[part 1 of 11: packages /CANAnalyzer to /CANAnalyzer/CommunicationClusters]
AUTOSAR XML (schema 00051)
standard types defined: uint16, uint8, uint32, uint64
package /CANAnalyzer
  system CANCommunication: category=SYSTEM_DESCRIPTION, system-version=1.0.0
package /CANAnalyzer/CommunicationClusters
  can cluster CAN_FD_IPB_41
    can physical channel Channel
      frame AnalyticsDataFBD_HL: id 0x2AE, frame-length=48, can-addressing-mode=STANDARD, can-frame-rx-behavior=CAN-FD, can-frame-tx-behavior=CAN-FD
        pdu AnalyticsDataFBD_HL: length=48, unused-bit-pattern=0
          signal AnalyticsDataFBD_HL_Ranging_Uptime: start 0, 16 bit, little-endian, data-type-policy=OVERRIDE, base-type=uint16, compu {phys=raw; unit s}, range phys 0..65532
          signal AnalyticsDataFBD_HL_Ranging_Count: start 16, 16 bit, little-endian, data-type-policy=OVERRIDE, base-type=uint16, compu {phys=raw}, range phys 0..65532
          signal AnalyticsDataFBD_HL_RI_Low_New: start 32, 16 bit, little-endian, data-type-policy=OVERRIDE, base-type=uint16, compu {phys=raw}, range phys 0..65532
          signal AnalyticsDataFBD_HL_RI_Low_Cont: start 48, 16 bit, little-endian, data-type-policy=OVERRIDE, base-type=uint16, compu {phys=raw}, range phys 0..65532
          signal AnalyticsDataFBD_HL_RI_Med_New: start 64, 16 bit, little-endian, data-type-policy=OVERRIDE, base-type=uint16, compu {phys=raw}, range phys 0..65532
          signal AnalyticsDataFBD_HL_RI_Med_Cont: start 80, 16 bit, little-endian, data-type-policy=OVERRIDE, base-type=uint16, compu {phys=raw}, range phys 0..65532
          signal AnalyticsDataFBD_HL_RI_High_New: start 96, 16 bit, little-endian, data-type-policy=OVERRIDE, base-type=uint16, compu {phys=raw}, range phys 0..65532
          signal AnalyticsDataFBD_HL_RI_High_Cont: start 112, 16 bit, little-endian, data-type-policy=OVERRIDE, base-type=uint16, compu {phys=raw}, range phys 0..65532
          signal AnalyticsDataFBD_HL_Ranging_Sessions_Invalid: start 128, 16 bit, little-endian, data-type-policy=OVERRIDE, base-type=uint16, compu {phys=raw}, range phys 0..65532
          signal AnalyticsDataFBD_HL_Ranging_Sessions_FBD_Only_WUT: start 144, 16 bit, little-endian, data-type-policy=OVERRIDE, base-type=uint16, compu {phys=raw}, range phys 0..65532
          signal AnalyticsDataFBD_HL_Ranging_Sessions_FBD_Only_WUT_1: start 160, 16 bit, little-endian, data-type-policy=OVERRIDE, base-type=uint16, compu {phys=raw}, range phys 0..65532
          signal AnalyticsDataFBD_HL_Ranging_Sessions_FBD_Only_WUT_2: start 176, 16 bit, little-endian, data-type-policy=OVERRIDE, base-type=uint16, compu {phys=raw}, range phys 0..65532
          signal AnalyticsDataFBD_HL_Ranging_Sessions_FBD_Only_WUT_3: start 192, 16 bit, little-endian, data-type-policy=OVERRIDE, base-type=uint16, compu {phys=raw}, range phys 0..65532
          signal AnalyticsDataFBD_HL_Ranging_Sessions_FBD_Only_WUT_4: start 208, 16 bit, little-endian, data-type-policy=OVERRIDE, base-type=uint16, compu {phys=raw}, range phys 0..65532
          signal AnalyticsDataFBD_HL_Receive_Window_Ranging_CCC: start 224, 16 bit, little-endian, data-type-policy=OVERRIDE, base-type=uint16, compu {phys=raw*0.1; unit s}, range phys 0..6553.2
          signal AnalyticsDataFBD_HL_Receive_Window_Ranging_IDG: start 240, 16 bit, little-endian, data-type-policy=OVERRIDE, base-type=uint16, compu {phys=raw*0.1; unit s}, range phys 0..6553.2
          signal AnalyticsDataFBD_HL_Receive_Window_CPD: start 256, 16 bit, little-endian, data-type-policy=OVERRIDE, base-type=uint16, compu {phys=raw*0.1; unit s}, range phys 0..6553.2
          signal AnalyticsDataFBD_HL_FDD_Success_UWB: start 272, 16 bit, little-endian, data-type-policy=OVERRIDE, base-type=uint16, compu {phys=raw}, range phys 0..65532
          signal AnalyticsDataFBD_HL_FDD_Success_BLE: start 288, 16 bit, little-endian, data-type-policy=OVERRIDE, base-type=uint16, compu {phys=raw}, range phys 0..65532
          signal AnalyticsDataFBD_HL_RSSI_New: start 304, 16 bit, little-endian, data-type-policy=OVERRIDE, base-type=uint16, compu {phys=raw}, range phys 0..65532
          signal AnalyticsDataFBD_HL_RSSI_Cont: start 320, 16 bit, little-endian, data-type-policy=OVERRIDE, base-type=uint16, compu {phys=raw}, range phys 0..65532
          signal AnalyticsDataFBD_HL_BLE_Localization_Uptime: start 336, 16 bit, little-endian, data-type-policy=OVERRIDE, base-type=uint16, compu {phys=raw}, range phys 0..65532
          signal AnalyticsDataFBD_HL_BLE_Localization_Count: start 352, 16 bit, little-endian, data-type-policy=OVERRIDE, base-type=uint16, compu {phys=raw}, range phys 0..65532
          signal AnalyticsDataFBD_HL_Fallback_Mode_Duration: start 368, 16 bit, little-endian, data-type-policy=OVERRIDE, base-type=uint16, compu {phys=raw}, range phys 0..65532
      frame AnalyticsDataFBD_HM: id 0x2A9, frame-length=48, can-addressing-mode=STANDARD, can-frame-rx-behavior=CAN-FD, can-frame-tx-behavior=CAN-FD
        pdu AnalyticsDataFBD_HM: length=48, unused-bit-pattern=0
          signal AnalyticsDataFBD_HM_Ranging_Uptime: start 0, 16 bit, little-endian, data-type-policy=OVERRIDE, base-type=uint16, compu {phys=raw; unit s}, range phys 0..65532
          signal AnalyticsDataFBD_HM_Ranging_Count: start 16, 16 bit, little-endian, data-type-policy=OVERRIDE, base-type=uint16, compu {phys=raw}, range phys 0..65532
          signal AnalyticsDataFBD_HM_RI_Low_New: start 32, 16 bit, little-endian, data-type-policy=OVERRIDE, base-type=uint16, compu {phys=raw}, range phys 0..65532
          signal AnalyticsDataFBD_HM_RI_Low_Cont: start 48, 16 bit, little-endian, data-type-policy=OVERRIDE, base-type=uint16, compu {phys=raw}, range phys 0..65532
          signal AnalyticsDataFBD_HM_RI_Med_New: start 64, 16 bit, little-endian, data-type-policy=OVERRIDE, base-type=uint16, compu {phys=raw}, range phys 0..65532
          signal AnalyticsDataFBD_HM_RI_Med_Cont: start 80, 16 bit, little-endian, data-type-policy=OVERRIDE, base-type=uint16, compu {phys=raw}, range phys 0..65532
          signal AnalyticsDataFBD_HM_RI_High_New: start 96, 16 bit, little-endian, data-type-policy=OVERRIDE, base-type=uint16, compu {phys=raw}, range phys 0..65532
          signal AnalyticsDataFBD_HM_RI_High_Cont: start 112, 16 bit, little-endian, data-type-policy=OVERRIDE, base-type=uint16, compu {phys=raw}, range phys 0..65532
          signal AnalyticsDataFBD_HM_Ranging_Sessions_Invalid: start 128, 16 bit, little-endian, data-type-policy=OVERRIDE, base-type=uint16, compu {phys=raw}, range phys 0..65532
          signal AnalyticsDataFBD_HM_Ranging_Sessions_FBD_Only_WUT: start 144, 16 bit, little-endian, data-type-policy=OVERRIDE, base-type=uint16, compu {phys=raw}, range phys 0..65532
          signal AnalyticsDataFBD_HM_Ranging_Sessions_FBD_Only_WUT_1: start 160, 16 bit, little-endian, data-type-policy=OVERRIDE, base-type=uint16, compu {phys=raw}, range phys 0..65532
          signal AnalyticsDataFBD_HM_Ranging_Sessions_FBD_Only_WUT_2: start 176, 16 bit, little-endian, data-type-policy=OVERRIDE, base-type=uint16, compu {phys=raw}, range phys 0..65532
          signal AnalyticsDataFBD_HM_Ranging_Sessions_FBD_Only_WUT_3: start 192, 16 bit, little-endian, data-type-policy=OVERRIDE, base-type=uint16, compu {phys=raw}, range phys 0..65532
          signal AnalyticsDataFBD_HM_Ranging_Sessions_FBD_Only_WUT_4: start 208, 16 bit, little-endian, data-type-policy=OVERRIDE, base-type=uint16, compu {phys=raw}, range phys 0..65532
          signal AnalyticsDataFBD_HM_Receive_Window_Ranging_CCC: start 224, 16 bit, little-endian, data-type-policy=OVERRIDE, base-type=uint16, compu {phys=raw*0.1; unit s}, range phys 0..6553.2
          signal AnalyticsDataFBD_HM_Receive_Window_Ranging_IDG: start 240, 16 bit, little-endian, data-type-policy=OVERRIDE, base-type=uint16, compu {phys=raw*0.1; unit s}, range phys 0..6553.2
          signal AnalyticsDataFBD_HM_Receive_Window_CPD: start 256, 16 bit, little-endian, data-type-policy=OVERRIDE, base-type=uint16, compu {phys=raw*0.1; unit s}, range phys 0..6553.2
          signal AnalyticsDataFBD_HM_FDD_Success_UWB: start 272, 16 bit, little-endian, data-type-policy=OVERRIDE, base-type=uint16, compu {phys=raw}, range phys 0..65532
          signal AnalyticsDataFBD_HM_FDD_Success_BLE: start 288, 16 bit, little-endian, data-type-policy=OVERRIDE, base-type=uint16, compu {phys=raw}, range phys 0..65532
          signal AnalyticsDataFBD_HM_RSSI_New: start 304, 16 bit, little-endian, data-type-policy=OVERRIDE, base-type=uint16, compu {phys=raw}, range phys 0..65532
          signal AnalyticsDataFBD_HM_RSSI_Cont: start 320, 16 bit, little-endian, data-type-policy=OVERRIDE, base-type=uint16, compu {phys=raw}, range phys 0..65532
          signal AnalyticsDataFBD_HM_BLE_Localization_Uptime: start 336, 16 bit, little-endian, data-type-policy=OVERRIDE, base-type=uint16, compu {phys=raw}, range phys 0..65532
          signal AnalyticsDataFBD_HM_BLE_Localization_Count: start 352, 16 bit, little-endian, data-type-policy=OVERRIDE, base-type=uint16, compu {phys=raw}, range phys 0..65532
          signal AnalyticsDataFBD_HM_Fallback_Mode_Duration: start 368, 16 bit, little-endian, data-type-policy=OVERRIDE, base-type=uint16, compu {phys=raw}, range phys 0..65532
      frame AnalyticsDataFBD_HR: id 0x2AF, frame-length=48, can-addressing-mode=STANDARD, can-frame-rx-behavior=CAN-FD, can-frame-tx-behavior=CAN-FD
        pdu AnalyticsDataFBD_HR: length=48, unused-bit-pattern=0
          signal AnalyticsDataFBD_HR_Ranging_Uptime: start 0, 16 bit, little-endian, data-type-policy=OVERRIDE, base-type=uint16, compu {phys=raw; unit s}, range phys 0..65532
          signal AnalyticsDataFBD_HR_Ranging_Count: start 16, 16 bit, little-endian, data-type-policy=OVERRIDE, base-type=uint16, compu {phys=raw}, range phys 0..65532
          signal AnalyticsDataFBD_HR_RI_Low_New: start 32, 16 bit, little-endian, data-type-policy=OVERRIDE, base-type=uint16, compu {phys=raw}, range phys 0..65532
          signal AnalyticsDataFBD_HR_RI_Low_Cont: start 48, 16 bit, little-endian, data-type-policy=OVERRIDE, base-type=uint16, compu {phys=raw}, range phys 0..65532
          signal AnalyticsDataFBD_HR_RI_Med_New: start 64, 16 bit, little-endian, data-type-policy=OVERRIDE, base-type=uint16, compu {phys=raw}, range phys 0..65532
          signal AnalyticsDataFBD_HR_RI_Med_Cont: start 80, 16 bit, little-endian, data-type-policy=OVERRIDE, base-type=uint16, compu {phys=raw}, range phys 0..65532
          signal AnalyticsDataFBD_HR_RI_High_New: start 96, 16 bit, little-endian, data-type-policy=OVERRIDE, base-type=uint16, compu {phys=raw}, range phys 0..65532
          signal AnalyticsDataFBD_HR_RI_High_Cont: start 112, 16 bit, little-endian, data-type-policy=OVERRIDE, base-type=uint16, compu {phys=raw}, range phys 0..65532
          signal AnalyticsDataFBD_HR_Ranging_Sessions_Invalid: start 128, 16 bit, little-endian, data-type-policy=OVERRIDE, base-type=uint16, compu {phys=raw}, range phys 0..65532
          signal AnalyticsDataFBD_HR_Ranging_Sessions_FBD_Only_WUT: start 144, 16 bit, little-endian, data-type-policy=OVERRIDE, base-type=uint16, compu {phys=raw}, range phys 0..65532
          signal AnalyticsDataFBD_HR_Ranging_Sessions_FBD_Only_WUT_1: start 160, 16 bit, little-endian, data-type-policy=OVERRIDE, base-type=uint16, compu {phys=raw}, range phys 0..65532
          signal AnalyticsDataFBD_HR_Ranging_Sessions_FBD_Only_WUT_2: start 176, 16 bit, little-endian, data-type-policy=OVERRIDE, base-type=uint16, compu {phys=raw}, range phys 0..65532
          signal AnalyticsDataFBD_HR_Ranging_Sessions_FBD_Only_WUT_3: start 192, 16 bit, little-endian, data-type-policy=OVERRIDE, base-type=uint16, compu {phys=raw}, range phys 0..65532
          signal AnalyticsDataFBD_HR_Ranging_Sessions_FBD_Only_WUT_4: start 208, 16 bit, little-endian, data-type-policy=OVERRIDE, base-type=uint16, compu {phys=raw}, range phys 0..65532
          signal AnalyticsDataFBD_HR_Receive_Window_Ranging_CCC: start 224, 16 bit, little-endian, data-type-policy=OVERRIDE, base-type=uint16, compu {phys=raw*0.1; unit s}, range phys 0..6553.2
          signal AnalyticsDataFBD_HR_Receive_Window_Ranging_IDG: start 240, 16 bit, little-endian, data-type-policy=OVERRIDE, base-type=uint16, compu {phys=raw*0.1; unit s}, range phys 0..6553.2
          signal AnalyticsDataFBD_HR_Receive_Window_CPD: start 256, 16 bit, little-endian, data-type-policy=OVERRIDE, base-type=uint16, compu {phys=raw*0.1; unit s}, range phys 0..6553.2
          signal AnalyticsDataFBD_HR_FDD_Success_UWB: start 272, 16 bit, little-endian, data-type-policy=OVERRIDE, base-type=uint16, compu {phys=raw}, range phys 0..65532
          signal AnalyticsDataFBD_HR_FDD_Success_BLE: start 288, 16 bit, little-endian, data-type-policy=OVERRIDE, base-type=uint16, compu {phys=raw}, range phys 0..65532
          signal AnalyticsDataFBD_HR_RSSI_New: start 304, 16 bit, little-endian, data-type-policy=OVERRIDE, base-type=uint16, compu {phys=raw}, range phys 0..65532
          signal AnalyticsDataFBD_HR_RSSI_Cont: start 320, 16 bit, little-endian, data-type-policy=OVERRIDE, base-type=uint16, compu {phys=raw}, range phys 0..65532
          signal AnalyticsDataFBD_HR_BLE_Localization_Uptime: start 336, 16 bit, little-endian, data-type-policy=OVERRIDE, base-type=uint16, compu {phys=raw}, range phys 0..65532
          signal AnalyticsDataFBD_HR_BLE_Localization_Count: start 352, 16 bit, little-endian, data-type-policy=OVERRIDE, base-type=uint16, compu {phys=raw}, range phys 0..65532
          signal AnalyticsDataFBD_HR_Fallback_Mode_Duration: start 368, 16 bit, little-endian, data-type-policy=OVERRIDE, base-type=uint16, compu {phys=raw}, range phys 0..65532
      frame AnalyticsDataFBD_Miko: id 0x2AA, frame-length=48, can-addressing-mode=STANDARD, can-frame-rx-behavior=CAN-FD, can-frame-tx-behavior=CAN-FD
        pdu AnalyticsDataFBD_Miko: length=48, unused-bit-pattern=0
          signal AnalyticsDataFBD_Miko_Ranging_Uptime: start 0, 16 bit, little-endian, data-type-policy=OVERRIDE, base-type=uint16, compu {phys=raw; unit s}, range phys 0..65532
          signal AnalyticsDataFBD_Miko_Ranging_Count: start 16, 16 bit, little-endian, data-type-policy=OVERRIDE, base-type=uint16, compu {phys=raw}, range phys 0..65532
          signal AnalyticsDataFBD_Miko_RI_Low_New: start 32, 16 bit, little-endian, data-type-policy=OVERRIDE, base-type=uint16, compu {phys=raw}, range phys 0..65532
          signal AnalyticsDataFBD_Miko_RI_Low_Cont: start 48, 16 bit, little-endian, data-type-policy=OVERRIDE, base-type=uint16, compu {phys=raw}, range phys 0..65532
          signal AnalyticsDataFBD_Miko_RI_Med_New: start 64, 16 bit, little-endian, data-type-policy=OVERRIDE, base-type=uint16, compu {phys=raw}, range phys 0..65532
          signal AnalyticsDataFBD_Miko_RI_Med_Cont: start 80, 16 bit, little-endian, data-type-policy=OVERRIDE, base-type=uint16, compu {phys=raw}, range phys 0..65532
          signal AnalyticsDataFBD_Miko_RI_High_New: start 96, 16 bit, little-endian, data-type-policy=OVERRIDE, base-type=uint16, compu {phys=raw}, range phys 0..65532
          signal AnalyticsDataFBD_Miko_RI_High_Cont: start 112, 16 bit, little-endian, data-type-policy=OVERRIDE, base-type=uint16, compu {phys=raw}, range phys 0..65532
          signal AnalyticsDataFBD_Miko_Ranging_Sessions_Invalid: start 128, 16 bit, little-endian, data-type-policy=OVERRIDE, base-type=uint16, compu {phys=raw}, range phys 0..65532
          signal AnalyticsDataFBD_Miko_Ranging_Sessions_FBD_Only_WUT: start 144, 16 bit, little-endian, data-type-policy=OVERRIDE, base-type=uint16, compu {phys=raw}, range phys 0..65532
          signal AnalyticsDataFBD_Miko_Ranging_Sessions_FBD_Only_WUT_1: start 160, 16 bit, little-endian, data-type-policy=OVERRIDE, base-type=uint16, compu {phys=raw}, range phys 0..65532
          signal AnalyticsDataFBD_Miko_Ranging_Sessions_FBD_Only_WUT_2: start 176, 16 bit, little-endian, data-type-policy=OVERRIDE, base-type=uint16, compu {phys=raw}, range phys 0..65532
          signal AnalyticsDataFBD_Miko_Ranging_Sessions_FBD_Only_WUT_3: start 192, 16 bit, little-endian, data-type-policy=OVERRIDE, base-type=uint16, compu {phys=raw}, range phys 0..65532
          signal AnalyticsDataFBD_Miko_Ranging_Sessions_FBD_Only_WUT_4: start 208, 16 bit, little-endian, data-type-policy=OVERRIDE, base-type=uint16, compu {phys=raw}, range phys 0..65532
          signal AnalyticsDataFBD_Miko_Receive_Window_Ranging_CCC: start 224, 16 bit, little-endian, data-type-policy=OVERRIDE, base-type=uint16, compu {phys=raw*0.1; unit s}, range phys 0..6553.2
          signal AnalyticsDataFBD_Miko_Receive_Window_Ranging_IDG: start 240, 16 bit, little-endian, data-type-policy=OVERRIDE, base-type=uint16, compu {phys=raw*0.1; unit s}, range phys 0..6553.2
          signal AnalyticsDataFBD_Miko_Receive_Window_CPD: start 256, 16 bit, little-endian, data-type-policy=OVERRIDE, base-type=uint16, compu {phys=raw*0.1; unit s}, range phys 0..6553.2
          signal AnalyticsDataFBD_Miko_FDD_Success_UWB: start 272, 16 bit, little-endian, data-type-policy=OVERRIDE, base-type=uint16, compu {phys=raw}, range phys 0..65532
          signal AnalyticsDataFBD_Miko_FDD_Success_BLE: start 288, 16 bit, little-endian, data-type-policy=OVERRIDE, base-type=uint16, compu {phys=raw}, range phys 0..65532
          signal AnalyticsDataFBD_Miko_RSSI_New: start 304, 16 bit, little-endian, data-type-policy=OVERRIDE, base-type=uint16, compu {phys=raw}, range phys 0..65532
          signal AnalyticsDataFBD_Miko_RSSI_Cont: start 320, 16 bit, little-endian, data-type-policy=OVERRIDE, base-type=uint16, compu {phys=raw}, range phys 0..65532
          signal AnalyticsDataFBD_Miko_BLE_Localization_Uptime: start 336, 16 bit, little-endian, data-type-policy=OVERRIDE, base-type=uint16, compu {phys=raw}, range phys 0..65532
          signal AnalyticsDataFBD_Miko_BLE_Localization_Count: start 352, 16 bit, little-endian, data-type-policy=OVERRIDE, base-type=uint16, compu {phys=raw}, range phys 0..65532
          signal AnalyticsDataFBD_Miko_Fallback_Mode_Duration: start 368, 16 bit, little-endian, data-type-policy=OVERRIDE, base-type=uint16, compu {phys=raw}, range phys 0..65532
      frame AnalyticsDataFBD_MM: id 0x2B2, frame-length=48, can-addressing-mode=STANDARD, can-frame-rx-behavior=CAN-FD, can-frame-tx-behavior=CAN-FD
        pdu AnalyticsDataFBD_MM: length=48, unused-bit-pattern=0
          signal AnalyticsDataFBD_MM_Ranging_Uptime: start 0, 16 bit, little-endian, data-type-policy=OVERRIDE, base-type=uint16, compu {phys=raw; unit s}, range phys 0..65532
          signal AnalyticsDataFBD_MM_Ranging_Count: start 16, 16 bit, little-endian, data-type-policy=OVERRIDE, base-type=uint16, compu {phys=raw}, range phys 0..65532
          signal AnalyticsDataFBD_MM_RI_Low_New: start 32, 16 bit, little-endian, data-type-policy=OVERRIDE, base-type=uint16, compu {phys=raw}, range phys 0..65532
          signal AnalyticsDataFBD_MM_RI_Low_Cont: start 48, 16 bit, little-endian, data-type-policy=OVERRIDE, base-type=uint16, compu {phys=raw}, range phys 0..65532
          signal AnalyticsDataFBD_MM_RI_Med_New: start 64, 16 bit, little-endian, data-type-policy=OVERRIDE, base-type=uint16, compu {phys=raw}, range phys 0..65532
          signal AnalyticsDataFBD_MM_RI_Med_Cont: start 80, 16 bit, little-endian, data-type-policy=OVERRIDE, base-type=uint16, compu {phys=raw}, range phys 0..65532
          signal AnalyticsDataFBD_MM_RI_High_New: start 96, 16 bit, little-endian, data-type-policy=OVERRIDE, base-type=uint16, compu {phys=raw}, range phys 0..65532
          signal AnalyticsDataFBD_MM_RI_High_Cont: start 112, 16 bit, little-endian, data-type-policy=OVERRIDE, base-type=uint16, compu {phys=raw}, range phys 0..65532
          signal AnalyticsDataFBD_MM_Ranging_Sessions_Invalid: start 128, 16 bit, little-endian, data-type-policy=OVERRIDE, base-type=uint16, compu {phys=raw}, range phys 0..65532
          signal AnalyticsDataFBD_MM_Ranging_Sessions_FBD_Only_WUT: start 144, 16 bit, little-endian, data-type-policy=OVERRIDE, base-type=uint16, compu {phys=raw}, range phys 0..65532
          signal AnalyticsDataFBD_MM_Ranging_Sessions_FBD_Only_WUT_1: start 160, 16 bit, little-endian, data-type-policy=OVERRIDE, base-type=uint16, compu {phys=raw}, range phys 0..65532
          signal AnalyticsDataFBD_MM_Ranging_Sessions_FBD_Only_WUT_2: start 176, 16 bit, little-endian, data-type-policy=OVERRIDE, base-type=uint16, compu {phys=raw}, range phys 0..65532
          signal AnalyticsDataFBD_MM_Ranging_Sessions_FBD_Only_WUT_3: start 192, 16 bit, little-endian, data-type-policy=OVERRIDE, base-type=uint16, compu {phys=raw}, range phys 0..65532
          signal AnalyticsDataFBD_MM_Ranging_Sessions_FBD_Only_WUT_4: start 208, 16 bit, little-endian, data-type-policy=OVERRIDE, base-type=uint16, compu {phys=raw}, range phys 0..65532
          signal AnalyticsDataFBD_MM_Receive_Window_Ranging_CCC: start 224, 16 bit, little-endian, data-type-policy=OVERRIDE, base-type=uint16, compu {phys=raw*0.1; unit s}, range phys 0..6553.2
          signal AnalyticsDataFBD_MM_Receive_Window_Ranging_IDG: start 240, 16 bit, little-endian, data-type-policy=OVERRIDE, base-type=uint16, compu {phys=raw*0.1; unit s}, range phys 0..6553.2
          signal AnalyticsDataFBD_MM_Receive_Window_CPD: start 256, 16 bit, little-endian, data-type-policy=OVERRIDE, base-type=uint16, compu {phys=raw*0.1; unit s}, range phys 0..6553.2
          signal AnalyticsDataFBD_MM_FDD_Success_UWB: start 272, 16 bit, little-endian, data-type-policy=OVERRIDE, base-type=uint16, compu {phys=raw}, range phys 0..65532
          signal AnalyticsDataFBD_MM_FDD_Success_BLE: start 288, 16 bit, little-endian, data-type-policy=OVERRIDE, base-type=uint16, compu {phys=raw}, range phys 0..65532
          signal AnalyticsDataFBD_MM_RSSI_New: start 304, 16 bit, little-endian, data-type-policy=OVERRIDE, base-type=uint16, compu {phys=raw}, range phys 0..65532
          signal AnalyticsDataFBD_MM_RSSI_Cont: start 320, 16 bit, little-endian, data-type-policy=OVERRIDE, base-type=uint16, compu {phys=raw}, range phys 0..65532
          signal AnalyticsDataFBD_MM_BLE_Localization_Uptime: start 336, 16 bit, little-endian, data-type-policy=OVERRIDE, base-type=uint16, compu {phys=raw}, range phys 0..65532
          signal AnalyticsDataFBD_MM_BLE_Localization_Count: start 352, 16 bit, little-endian, data-type-policy=OVERRIDE, base-type=uint16, compu {phys=raw}, range phys 0..65532
          signal AnalyticsDataFBD_MM_Fallback_Mode_Duration: start 368, 16 bit, little-endian, data-type-policy=OVERRIDE, base-type=uint16, compu {phys=raw}, range phys 0..65532
      frame AnalyticsDataFBD_Trunk: id 0x2AB, frame-length=48, can-addressing-mode=STANDARD, can-frame-rx-behavior=CAN-FD, can-frame-tx-behavior=CAN-FD
        pdu AnalyticsDataFBD_Trunk: length=48, unused-bit-pattern=0
          signal AnalyticsDataFBD_Trunk_Ranging_Uptime: start 0, 16 bit, little-endian, data-type-policy=OVERRIDE, base-type=uint16, compu {phys=raw; unit s}, range phys 0..65532
          signal AnalyticsDataFBD_Trunk_Ranging_Count: start 16, 16 bit, little-endian, data-type-policy=OVERRIDE, base-type=uint16, compu {phys=raw}, range phys 0..65532
          signal AnalyticsDataFBD_Trunk_RI_Low_New: start 32, 16 bit, little-endian, data-type-policy=OVERRIDE, base-type=uint16, compu {phys=raw}, range phys 0..65532
          signal AnalyticsDataFBD_Trunk_RI_Low_Cont: start 48, 16 bit, little-endian, data-type-policy=OVERRIDE, base-type=uint16, compu {phys=raw}, range phys 0..65532
          signal AnalyticsDataFBD_Trunk_RI_Med_New: start 64, 16 bit, little-endian, data-type-policy=OVERRIDE, base-type=uint16, compu {phys=raw}, range phys 0..65532
          signal AnalyticsDataFBD_Trunk_RI_Med_Cont: start 80, 16 bit, little-endian, data-type-policy=OVERRIDE, base-type=uint16, compu {phys=raw}, range phys 0..65532
          signal AnalyticsDataFBD_Trunk_RI_High_New: start 96, 16 bit, little-endian, data-type-policy=OVERRIDE, base-type=uint16, compu {phys=raw}, range phys 0..65532
          signal AnalyticsDataFBD_Trunk_RI_High_Cont: start 112, 16 bit, little-endian, data-type-policy=OVERRIDE, base-type=uint16, compu {phys=raw}, range phys 0..65532
          signal AnalyticsDataFBD_Trunk_Ranging_Sessions_Invalid: start 128, 16 bit, little-endian, data-type-policy=OVERRIDE, base-type=uint16, compu {phys=raw}, range phys 0..65532
          signal AnalyticsDataFBD_Trunk_Ranging_Sessions_FBD_Only_WUT: start 144, 16 bit, little-endian, data-type-policy=OVERRIDE, base-type=uint16, compu {phys=raw}, range phys 0..65532
          signal AnalyticsDataFBD_Trunk_Ranging_Sessions_FBD_Only_WUT_1: start 160, 16 bit, little-endian, data-type-policy=OVERRIDE, base-type=uint16, compu {phys=raw}, range phys 0..65532
          signal AnalyticsDataFBD_Trunk_Ranging_Sessions_FBD_Only_WUT_2: start 176, 16 bit, little-endian, data-type-policy=OVERRIDE, base-type=uint16, compu {phys=raw}, range phys 0..65532
          signal AnalyticsDataFBD_Trunk_Ranging_Sessions_FBD_Only_WUT_3: start 192, 16 bit, little-endian, data-type-policy=OVERRIDE, base-type=uint16, compu {phys=raw}, range phys 0..65532
          signal AnalyticsDataFBD_Trunk_Ranging_Sessions_FBD_Only_WUT_4: start 208, 16 bit, little-endian, data-type-policy=OVERRIDE, base-type=uint16, compu {phys=raw}, range phys 0..65532
          signal AnalyticsDataFBD_Trunk_Receive_Window_Ranging_CCC: start 224, 16 bit, little-endian, data-type-policy=OVERRIDE, base-type=uint16, compu {phys=raw*0.1; unit s}, range phys 0..6553.2
          signal AnalyticsDataFBD_Trunk_Receive_Window_Ranging_IDG: start 240, 16 bit, little-endian, data-type-policy=OVERRIDE, base-type=uint16, compu {phys=raw*0.1; unit s}, range phys 0..6553.2
          signal AnalyticsDataFBD_Trunk_Receive_Window_CPD: start 256, 16 bit, little-endian, data-type-policy=OVERRIDE, base-type=uint16, compu {phys=raw*0.1; unit s}, range phys 0..6553.2
          signal AnalyticsDataFBD_Trunk_FDD_Success_UWB: start 272, 16 bit, little-endian, data-type-policy=OVERRIDE, base-type=uint16, compu {phys=raw}, range phys 0..65532
          signal AnalyticsDataFBD_Trunk_FDD_Success_BLE: start 288, 16 bit, little-endian, data-type-policy=OVERRIDE, base-type=uint16, compu {phys=raw}, range phys 0..65532
          signal AnalyticsDataFBD_Trunk_RSSI_New: start 304, 16 bit, little-endian, data-type-policy=OVERRIDE, base-type=uint16, compu {phys=raw}, range phys 0..65532
          signal AnalyticsDataFBD_Trunk_RSSI_Cont: start 320, 16 bit, little-endian, data-type-policy=OVERRIDE, base-type=uint16, compu {phys=raw}, range phys 0..65532
          signal AnalyticsDataFBD_Trunk_BLE_Localization_Uptime: start 336, 16 bit, little-endian, data-type-policy=OVERRIDE, base-type=uint16, compu {phys=raw}, range phys 0..65532
          signal AnalyticsDataFBD_Trunk_BLE_Localization_Count: start 352, 16 bit, little-endian, data-type-policy=OVERRIDE, base-type=uint16, compu {phys=raw}, range phys 0..65532
          signal AnalyticsDataFBD_Trunk_Fallback_Mode_Duration: start 368, 16 bit, little-endian, data-type-policy=OVERRIDE, base-type=uint16, compu {phys=raw}, range phys 0..65532
      frame AnalyticsDataFBD_VL: id 0x2AC, frame-length=48, can-addressing-mode=STANDARD, can-frame-rx-behavior=CAN-FD, can-frame-tx-behavior=CAN-FD
        pdu AnalyticsDataFBD_VL: length=48, unused-bit-pattern=0
          signal AnalyticsDataFBD_VL_Ranging_Uptime: start 0, 16 bit, little-endian, data-type-policy=OVERRIDE, base-type=uint16, compu {phys=raw; unit s}, range phys 0..65532
          signal AnalyticsDataFBD_VL_Ranging_Count: start 16, 16 bit, little-endian, data-type-policy=OVERRIDE, base-type=uint16, compu {phys=raw}, range phys 0..65532
          signal AnalyticsDataFBD_VL_RI_Low_New: start 32, 16 bit, little-endian, data-type-policy=OVERRIDE, base-type=uint16, compu {phys=raw}, range phys 0..65532
          signal AnalyticsDataFBD_VL_RI_Low_Cont: start 48, 16 bit, little-endian, data-type-policy=OVERRIDE, base-type=uint16, compu {phys=raw}, range phys 0..65532
          signal AnalyticsDataFBD_VL_RI_Med_New: start 64, 16 bit, little-endian, data-type-policy=OVERRIDE, base-type=uint16, compu {phys=raw}, range phys 0..65532
          signal AnalyticsDataFBD_VL_RI_Med_Cont: start 80, 16 bit, little-endian, data-type-policy=OVERRIDE, base-type=uint16, compu {phys=raw}, range phys 0..65532
          signal AnalyticsDataFBD_VL_RI_High_New: start 96, 16 bit, little-endian, data-type-policy=OVERRIDE, base-type=uint16, compu {phys=raw}, range phys 0..65532
          signal AnalyticsDataFBD_VL_RI_High_Cont: start 112, 16 bit, little-endian, data-type-policy=OVERRIDE, base-type=uint16, compu {phys=raw}, range phys 0..65532
          signal AnalyticsDataFBD_VL_Ranging_Sessions_Invalid: start 128, 16 bit, little-endian, data-type-policy=OVERRIDE, base-type=uint16, compu {phys=raw}, range phys 0..65532
          signal AnalyticsDataFBD_VL_Ranging_Sessions_FBD_Only_WUT: start 144, 16 bit, little-endian, data-type-policy=OVERRIDE, base-type=uint16, compu {phys=raw}, range phys 0..65532
          signal AnalyticsDataFBD_VL_Ranging_Sessions_FBD_Only_WUT_1: start 160, 16 bit, little-endian, data-type-policy=OVERRIDE, base-type=uint16, compu {phys=raw}, range phys 0..65532
          signal AnalyticsDataFBD_VL_Ranging_Sessions_FBD_Only_WUT_2: start 176, 16 bit, little-endian, data-type-policy=OVERRIDE, base-type=uint16, compu {phys=raw}, range phys 0..65532
          signal AnalyticsDataFBD_VL_Ranging_Sessions_FBD_Only_WUT_3: start 192, 16 bit, little-endian, data-type-policy=OVERRIDE, base-type=uint16, compu {phys=raw}, range phys 0..65532
          signal AnalyticsDataFBD_VL_Ranging_Sessions_FBD_Only_WUT_4: start 208, 16 bit, little-endian, data-type-policy=OVERRIDE, base-type=uint16, compu {phys=raw}, range phys 0..65532
          signal AnalyticsDataFBD_VL_Receive_Window_Ranging_CCC: start 224, 16 bit, little-endian, data-type-policy=OVERRIDE, base-type=uint16, compu {phys=raw*0.1; unit s}, range phys 0..6553.2
          signal AnalyticsDataFBD_VL_Receive_Window_Ranging_IDG: start 240, 16 bit, little-endian, data-type-policy=OVERRIDE, base-type=uint16, compu {phys=raw*0.1; unit s}, range phys 0..6553.2
          signal AnalyticsDataFBD_VL_Receive_Window_CPD: start 256, 16 bit, little-endian, data-type-policy=OVERRIDE, base-type=uint16, compu {phys=raw*0.1; unit s}, range phys 0..6553.2
          signal AnalyticsDataFBD_VL_FDD_Success_UWB: start 272, 16 bit, little-endian, data-type-policy=OVERRIDE, base-type=uint16, compu {phys=raw}, range phys 0..65532
          signal AnalyticsDataFBD_VL_FDD_Success_BLE: start 288, 16 bit, little-endian, data-type-policy=OVERRIDE, base-type=uint16, compu {phys=raw}, range phys 0..65532
          signal AnalyticsDataFBD_VL_RSSI_New: start 304, 16 bit, little-endian, data-type-policy=OVERRIDE, base-type=uint16, compu {phys=raw}, range phys 0..65532
          signal AnalyticsDataFBD_VL_RSSI_Cont: start 320, 16 bit, little-endian, data-type-policy=OVERRIDE, base-type=uint16, compu {phys=raw}, range phys 0..65532
          signal AnalyticsDataFBD_VL_BLE_Localization_Uptime: start 336, 16 bit, little-endian, data-type-policy=OVERRIDE, base-type=uint16, compu {phys=raw}, range phys 0..65532
          signal AnalyticsDataFBD_VL_BLE_Localization_Count: start 352, 16 bit, little-endian, data-type-policy=OVERRIDE, base-type=uint16, compu {phys=raw}, range phys 0..65532
          signal AnalyticsDataFBD_VL_Fallback_Mode_Duration: start 368, 16 bit, little-endian, data-type-policy=OVERRIDE, base-type=uint16, compu {phys=raw}, range phys 0..65532
      frame AnalyticsDataFBD_VM: id 0x2A8, frame-length=48, can-addressing-mode=STANDARD, can-frame-rx-behavior=CAN-FD, can-frame-tx-behavior=CAN-FD
        pdu AnalyticsDataFBD_VM: length=48, unused-bit-pattern=0
          signal AnalyticsDataFBD_VM_Ranging_Uptime: start 0, 16 bit, little-endian, data-type-policy=OVERRIDE, base-type=uint16, compu {phys=raw; unit s}, range phys 0..65532
          signal AnalyticsDataFBD_VM_Ranging_Count: start 16, 16 bit, little-endian, data-type-policy=OVERRIDE, base-type=uint16, compu {phys=raw}, range phys 0..65532
          signal AnalyticsDataFBD_VM_RI_Low_New: start 32, 16 bit, little-endian, data-type-policy=OVERRIDE, base-type=uint16, compu {phys=raw}, range phys 0..65532
          signal AnalyticsDataFBD_VM_RI_Low_Cont: start 48, 16 bit, little-endian, data-type-policy=OVERRIDE, base-type=uint16, compu {phys=raw}, range phys 0..65532
          signal AnalyticsDataFBD_VM_RI_Med_New: start 64, 16 bit, little-endian, data-type-policy=OVERRIDE, base-type=uint16, compu {phys=raw}, range phys 0..65532
          signal AnalyticsDataFBD_VM_RI_Med_Cont: start 80, 16 bit, little-endian, data-type-policy=OVERRIDE, base-type=uint16, compu {phys=raw}, range phys 0..65532
          signal AnalyticsDataFBD_VM_RI_High_New: start 96, 16 bit, little-endian, data-type-policy=OVERRIDE, base-type=uint16, compu {phys=raw}, range phys 0..65532
          signal AnalyticsDataFBD_VM_RI_High_Cont: start 112, 16 bit, little-endian, data-type-policy=OVERRIDE, base-type=uint16, compu {phys=raw}, range phys 0..65532
          signal AnalyticsDataFBD_VM_Ranging_Sessions_Invalid: start 128, 16 bit, little-endian, data-type-policy=OVERRIDE, base-type=uint16, compu {phys=raw}, range phys 0..65532
          signal AnalyticsDataFBD_VM_Ranging_Sessions_FBD_Only_WUT: start 144, 16 bit, little-endian, data-type-policy=OVERRIDE, base-type=uint16, compu {phys=raw}, range phys 0..65532
          signal AnalyticsDataFBD_VM_Ranging_Sessions_FBD_Only_WUT_1: start 160, 16 bit, little-endian, data-type-policy=OVERRIDE, base-type=uint16, compu {phys=raw}, range phys 0..65532
          signal AnalyticsDataFBD_VM_Ranging_Sessions_FBD_Only_WUT_2: start 176, 16 bit, little-endian, data-type-policy=OVERRIDE, base-type=uint16, compu {phys=raw}, range phys 0..65532
          signal AnalyticsDataFBD_VM_Ranging_Sessions_FBD_Only_WUT_3: start 192, 16 bit, little-endian, data-type-policy=OVERRIDE, base-type=uint16, compu {phys=raw}, range phys 0..65532
          signal AnalyticsDataFBD_VM_Ranging_Sessions_FBD_Only_WUT_4: start 208, 16 bit, little-endian, data-type-policy=OVERRIDE, base-type=uint16, compu {phys=raw}, range phys 0..65532
          signal AnalyticsDataFBD_VM_Receive_Window_Ranging_CCC: start 224, 16 bit, little-endian, data-type-policy=OVERRIDE, base-type=uint16, compu {phys=raw*0.1; unit s}, range phys 0..6553.2
          signal AnalyticsDataFBD_VM_Receive_Window_Ranging_IDG: start 240, 16 bit, little-endian, data-type-policy=OVERRIDE, base-type=uint16, compu {phys=raw*0.1; unit s}, range phys 0..6553.2
          signal AnalyticsDataFBD_VM_Receive_Window_CPD: start 256, 16 bit, little-endian, data-type-policy=OVERRIDE, base-type=uint16, compu {phys=raw*0.1; unit s}, range phys 0..6553.2
          signal AnalyticsDataFBD_VM_FDD_Success_UWB: start 272, 16 bit, little-endian, data-type-policy=OVERRIDE, base-type=uint16, compu {phys=raw}, range phys 0..65532
          signal AnalyticsDataFBD_VM_FDD_Success_BLE: start 288, 16 bit, little-endian, data-type-policy=OVERRIDE, base-type=uint16, compu {phys=raw}, range phys 0..65532
          signal AnalyticsDataFBD_VM_RSSI_New: start 304, 16 bit, little-endian, data-type-policy=OVERRIDE, base-type=uint16, compu {phys=raw}, range phys 0..65532
          signal AnalyticsDataFBD_VM_RSSI_Cont: start 320, 16 bit, little-endian, data-type-policy=OVERRIDE, base-type=uint16, compu {phys=raw}, range phys 0..65532
          signal AnalyticsDataFBD_VM_BLE_Localization_Uptime: start 336, 16 bit, little-endian, data-type-policy=OVERRIDE, base-type=uint16, compu {phys=raw}, range phys 0..65532
          signal AnalyticsDataFBD_VM_BLE_Localization_Count: start 352, 16 bit, little-endian, data-type-policy=OVERRIDE, base-type=uint16, compu {phys=raw}, range phys 0..65532
          signal AnalyticsDataFBD_VM_Fallback_Mode_Duration: start 368, 16 bit, little-endian, data-type-policy=OVERRIDE, base-type=uint16, compu {phys=raw}, range phys 0..65532
      frame AnalyticsDataFBD_VR: id 0x2AD, frame-length=48, can-addressing-mode=STANDARD, can-frame-rx-behavior=CAN-FD, can-frame-tx-behavior=CAN-FD
        pdu AnalyticsDataFBD_VR: length=48, unused-bit-pattern=0
          signal AnalyticsDataFBD_VR_Ranging_Uptime: start 0, 16 bit, little-endian, data-type-policy=OVERRIDE, base-type=uint16, compu {phys=raw; unit s}, range phys 0..65532
          signal AnalyticsDataFBD_VR_Ranging_Count: start 16, 16 bit, little-endian, data-type-policy=OVERRIDE, base-type=uint16, compu {phys=raw}, range phys 0..65532
          signal AnalyticsDataFBD_VR_RI_Low_New: start 32, 16 bit, little-endian, data-type-policy=OVERRIDE, base-type=uint16, compu {phys=raw}, range phys 0..65532
          signal AnalyticsDataFBD_VR_RI_Low_Cont: start 48, 16 bit, little-endian, data-type-policy=OVERRIDE, base-type=uint16, compu {phys=raw}, range phys 0..65532
          signal AnalyticsDataFBD_VR_RI_Med_New: start 64, 16 bit, little-endian, data-type-policy=OVERRIDE, base-type=uint16, compu {phys=raw}, range phys 0..65532
          signal AnalyticsDataFBD_VR_RI_Med_Cont: start 80, 16 bit, little-endian, data-type-policy=OVERRIDE, base-type=uint16, compu {phys=raw}, range phys 0..65532
          signal AnalyticsDataFBD_VR_RI_High_New: start 96, 16 bit, little-endian, data-type-policy=OVERRIDE, base-type=uint16, compu {phys=raw}, range phys 0..65532
          signal AnalyticsDataFBD_VR_RI_High_Cont: start 112, 16 bit, little-endian, data-type-policy=OVERRIDE, base-type=uint16, compu {phys=raw}, range phys 0..65532
          signal AnalyticsDataFBD_VR_Ranging_Sessions_Invalid: start 128, 16 bit, little-endian, data-type-policy=OVERRIDE, base-type=uint16, compu {phys=raw}, range phys 0..65532
          signal AnalyticsDataFBD_VR_Ranging_Sessions_FBD_Only_WUT: start 144, 16 bit, little-endian, data-type-policy=OVERRIDE, base-type=uint16, compu {phys=raw}, range phys 0..65532
          signal AnalyticsDataFBD_VR_Ranging_Sessions_FBD_Only_WUT_1: start 160, 16 bit, little-endian, data-type-policy=OVERRIDE, base-type=uint16, compu {phys=raw}, range phys 0..65532
          signal AnalyticsDataFBD_VR_Ranging_Sessions_FBD_Only_WUT_2: start 176, 16 bit, little-endian, data-type-policy=OVERRIDE, base-type=uint16, compu {phys=raw}, range phys 0..65532
          signal AnalyticsDataFBD_VR_Ranging_Sessions_FBD_Only_WUT_3: start 192, 16 bit, little-endian, data-type-policy=OVERRIDE, base-type=uint16, compu {phys=raw}, range phys 0..65532
          signal AnalyticsDataFBD_VR_Ranging_Sessions_FBD_Only_WUT_4: start 208, 16 bit, little-endian, data-type-policy=OVERRIDE, base-type=uint16, compu {phys=raw}, range phys 0..65532
          signal AnalyticsDataFBD_VR_Receive_Window_Ranging_CCC: start 224, 16 bit, little-endian, data-type-policy=OVERRIDE, base-type=uint16, compu {phys=raw*0.1; unit s}, range phys 0..6553.2
          signal AnalyticsDataFBD_VR_Receive_Window_Ranging_IDG: start 240, 16 bit, little-endian, data-type-policy=OVERRIDE, base-type=uint16, compu {phys=raw*0.1; unit s}, range phys 0..6553.2
          signal AnalyticsDataFBD_VR_Receive_Window_CPD: start 256, 16 bit, little-endian, data-type-policy=OVERRIDE, base-type=uint16, compu {phys=raw*0.1; unit s}, range phys 0..6553.2
          signal AnalyticsDataFBD_VR_FDD_Success_UWB: start 272, 16 bit, little-endian, data-type-policy=OVERRIDE, base-type=uint16, compu {phys=raw}, range phys 0..65532
          signal AnalyticsDataFBD_VR_FDD_Success_BLE: start 288, 16 bit, little-endian, data-type-policy=OVERRIDE, base-type=uint16, compu {phys=raw}, range phys 0..65532
          signal AnalyticsDataFBD_VR_RSSI_New: start 304, 16 bit, little-endian, data-type-policy=OVERRIDE, base-type=uint16, compu {phys=raw}, range phys 0..65532
          signal AnalyticsDataFBD_VR_RSSI_Cont: start 320, 16 bit, little-endian, data-type-policy=OVERRIDE, base-type=uint16, compu {phys=raw}, range phys 0..65532
          signal AnalyticsDataFBD_VR_BLE_Localization_Uptime: start 336, 16 bit, little-endian, data-type-policy=OVERRIDE, base-type=uint16, compu {phys=raw}, range phys 0..65532
          signal AnalyticsDataFBD_VR_BLE_Localization_Count: start 352, 16 bit, little-endian, data-type-policy=OVERRIDE, base-type=uint16, compu {phys=raw}, range phys 0..65532
          signal AnalyticsDataFBD_VR_Fallback_Mode_Duration: start 368, 16 bit, little-endian, data-type-policy=OVERRIDE, base-type=uint16, compu {phys=raw}, range phys 0..65532
      frame AnalyticsDataRequest: id 0x25F, frame-length=8, can-addressing-mode=STANDARD, can-frame-rx-behavior=CAN-20, can-frame-tx-behavior=CAN-20
        pdu AnalyticsDataRequest: length=8, unused-bit-pattern=0
          signal AnalyticsDataRequest_Address: start 0, 16 bit, little-endian, data-type-policy=OVERRIDE, compu {phys=raw}
          signal AnalyticsDataRequest_RequestData: start 16, 8 bit, little-endian, data-type-policy=OVERRIDE, base-type=uint8, compu {phys=raw}, range phys 0..252
      frame ControlBindingFBD: id 0x25D, frame-length=64, can-addressing-mode=STANDARD, can-frame-rx-behavior=CAN-FD, can-frame-tx-behavior=CAN-FD
        pdu ControlBindingFBD: length=64, unused-bit-pattern=0
          signal ControlBindingFBD_Address: start 0, 16 bit, little-endian, data-type-policy=OVERRIDE, compu {phys=raw}
          signal ControlBindingFBD_BindingSequence: start 16, 8 bit, little-endian, data-type-policy=OVERRIDE, base-type=uint8, compu {phys=raw}, range phys 0..252
          signal ControlBindingFBD_Data00: start 24, 8 bit, little-endian, data-type-policy=OVERRIDE, base-type=uint8, compu {phys=raw}, range phys 0..255
          signal ControlBindingFBD_Data01: start 32, 8 bit, little-endian, data-type-policy=OVERRIDE, base-type=uint8, compu {phys=raw}, range phys 0..255
          signal ControlBindingFBD_Data02: start 40, 8 bit, little-endian, data-type-policy=OVERRIDE, base-type=uint8, compu {phys=raw}, range phys 0..255
          signal ControlBindingFBD_Data03: start 48, 8 bit, little-endian, data-type-policy=OVERRIDE, base-type=uint8, compu {phys=raw}, range phys 0..255
          signal ControlBindingFBD_Data04: start 56, 8 bit, little-endian, data-type-policy=OVERRIDE, base-type=uint8, compu {phys=raw}, range phys 0..255
          signal ControlBindingFBD_Data05: start 64, 8 bit, little-endian, data-type-policy=OVERRIDE, base-type=uint8, compu {phys=raw}, range phys 0..255
          signal ControlBindingFBD_Data06: start 72, 8 bit, little-endian, data-type-policy=OVERRIDE, base-type=uint8, compu {phys=raw}, range phys 0..255
          signal ControlBindingFBD_Data07: start 80, 8 bit, little-endian, data-type-policy=OVERRIDE, base-type=uint8, compu {phys=raw}, range phys 0..255
          signal ControlBindingFBD_Data08: start 88, 8 bit, little-endian, data-type-policy=OVERRIDE, base-type=uint8, compu {phys=raw}, range phys 0..255
          signal ControlBindingFBD_Data09: start 96, 8 bit, little-endian, data-type-policy=OVERRIDE, base-type=uint8, compu {phys=raw}, range phys 0..255
          signal ControlBindingFBD_Data10: start 104, 8 bit, little-endian, data-type-policy=OVERRIDE, base-type=uint8, compu {phys=raw}, range phys 0..255
          signal ControlBindingFBD_Data11: start 112, 8 bit, little-endian, data-type-policy=OVERRIDE, base-type=uint8, compu {phys=raw}, range phys 0..255
          signal ControlBindingFBD_Data12: start 120, 8 bit, little-endian, data-type-policy=OVERRIDE, base-type=uint8, compu {phys=raw}, range phys 0..255
          signal ControlBindingFBD_Data13: start 128, 8 bit, little-endian, data-type-policy=OVERRIDE, base-type=uint8, compu {phys=raw}, range phys 0..255
          signal ControlBindingFBD_Data14: start 136, 8 bit, little-endian, data-type-policy=OVERRIDE, base-type=uint8, compu {phys=raw}, range phys 0..255
          signal ControlBindingFBD_Data15: start 144, 8 bit, little-endian, data-type-policy=OVERRIDE, base-type=uint8, compu {phys=raw}, range phys 0..255
          signal ControlBindingFBD_Data16: start 152, 8 bit, little-endian, data-type-policy=OVERRIDE, base-type=uint8, compu {phys=raw}, range phys 0..255
          signal ControlBindingFBD_Data17: start 160, 8 bit, little-endian, data-type-policy=OVERRIDE, base-type=uint8, compu {phys=raw}, range phys 0..255
          signal ControlBindingFBD_Data18: start 168, 8 bit, little-endian, data-type-policy=OVERRIDE, base-type=uint8, compu {phys=raw}, range phys 0..255
          signal ControlBindingFBD_Data19: start 176, 8 bit, little-endian, data-type-policy=OVERRIDE, base-type=uint8, compu {phys=raw}, range phys 0..255
          signal ControlBindingFBD_Data20: start 184, 8 bit, little-endian, data-type-policy=OVERRIDE, base-type=uint8, compu {phys=raw}, range phys 0..255
          signal ControlBindingFBD_Data21: start 192, 8 bit, little-endian, data-type-policy=OVERRIDE, base-type=uint8, compu {phys=raw}, range phys 0..255
          signal ControlBindingFBD_Data22: start 200, 8 bit, little-endian, data-type-policy=OVERRIDE, base-type=uint8, compu {phys=raw}, range phys 0..255
          signal ControlBindingFBD_Data23: start 208, 8 bit, little-endian, data-type-policy=OVERRIDE, base-type=uint8, compu {phys=raw}, range phys 0..255
          signal ControlBindingFBD_Data24: start 216, 8 bit, little-endian, data-type-policy=OVERRIDE, base-type=uint8, compu {phys=raw}, range phys 0..255
          signal ControlBindingFBD_Data25: start 224, 8 bit, little-endian, data-type-policy=OVERRIDE, base-type=uint8, compu {phys=raw}, range phys 0..255
          signal ControlBindingFBD_Data26: start 232, 8 bit, little-endian, data-type-policy=OVERRIDE, base-type=uint8, compu {phys=raw}, range phys 0..255
          signal ControlBindingFBD_Data27: start 240, 8 bit, little-endian, data-type-policy=OVERRIDE, base-type=uint8, compu {phys=raw}, range phys 0..255
          signal ControlBindingFBD_Data28: start 248, 8 bit, little-endian, data-type-policy=OVERRIDE, base-type=uint8, compu {phys=raw}, range phys 0..255
          signal ControlBindingFBD_Data29: start 256, 8 bit, little-endian, data-type-policy=OVERRIDE, base-type=uint8, compu {phys=raw}, range phys 0..255
          signal ControlBindingFBD_Data30: start 264, 8 bit, little-endian, data-type-policy=OVERRIDE, base-type=uint8, compu {phys=raw}, range phys 0..255
          signal ControlBindingFBD_Data31: start 272, 8 bit, little-endian, data-type-policy=OVERRIDE, base-type=uint8, compu {phys=raw}, range phys 0..255
          signal ControlBindingFBD_Data32: start 280, 8 bit, little-endian, data-type-policy=OVERRIDE, base-type=uint8, compu {phys=raw}, range phys 0..255
          signal ControlBindingFBD_Data33: start 288, 8 bit, little-endian, data-type-policy=OVERRIDE, base-type=uint8, compu {phys=raw}, range phys 0..255
          signal ControlBindingFBD_Data34: start 296, 8 bit, little-endian, data-type-policy=OVERRIDE, base-type=uint8, compu {phys=raw}, range phys 0..255
          signal ControlBindingFBD_Data35: start 304, 8 bit, little-endian, data-type-policy=OVERRIDE, base-type=uint8, compu {phys=raw}, range phys 0..255
          signal ControlBindingFBD_Data36: start 312, 8 bit, little-endian, data-type-policy=OVERRIDE, base-type=uint8, compu {phys=raw}, range phys 0..255
          signal ControlBindingFBD_Data37: start 320, 8 bit, little-endian, data-type-policy=OVERRIDE, base-type=uint8, compu {phys=raw}, range phys 0..255
          signal ControlBindingFBD_Data38: start 328, 8 bit, little-endian, data-type-policy=OVERRIDE, base-type=uint8, compu {phys=raw}, range phys 0..255
          signal ControlBindingFBD_Data39: start 336, 8 bit, little-endian, data-type-policy=OVERRIDE, base-type=uint8, compu {phys=raw}, range phys 0..255
          signal ControlBindingFBD_Data40: start 344, 8 bit, little-endian, data-type-policy=OVERRIDE, base-type=uint8, compu {phys=raw}, range phys 0..255
          signal ControlBindingFBD_Data41: start 352, 8 bit, little-endian, data-type-policy=OVERRIDE, base-type=uint8, compu {phys=raw}, range phys 0..255
          signal ControlBindingFBD_Data42: start 360, 8 bit, little-endian, data-type-policy=OVERRIDE, base-type=uint8, compu {phys=raw}, range phys 0..255
          signal ControlBindingFBD_Data43: start 368, 8 bit, little-endian, data-type-policy=OVERRIDE, base-type=uint8, compu {phys=raw}, range phys 0..255
          signal ControlBindingFBD_Data44: start 376, 8 bit, little-endian, data-type-policy=OVERRIDE, base-type=uint8, compu {phys=raw}, range phys 0..255
          signal ControlBindingFBD_Data45: start 384, 8 bit, little-endian, data-type-policy=OVERRIDE, base-type=uint8, compu {phys=raw}, range phys 0..255
          signal ControlBindingFBD_Data46: start 392, 8 bit, little-endian, data-type-policy=OVERRIDE, base-type=uint8, compu {phys=raw}, range phys 0..255
          signal ControlBindingFBD_Data47: start 400, 8 bit, little-endian, data-type-policy=OVERRIDE, base-type=uint8, compu {phys=raw}, range phys 0..255
          signal ControlBindingFBD_Data48: start 408, 8 bit, little-endian, data-type-policy=OVERRIDE, base-type=uint8, compu {phys=raw}, range phys 0..255
          signal ControlBindingFBD_Data49: start 416, 8 bit, little-endian, data-type-policy=OVERRIDE, base-type=uint8, compu {phys=raw}, range phys 0..255
          signal ControlBindingFBD_Data50: start 424, 8 bit, little-endian, data-type-policy=OVERRIDE, base-type=uint8, compu {phys=raw}, range phys 0..255
          signal ControlBindingFBD_Data51: start 432, 8 bit, little-endian, data-type-policy=OVERRIDE, base-type=uint8, compu {phys=raw}, range phys 0..255
          signal ControlBindingFBD_Data52: start 440, 8 bit, little-endian, data-type-policy=OVERRIDE, base-type=uint8, compu {phys=raw}, range phys 0..255
          signal ControlBindingFBD_Data53: start 448, 8 bit, little-endian, data-type-policy=OVERRIDE, base-type=uint8, compu {phys=raw}, range phys 0..255
          signal ControlBindingFBD_Data54: start 456, 8 bit, little-endian, data-type-policy=OVERRIDE, base-type=uint8, compu {phys=raw}, range phys 0..255
          signal ControlBindingFBD_Data55: start 464, 8 bit, little-endian, data-type-policy=OVERRIDE, base-type=uint8, compu {phys=raw}, range phys 0..255
          signal ControlBindingFBD_Data56: start 472, 8 bit, little-endian, data-type-policy=OVERRIDE, base-type=uint8, compu {phys=raw}, range phys 0..255
          signal ControlBindingFBD_Data57: start 480, 8 bit, little-endian, data-type-policy=OVERRIDE, base-type=uint8, compu {phys=raw}, range phys 0..255
          signal ControlBindingFBD_Data58: start 488, 8 bit, little-endian, data-type-policy=OVERRIDE, base-type=uint8, compu {phys=raw}, range phys 0..255
          signal ControlBindingFBD_Data59: start 496, 8 bit, little-endian, data-type-policy=OVERRIDE, base-type=uint8, compu {phys=raw}, range phys 0..255
          signal ControlBindingFBD_Data60: start 504, 8 bit, little-endian, data-type-policy=OVERRIDE, base-type=uint8, compu {phys=raw}, range phys 0..255
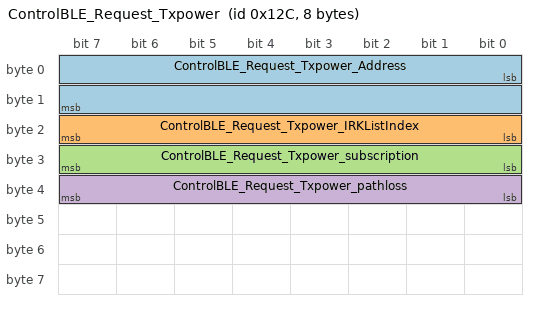
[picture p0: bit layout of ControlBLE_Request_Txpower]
      frame ControlBLE_Request_Txpower: id 0x12C, frame-length=8, can-addressing-mode=STANDARD, can-frame-rx-behavior=CAN-20, can-frame-tx-behavior=CAN-20
        pdu ControlBLE_Request_Txpower: length=8, unused-bit-pattern=0
          signal ControlBLE_Request_Txpower_Address: start 0, 16 bit, little-endian, data-type-policy=OVERRIDE, compu {phys=raw}
          signal ControlBLE_Request_Txpower_IRKListIndex: start 16, 8 bit, little-endian, data-type-policy=OVERRIDE, base-type=uint8, compu {phys=raw}, range phys 0..252
          signal ControlBLE_Request_Txpower_subscription: start 24, 8 bit, little-endian, data-type-policy=OVERRIDE, compu {phys=raw}
          signal ControlBLE_Request_Txpower_pathloss: start 32, 8 bit, little-endian, data-type-policy=OVERRIDE, compu {phys=raw}
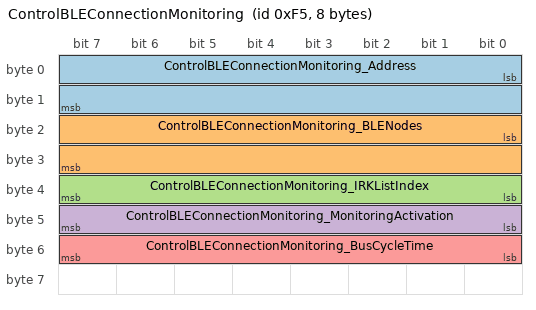
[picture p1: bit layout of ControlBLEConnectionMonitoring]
      frame ControlBLEConnectionMonitoring: id 0xF5, frame-length=8, can-addressing-mode=STANDARD, can-frame-rx-behavior=CAN-20, can-frame-tx-behavior=CAN-20
        pdu ControlBLEConnectionMonitoring: length=8, unused-bit-pattern=0
          signal ControlBLEConnectionMonitoring_Address: start 0, 16 bit, little-endian, data-type-policy=OVERRIDE, compu {phys=raw}
          signal ControlBLEConnectionMonitoring_BLENodes: start 16, 16 bit, little-endian, data-type-policy=OVERRIDE, compu {phys=raw}
          signal ControlBLEConnectionMonitoring_IRKListIndex: start 32, 8 bit, little-endian, data-type-policy=OVERRIDE, base-type=uint8, compu {phys=raw}, range phys 0..252
          signal ControlBLEConnectionMonitoring_MonitoringActivation: start 40, 8 bit, little-endian, data-type-policy=OVERRIDE, compu {phys=raw}
          signal ControlBLEConnectionMonitoring_BusCycleTime: start 48, 8 bit, little-endian, data-type-policy=OVERRIDE, base-type=uint8, compu {phys=raw*10; unit ms}, range phys 0..252
      frame ControlBLECS: id 0x17F, frame-length=16, can-addressing-mode=STANDARD, can-frame-rx-behavior=CAN-FD, can-frame-tx-behavior=CAN-FD
        pdu ControlBLECS: length=16, unused-bit-pattern=0
          signal ControlBLECS_Address: start 0, 16 bit, little-endian, data-type-policy=OVERRIDE, compu {phys=raw}
          signal ControlBLECS_SessionID: start 16, 8 bit, little-endian, data-type-policy=OVERRIDE, base-type=uint8, compu {phys=raw}, range phys 0..252
          signal ControlBLECS_IRKListID: start 24, 8 bit, little-endian, data-type-policy=OVERRIDE, base-type=uint8, compu {phys=raw}, range phys 0..252
          signal ControlBLECS_DeviceGroup: start 32, 8 bit, little-endian, data-type-policy=OVERRIDE, base-type=uint8, compu {phys=raw}, range phys 0..252
          signal ControlBLECS_Algorithm: start 40, 8 bit, little-endian, data-type-policy=OVERRIDE, compu {phys=raw}
          signal ControlBLECS_DistanceOffset: start 48, 16 bit, little-endian, data-type-policy=OVERRIDE, base-type=uint16, compu {phys=raw}, range phys 0..65532
          signal ControlBLECS_AntennaConfig: start 64, 8 bit, little-endian, data-type-policy=OVERRIDE, compu {phys=raw}
          signal ControlBLECS_TxPower: start 72, 8 bit, little-endian, data-type-policy=OVERRIDE, base-type=uint8, compu {phys=raw}, range phys 0..252
          signal ControlBLECS_Role: start 80, 8 bit, little-endian, data-type-policy=OVERRIDE, compu {phys=raw}
          signal ControlBLECS_ProcedureResultsTransfer: start 88, 8 bit, little-endian, data-type-policy=OVERRIDE, compu {phys=raw}
          signal ControlBLECS_AntennaPathProcedureResults: start 96, 8 bit, little-endian, data-type-policy=OVERRIDE, compu {phys=raw}
          signal ControlBLECS_FBDonlyThreshold: start 104, 8 bit, little-endian, data-type-policy=OVERRIDE, base-type=uint8, compu {phys=raw}, range phys 0..252
          signal ControlBLECS_InlinePCT: start 112, 8 bit, little-endian, data-type-policy=OVERRIDE, compu {phys=raw}
      frame ControlBLEDeviceName: id 0x260, frame-length=32, can-addressing-mode=STANDARD, can-frame-rx-behavior=CAN-FD, can-frame-tx-behavior=CAN-FD
        pdu ControlBLEDeviceName: length=32, unused-bit-pattern=0
          signal ControlBLEDeviceName_Address: start 0, 16 bit, little-endian, data-type-policy=OVERRIDE, compu {phys=raw}
          signal ControlBLEDeviceName_Character00: start 16, 8 bit, little-endian, data-type-policy=OVERRIDE, base-type=uint8, compu {phys=raw}, range phys 0..252
          signal ControlBLEDeviceName_Character01: start 24, 8 bit, little-endian, data-type-policy=OVERRIDE, base-type=uint8, compu {phys=raw}, range phys 0..252
          signal ControlBLEDeviceName_Character02: start 32, 8 bit, little-endian, data-type-policy=OVERRIDE, base-type=uint8, compu {phys=raw}, range phys 0..252
          signal ControlBLEDeviceName_Character03: start 40, 8 bit, little-endian, data-type-policy=OVERRIDE, base-type=uint8, compu {phys=raw}, range phys 0..252
          signal ControlBLEDeviceName_Character04: start 48, 8 bit, little-endian, data-type-policy=OVERRIDE, base-type=uint8, compu {phys=raw}, range phys 0..252
          signal ControlBLEDeviceName_Character05: start 56, 8 bit, little-endian, data-type-policy=OVERRIDE, base-type=uint8, compu {phys=raw}, range phys 0..252
          signal ControlBLEDeviceName_Character06: start 64, 8 bit, little-endian, data-type-policy=OVERRIDE, base-type=uint8, compu {phys=raw}, range phys 0..252
          signal ControlBLEDeviceName_Character07: start 72, 8 bit, little-endian, data-type-policy=OVERRIDE, base-type=uint8, compu {phys=raw}, range phys 0..252
          signal ControlBLEDeviceName_Character08: start 80, 8 bit, little-endian, data-type-policy=OVERRIDE, base-type=uint8, compu {phys=raw}, range phys 0..252
          signal ControlBLEDeviceName_Character09: start 88, 8 bit, little-endian, data-type-policy=OVERRIDE, base-type=uint8, compu {phys=raw}, range phys 0..252
          signal ControlBLEDeviceName_Character10: start 96, 8 bit, little-endian, data-type-policy=OVERRIDE, base-type=uint8, compu {phys=raw}, range phys 0..252
          signal ControlBLEDeviceName_Character11: start 104, 8 bit, little-endian, data-type-policy=OVERRIDE, base-type=uint8, compu {phys=raw}, range phys 0..252
          signal ControlBLEDeviceName_Character12: start 112, 8 bit, little-endian, data-type-policy=OVERRIDE, base-type=uint8, compu {phys=raw}, range phys 0..252
          signal ControlBLEDeviceName_Character13: start 120, 8 bit, little-endian, data-type-policy=OVERRIDE, base-type=uint8, compu {phys=raw}, range phys 0..252
          signal ControlBLEDeviceName_Character14: start 128, 8 bit, little-endian, data-type-policy=OVERRIDE, base-type=uint8, compu {phys=raw}, range phys 0..252
          signal ControlBLEDeviceName_Character15: start 136, 8 bit, little-endian, data-type-policy=OVERRIDE, base-type=uint8, compu {phys=raw}, range phys 0..252
          signal ControlBLEDeviceName_Character16: start 144, 8 bit, little-endian, data-type-policy=OVERRIDE, base-type=uint8, compu {phys=raw}, range phys 0..252
          signal ControlBLEDeviceName_Character17: start 152, 8 bit, little-endian, data-type-policy=OVERRIDE, base-type=uint8, compu {phys=raw}, range phys 0..252
          signal ControlBLEDeviceName_Character18: start 160, 8 bit, little-endian, data-type-policy=OVERRIDE, base-type=uint8, compu {phys=raw}, range phys 0..252
          signal ControlBLEDeviceName_Character19: start 168, 8 bit, little-endian, data-type-policy=OVERRIDE, base-type=uint8, compu {phys=raw}, range phys 0..252
          signal ControlBLEDeviceName_Character20: start 176, 8 bit, little-endian, data-type-policy=OVERRIDE, base-type=uint8, compu {phys=raw}, range phys 0..252
          signal ControlBLEDeviceName_Character21: start 184, 8 bit, little-endian, data-type-policy=OVERRIDE, base-type=uint8, compu {phys=raw}, range phys 0..252
          signal ControlBLEDeviceName_Character22: start 192, 8 bit, little-endian, data-type-policy=OVERRIDE, base-type=uint8, compu {phys=raw}, range phys 0..252
          signal ControlBLEDeviceName_Character23: start 200, 8 bit, little-endian, data-type-policy=OVERRIDE, base-type=uint8, compu {phys=raw}, range phys 0..252
          signal ControlBLEDeviceName_Character24: start 208, 8 bit, little-endian, data-type-policy=OVERRIDE, base-type=uint8, compu {phys=raw}, range phys 0..252
          signal ControlBLEDeviceName_Character25: start 216, 8 bit, little-endian, data-type-policy=OVERRIDE, base-type=uint8, compu {phys=raw}, range phys 0..252
          signal ControlBLEDeviceName_Character26: start 224, 8 bit, little-endian, data-type-policy=OVERRIDE, base-type=uint8, compu {phys=raw}, range phys 0..252
          signal ControlBLEDeviceName_Character27: start 232, 8 bit, little-endian, data-type-policy=OVERRIDE, base-type=uint8, compu {phys=raw}, range phys 0..252
          signal ControlBLEDeviceName_Character28: start 240, 8 bit, little-endian, data-type-policy=OVERRIDE, base-type=uint8, compu {phys=raw}, range phys 0..252
          signal ControlBLEDeviceName_Character29: start 248, 8 bit, little-endian, data-type-policy=OVERRIDE, base-type=uint8, compu {phys=raw}, range phys 0..252
      frame ControlBLEInitialSettings: id 0xC8, frame-length=20, can-addressing-mode=STANDARD, can-frame-rx-behavior=CAN-FD, can-frame-tx-behavior=CAN-FD
        pdu ControlBLEInitialSettings: length=20, unused-bit-pattern=0
          signal ControlBLEInitialSettings_Address: start 0, 16 bit, little-endian, data-type-policy=OVERRIDE, compu {phys=raw}
          signal ControlBLEInitialSettings_BLEOperationMode: start 16, 8 bit, little-endian, data-type-policy=OVERRIDE, compu {phys=raw}
          signal ControlBLEInitialSettings_AdvertisingInterval: start 24, 16 bit, little-endian, data-type-policy=OVERRIDE, base-type=uint16, compu {phys=raw*0.625; unit ms}, range phys 0..40957
          signal ControlBLEInitialSettings_ScanWindowScanInterval: start 40, 16 bit, little-endian, data-type-policy=OVERRIDE, base-type=uint16, compu {phys=raw*0.625; unit ms}, range phys 0..40957
          signal ControlBLEInitialSettings_enableBLELELRMode: start 56, 8 bit, little-endian, data-type-policy=OVERRIDE, compu {phys=raw}
          signal ControlBLEInitialSettings_SetBLELELRMode: start 64, 8 bit, little-endian, data-type-policy=OVERRIDE, compu {phys=raw}
          signal ControlBLEInitialSettings_LR500_AdvertisingInterval: start 72, 16 bit, little-endian, data-type-policy=OVERRIDE, base-type=uint16, compu {phys=raw*0.625; unit ms}, range phys 0..40957
          signal ControlBLEInitialSettings_LR125_AdvertisingInterval: start 88, 16 bit, little-endian, data-type-policy=OVERRIDE, base-type=uint16, compu {phys=raw*0.625; unit ms}, range phys 0..40957
          signal ControlBLEInitialSettings_EnableExtendedAdvertising: start 104, 8 bit, little-endian, data-type-policy=OVERRIDE, compu {phys=raw}
          signal ControlBLEInitialSettings_SetTxPower: start 112, 8 bit, little-endian, data-type-policy=OVERRIDE, base-type=uint8, compu {phys=raw}, range phys 0..252
          signal ControlBLEInitialSettings_SetPSM: start 120, 8 bit, little-endian, data-type-policy=OVERRIDE, base-type=uint8, compu {phys=raw}, range phys 0..252
          signal ControlBLEInitialSettings_SetRPAFrequency: start 128, 8 bit, little-endian, data-type-policy=OVERRIDE, base-type=uint8, compu {phys=raw}, range phys 0..252
          signal ControlBLEInitialSettings_SetDCKVersion: start 136, 8 bit, little-endian, data-type-policy=OVERRIDE, base-type=uint8, compu {phys=raw}, range phys 0..252
          signal ControlBLEInitialSettings_SetScanRequest: start 144, 8 bit, little-endian, data-type-policy=OVERRIDE, compu {phys=raw}
      frame ControlBLERSSIRangingIntent: id 0xD1, frame-length=16, can-addressing-mode=STANDARD, can-frame-rx-behavior=CAN-FD, can-frame-tx-behavior=CAN-FD
        pdu ControlBLERSSIRangingIntent: length=16, unused-bit-pattern=0
          signal ControlBLERSSIRangingIntent_Address: start 0, 16 bit, little-endian, data-type-policy=OVERRIDE, compu {phys=raw}
          signal ControlBLERSSIRangingIntent_Activate: start 16, 8 bit, little-endian, data-type-policy=OVERRIDE, base-type=uint8, compu {phys=raw}, range phys 0..252
          signal ControlBLERSSIRangingIntent_MovingWindowDuration: start 24, 16 bit, little-endian, data-type-policy=OVERRIDE, base-type=uint16, compu {phys=raw; unit ms}, range phys 0..65532
          signal ControlBLERSSIRangingIntent_FBD_Only_BLI: start 40, 8 bit, little-endian, data-type-policy=OVERRIDE, base-type=uint8, compu {phys=raw}, range phys 0..252
          signal ControlBLERSSIRangingIntent_MultiRSSIIntent: start 48, 8 bit, little-endian, data-type-policy=OVERRIDE, base-type=uint8, compu {phys=raw}, range phys 0..252
          signal ControlBLERSSIRangingIntent_IRKListID: start 56, 8 bit, little-endian, data-type-policy=OVERRIDE, base-type=uint8, compu {phys=raw}, range phys 0..252
          signal ControlBLERSSIRangingIntent_BLENodes: start 64, 16 bit, little-endian, data-type-policy=OVERRIDE, compu {phys=raw}
          signal ControlBLERSSIRangingIntent_MinNumberOfAnchors: start 80, 8 bit, little-endian, data-type-policy=OVERRIDE, base-type=uint8, compu {phys=raw}, range phys 0..252
          signal ControlBLERSSIRangingIntent_DeviceGroup: start 88, 8 bit, little-endian, data-type-policy=OVERRIDE, base-type=uint8, compu {phys=raw}, range phys 0..252
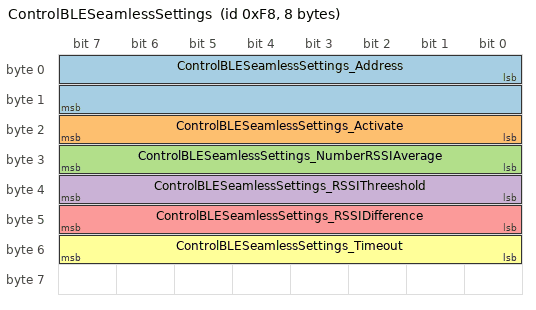
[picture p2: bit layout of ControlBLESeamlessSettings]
      frame ControlBLESeamlessSettings: id 0xF8, frame-length=8, can-addressing-mode=STANDARD, can-frame-rx-behavior=CAN-20, can-frame-tx-behavior=CAN-20
        pdu ControlBLESeamlessSettings: length=8, unused-bit-pattern=0
          signal ControlBLESeamlessSettings_Address: start 0, 16 bit, little-endian, data-type-policy=OVERRIDE, compu {phys=raw}
          signal ControlBLESeamlessSettings_Activate: start 16, 8 bit, little-endian, data-type-policy=OVERRIDE, base-type=uint8, compu {phys=raw}, range phys 0..252
          signal ControlBLESeamlessSettings_NumberRSSIAverage: start 24, 8 bit, little-endian, data-type-policy=OVERRIDE, base-type=uint8, compu {phys=raw}, range phys 0..252
          signal ControlBLESeamlessSettings_RSSIThreeshold: start 32, 8 bit, little-endian, data-type-policy=OVERRIDE, base-type=uint8, compu {phys=raw*0.5-127; unit dB}, range phys -127..-1
          signal ControlBLESeamlessSettings_RSSIDifference: start 40, 8 bit, little-endian, data-type-policy=OVERRIDE, base-type=uint8, compu {phys=raw*0.5; unit dB}, range phys 0..126
          signal ControlBLESeamlessSettings_Timeout: start 48, 8 bit, little-endian, data-type-policy=OVERRIDE, base-type=uint8, compu {phys=raw; unit ms}, range phys 0..252
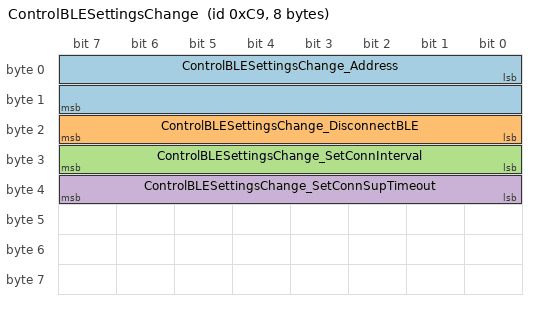
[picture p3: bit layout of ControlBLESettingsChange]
      frame ControlBLESettingsChange: id 0xC9, frame-length=8, can-addressing-mode=STANDARD, can-frame-rx-behavior=CAN-20, can-frame-tx-behavior=CAN-20
        pdu ControlBLESettingsChange: length=8, unused-bit-pattern=0
          signal ControlBLESettingsChange_Address: start 0, 16 bit, little-endian, data-type-policy=OVERRIDE, compu {phys=raw}
          signal ControlBLESettingsChange_DisconnectBLE: start 16, 8 bit, little-endian, data-type-policy=OVERRIDE, base-type=uint8, compu {phys=raw}, range phys 0..252
          signal ControlBLESettingsChange_SetConnInterval: start 24, 8 bit, little-endian, data-type-policy=OVERRIDE, base-type=uint8, compu {phys=raw}, range phys 0..252
          signal ControlBLESettingsChange_SetConnSupTimeout: start 32, 8 bit, little-endian, data-type-policy=OVERRIDE, base-type=uint8, compu {phys=raw}, range phys 0..252
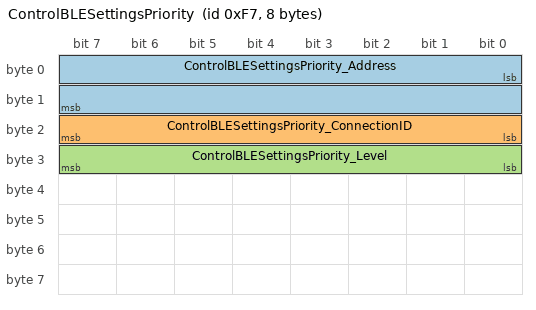
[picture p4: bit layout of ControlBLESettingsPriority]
      frame ControlBLESettingsPriority: id 0xF7, frame-length=8, can-addressing-mode=STANDARD, can-frame-rx-behavior=CAN-20, can-frame-tx-behavior=CAN-20
        pdu ControlBLESettingsPriority: length=8, unused-bit-pattern=0
          signal ControlBLESettingsPriority_Address: start 0, 16 bit, little-endian, data-type-policy=OVERRIDE, compu {phys=raw}
          signal ControlBLESettingsPriority_ConnectionID: start 16, 8 bit, little-endian, data-type-policy=OVERRIDE, base-type=uint8, compu {phys=raw}, range phys 0..252
          signal ControlBLESettingsPriority_Level: start 24, 8 bit, little-endian, data-type-policy=OVERRIDE, compu {phys=raw}
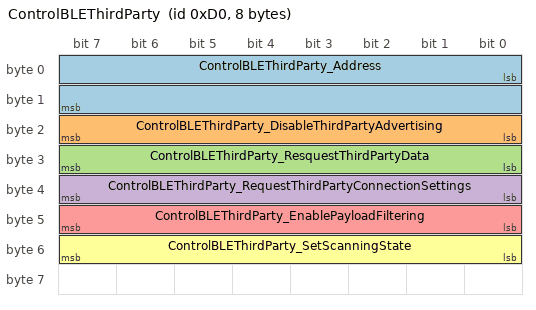
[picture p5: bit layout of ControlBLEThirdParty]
      frame ControlBLEThirdParty: id 0xD0, frame-length=8, can-addressing-mode=STANDARD, can-frame-rx-behavior=CAN-20, can-frame-tx-behavior=CAN-20
        pdu ControlBLEThirdParty: length=8, unused-bit-pattern=0
          signal ControlBLEThirdParty_Address: start 0, 16 bit, little-endian, data-type-policy=OVERRIDE, compu {phys=raw}
          signal ControlBLEThirdParty_DisableThirdPartyAdvertising: start 16, 8 bit, little-endian, data-type-policy=OVERRIDE, compu {phys=raw}
          signal ControlBLEThirdParty_ResquestThirdPartyData: start 24, 8 bit, little-endian, data-type-policy=OVERRIDE, compu {phys=raw}
          signal ControlBLEThirdParty_RequestThirdPartyConnectionSettings: start 32, 8 bit, little-endian, data-type-policy=OVERRIDE, base-type=uint8, compu {phys=raw}, range phys 0..252
          signal ControlBLEThirdParty_EnablePayloadFiltering: start 40, 8 bit, little-endian, data-type-policy=OVERRIDE, compu {phys=raw}
          signal ControlBLEThirdParty_SetScanningState: start 48, 8 bit, little-endian, data-type-policy=OVERRIDE, compu {phys=raw}
      frame ControlConfigurationFBD: id 0x258, frame-length=20, can-addressing-mode=STANDARD, can-frame-rx-behavior=CAN-FD, can-frame-tx-behavior=CAN-FD
        pdu ControlConfigurationFBD: length=20, unused-bit-pattern=0
          signal ControlConfigurationFBD_Address: start 0, 16 bit, little-endian, data-type-policy=OVERRIDE, compu {phys=raw}
          signal ControlConfigurationFBD_DeviceGroup: start 16, 8 bit, little-endian, data-type-policy=OVERRIDE, base-type=uint8, compu {phys=raw}, range phys 0..252
          signal ControlConfigurationFBD_IRKListID: start 24, 8 bit, little-endian, data-type-policy=OVERRIDE, base-type=uint8, compu {phys=raw}, range phys 0..252
          signal ControlConfigurationFBD_RSSIRangingIntent_FBD_Only_RIP: start 32, 8 bit, little-endian, data-type-policy=OVERRIDE, base-type=uint8, compu {phys=raw}, range phys 0..252
          signal ControlConfigurationFBD_RSSIRangingIntent_FBD_Only_RIM: start 40, 8 bit, little-endian, data-type-policy=OVERRIDE, base-type=uint8, compu {phys=raw}, range phys 0..252
          signal ControlConfigurationFBD_FBD_Only_BLU: start 48, 8 bit, little-endian, data-type-policy=OVERRIDE, base-type=uint8, compu {phys=raw}, range phys 0..252
          signal ControlConfigurationFBD_UWBDutyCycleLimitSec: start 56, 8 bit, little-endian, data-type-policy=OVERRIDE, base-type=uint8, compu {phys=raw*0.5; unit ms}, range phys 0..126
          signal ControlConfigurationFBD_UWBDutyCycleLimitHour: start 64, 8 bit, little-endian, data-type-policy=OVERRIDE, base-type=uint8, compu {phys=raw*0.1; unit s}, range phys 0..25.2
          signal ControlConfigurationFBD_UWBDutyCycleLimitOffMeanSec: start 72, 8 bit, little-endian, data-type-policy=OVERRIDE, base-type=uint8, compu {phys=raw*0.5; unit ms}, range phys 0..126
          signal ControlConfigurationFBD_FBDonlyWUT: start 80, 8 bit, little-endian, data-type-policy=OVERRIDE, base-type=uint8, compu {phys=raw*0.1; unit m}, range phys 0..25.2
          signal ControlConfigurationFBD_FBDonlyRIT: start 88, 8 bit, little-endian, data-type-policy=OVERRIDE, compu {phys=raw}
          signal ControlConfigurationFBD_FBDonlyRSU: start 96, 8 bit, little-endian, data-type-policy=OVERRIDE, base-type=uint8, compu {phys=raw; unit s}, range phys 0..252
          signal ControlConfigurationFBD_FBDonlyRSE: start 104, 8 bit, little-endian, data-type-policy=OVERRIDE, base-type=uint8, compu {phys=raw}, range phys 0..252
          signal ControlConfigurationFBD_FBDonlyRSI: start 112, 8 bit, little-endian, data-type-policy=OVERRIDE, base-type=uint8, compu {phys=raw; unit s}, range phys 0..252
          signal ControlConfigurationFBD_FBDonlyRSM: start 120, 8 bit, little-endian, data-type-policy=OVERRIDE, base-type=uint8, compu {phys=raw; unit s}, range phys 0..252
          signal ControlConfigurationFBD_FBDonlyRTM: start 128, 8 bit, little-endian, data-type-policy=OVERRIDE, base-type=uint8, compu {phys=raw; unit min}, range phys 0..252
          signal ControlConfigurationFBD_FBDonlyRAN: start 136, 8 bit, little-endian, data-type-policy=OVERRIDE, base-type=uint8, compu {phys=raw}, range phys 0..252
          signal ControlConfigurationFBD_FBDonlyDataCollectionState: start 144, 8 bit, little-endian, data-type-policy=OVERRIDE, compu {phys=raw}
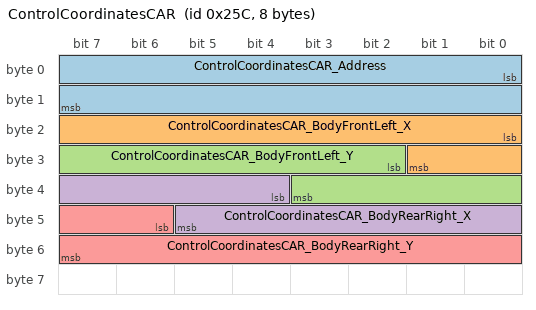
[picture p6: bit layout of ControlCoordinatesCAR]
      frame ControlCoordinatesCAR: id 0x25C, frame-length=8, can-addressing-mode=STANDARD, can-frame-rx-behavior=CAN-20, can-frame-tx-behavior=CAN-20
        pdu ControlCoordinatesCAR: length=8, unused-bit-pattern=0
          signal ControlCoordinatesCAR_Address: start 0, 16 bit, little-endian, data-type-policy=OVERRIDE, compu {phys=raw}
          signal ControlCoordinatesCAR_BodyFrontLeft_X: start 16, 10 bit, little-endian, data-type-policy=OVERRIDE, base-type=uint16, compu {phys=raw-250; unit cm}, range phys -250..770
          signal ControlCoordinatesCAR_BodyFrontLeft_Y: start 26, 10 bit, little-endian, data-type-policy=OVERRIDE, base-type=uint16, compu {phys=raw-250; unit cm}, range phys -250..770
          signal ControlCoordinatesCAR_BodyRearRight_X: start 36, 10 bit, little-endian, data-type-policy=OVERRIDE, base-type=uint16, compu {phys=raw-250; unit cm}, range phys -250..770
          signal ControlCoordinatesCAR_BodyRearRight_Y: start 46, 10 bit, little-endian, data-type-policy=OVERRIDE, base-type=uint16, compu {phys=raw-250; unit cm}, range phys -250..770
      frame ControlCoordinatesFBD: id 0x25B, frame-length=64, can-addressing-mode=STANDARD, can-frame-rx-behavior=CAN-FD, can-frame-tx-behavior=CAN-FD
        pdu ControlCoordinatesFBD: length=64, unused-bit-pattern=0
          signal ControlCoordinatesFBD_Address: start 0, 16 bit, little-endian, data-type-policy=OVERRIDE, compu {phys=raw}
          signal ControlCoordinatesFBD_VM_X: start 16, 10 bit, little-endian, data-type-policy=OVERRIDE, base-type=uint16, compu {phys=raw-250; unit cm}, range phys -250..770
          signal ControlCoordinatesFBD_VM_Y: start 26, 10 bit, little-endian, data-type-policy=OVERRIDE, base-type=uint16, compu {phys=raw-250; unit cm}, range phys -250..770
          signal ControlCoordinatesFBD_VM_Z: start 36, 10 bit, little-endian, data-type-policy=OVERRIDE, base-type=uint16, compu {phys=raw-250; unit cm}, range phys -250..770
          signal ControlCoordinatesFBD_VM_azimuth: start 46, 9 bit, little-endian, data-type-policy=OVERRIDE, base-type=uint16, compu {phys=raw-180; unit °}, range phys -180..180
          signal ControlCoordinatesFBD_VM_elevation: start 55, 8 bit, little-endian, data-type-policy=OVERRIDE, base-type=uint8, compu {phys=raw-100; unit °}, range phys -100..100
          signal ControlCoordinatesFBD_HM_X: start 63, 10 bit, little-endian, data-type-policy=OVERRIDE, base-type=uint16, compu {phys=raw-250; unit cm}, range phys -250..770
          signal ControlCoordinatesFBD_HM_Y: start 73, 10 bit, little-endian, data-type-policy=OVERRIDE, base-type=uint16, compu {phys=raw-250; unit cm}, range phys -250..770
          signal ControlCoordinatesFBD_HM_Z: start 83, 10 bit, little-endian, data-type-policy=OVERRIDE, base-type=uint16, compu {phys=raw-250; unit cm}, range phys -250..770
          signal ControlCoordinatesFBD_HM_azimuth: start 93, 9 bit, little-endian, data-type-policy=OVERRIDE, base-type=uint16, compu {phys=raw-180; unit °}, range phys -180..180
          signal ControlCoordinatesFBD_HM_elevation: start 102, 8 bit, little-endian, data-type-policy=OVERRIDE, base-type=uint8, compu {phys=raw-100; unit °}, range phys -100..100
          signal ControlCoordinatesFBD_Miko_X: start 110, 10 bit, little-endian, data-type-policy=OVERRIDE, base-type=uint16, compu {phys=raw-250; unit cm}, range phys -250..770
          signal ControlCoordinatesFBD_Miko_Y: start 120, 10 bit, little-endian, data-type-policy=OVERRIDE, base-type=uint16, compu {phys=raw-250; unit cm}, range phys -250..770
          signal ControlCoordinatesFBD_Miko_Z: start 130, 10 bit, little-endian, data-type-policy=OVERRIDE, base-type=uint16, compu {phys=raw-250; unit cm}, range phys -250..770
          signal ControlCoordinatesFBD_Miko_azimuth: start 140, 9 bit, little-endian, data-type-policy=OVERRIDE, base-type=uint16, compu {phys=raw-180; unit °}, range phys -180..180
          signal ControlCoordinatesFBD_Miko_elevation: start 149, 8 bit, little-endian, data-type-policy=OVERRIDE, base-type=uint8, compu {phys=raw-100; unit °}, range phys -100..100
          signal ControlCoordinatesFBD_Trunk_X: start 157, 10 bit, little-endian, data-type-policy=OVERRIDE, base-type=uint16, compu {phys=raw-250; unit cm}, range phys -250..770
          signal ControlCoordinatesFBD_Trunk_Y: start 167, 10 bit, little-endian, data-type-policy=OVERRIDE, base-type=uint16, compu {phys=raw-250; unit cm}, range phys -250..770
          signal ControlCoordinatesFBD_Trunk_Z: start 177, 10 bit, little-endian, data-type-policy=OVERRIDE, base-type=uint16, compu {phys=raw-250; unit cm}, range phys -250..770
          signal ControlCoordinatesFBD_Trunk_azimuth: start 187, 9 bit, little-endian, data-type-policy=OVERRIDE, base-type=uint16, compu {phys=raw-180; unit °}, range phys -180..180
          signal ControlCoordinatesFBD_Trunk_elevation: start 196, 8 bit, little-endian, data-type-policy=OVERRIDE, base-type=uint8, compu {phys=raw-100; unit °}, range phys -100..100
          signal ControlCoordinatesFBD_VL_X: start 204, 10 bit, little-endian, data-type-policy=OVERRIDE, base-type=uint16, compu {phys=raw-250; unit cm}, range phys -250..770
          signal ControlCoordinatesFBD_VL_Y: start 214, 10 bit, little-endian, data-type-policy=OVERRIDE, base-type=uint16, compu {phys=raw-250; unit cm}, range phys -250..770
          signal ControlCoordinatesFBD_VL_Z: start 224, 10 bit, little-endian, data-type-policy=OVERRIDE, base-type=uint16, compu {phys=raw-250; unit cm}, range phys -250..770
          signal ControlCoordinatesFBD_VL_azimuth: start 234, 9 bit, little-endian, data-type-policy=OVERRIDE, base-type=uint16, compu {phys=raw-180; unit °}, range phys -180..180
          signal ControlCoordinatesFBD_VL_elevation: start 243, 8 bit, little-endian, data-type-policy=OVERRIDE, base-type=uint8, compu {phys=raw-100; unit °}, range phys -100..100
          signal ControlCoordinatesFBD_VR_X: start 251, 10 bit, little-endian, data-type-policy=OVERRIDE, base-type=uint16, compu {phys=raw-250; unit cm}, range phys -250..770
          signal ControlCoordinatesFBD_VR_Y: start 261, 10 bit, little-endian, data-type-policy=OVERRIDE, base-type=uint16, compu {phys=raw-250; unit cm}, range phys -250..770
          signal ControlCoordinatesFBD_VR_Z: start 271, 10 bit, little-endian, data-type-policy=OVERRIDE, base-type=uint16, compu {phys=raw-250; unit cm}, range phys -250..770
          signal ControlCoordinatesFBD_VR_azimuth: start 281, 9 bit, little-endian, data-type-policy=OVERRIDE, base-type=uint16, compu {phys=raw-180; unit °}, range phys -180..180
          signal ControlCoordinatesFBD_VR_elevation: start 290, 8 bit, little-endian, data-type-policy=OVERRIDE, base-type=uint8, compu {phys=raw-100; unit °}, range phys -100..100
          signal ControlCoordinatesFBD_HL_X: start 298, 10 bit, little-endian, data-type-policy=OVERRIDE, base-type=uint16, compu {phys=raw-250; unit cm}, range phys -250..770
          signal ControlCoordinatesFBD_HL_Y: start 308, 10 bit, little-endian, data-type-policy=OVERRIDE, base-type=uint16, compu {phys=raw-250; unit cm}, range phys -250..770
          signal ControlCoordinatesFBD_HL_Z: start 318, 10 bit, little-endian, data-type-policy=OVERRIDE, base-type=uint16, compu {phys=raw-250; unit cm}, range phys -250..770
          signal ControlCoordinatesFBD_HL_azimuth: start 328, 9 bit, little-endian, data-type-policy=OVERRIDE, base-type=uint16, compu {phys=raw-180; unit °}, range phys -180..180
          signal ControlCoordinatesFBD_HL_elevation: start 337, 8 bit, little-endian, data-type-policy=OVERRIDE, base-type=uint8, compu {phys=raw-100; unit °}, range phys -100..100
          signal ControlCoordinatesFBD_HR_X: start 345, 10 bit, little-endian, data-type-policy=OVERRIDE, base-type=uint16, compu {phys=raw-250; unit cm}, range phys -250..770
          signal ControlCoordinatesFBD_HR_Y: start 355, 10 bit, little-endian, data-type-policy=OVERRIDE, base-type=uint16, compu {phys=raw-250; unit cm}, range phys -250..770
          signal ControlCoordinatesFBD_HR_Z: start 365, 10 bit, little-endian, data-type-policy=OVERRIDE, base-type=uint16, compu {phys=raw-250; unit cm}, range phys -250..770
          signal ControlCoordinatesFBD_HR_azimuth: start 375, 9 bit, little-endian, data-type-policy=OVERRIDE, base-type=uint16, compu {phys=raw-180; unit °}, range phys -180..180
          signal ControlCoordinatesFBD_HR_elevation: start 384, 8 bit, little-endian, data-type-policy=OVERRIDE, base-type=uint8, compu {phys=raw-100; unit °}, range phys -100..100
          signal ControlCoordinatesFBD_SML_X: start 392, 10 bit, little-endian, data-type-policy=OVERRIDE, base-type=uint16, compu {phys=raw-250; unit cm}, range phys -250..770
          signal ControlCoordinatesFBD_SML_Y: start 402, 10 bit, little-endian, data-type-policy=OVERRIDE, base-type=uint16, compu {phys=raw-250; unit cm}, range phys -250..770
          signal ControlCoordinatesFBD_SML_Z: start 412, 10 bit, little-endian, data-type-policy=OVERRIDE, base-type=uint16, compu {phys=raw-250; unit cm}, range phys -250..770
          signal ControlCoordinatesFBD_SML_azimuth: start 422, 9 bit, little-endian, data-type-policy=OVERRIDE, base-type=uint16, compu {phys=raw-180; unit °}, range phys -180..180
          signal ControlCoordinatesFBD_SML_elevation: start 431, 8 bit, little-endian, data-type-policy=OVERRIDE, base-type=uint8, compu {phys=raw-100; unit °}, range phys -100..100
          signal ControlCoordinatesFBD_SMR_X: start 439, 10 bit, little-endian, data-type-policy=OVERRIDE, base-type=uint16, compu {phys=raw-250; unit cm}, range phys -250..770
          signal ControlCoordinatesFBD_SMR_Y: start 449, 10 bit, little-endian, data-type-policy=OVERRIDE, base-type=uint16, compu {phys=raw-250; unit cm}, range phys -250..770
          signal ControlCoordinatesFBD_SMR_Z: start 459, 10 bit, little-endian, data-type-policy=OVERRIDE, base-type=uint16, compu {phys=raw-250; unit cm}, range phys -250..770
          signal ControlCoordinatesFBD_SMR_azimuth: start 469, 9 bit, little-endian, data-type-policy=OVERRIDE, base-type=uint16, compu {phys=raw-180; unit °}, range phys -180..180
          signal ControlCoordinatesFBD_SMR_elevation: start 478, 8 bit, little-endian, data-type-policy=OVERRIDE, base-type=uint8, compu {phys=raw-100; unit °}, range phys -100..100
      frame ControlCPDSession: id 0x12E, frame-length=20, can-addressing-mode=STANDARD, can-frame-rx-behavior=CAN-FD, can-frame-tx-behavior=CAN-FD
        pdu ControlCPDSession: length=20, unused-bit-pattern=0
          signal ControlCPDSession_Address: start 0, 16 bit, little-endian, data-type-policy=OVERRIDE, compu {phys=raw}
          signal ControlCPDSession_Command: start 16, 8 bit, little-endian, data-type-policy=OVERRIDE, compu {phys=raw}
          signal ControlCPDSession_SensitivityBoost: start 24, 8 bit, little-endian, data-type-policy=OVERRIDE, compu {phys=raw}
          signal ControlCPDSession_CycleTime: start 32, 8 bit, little-endian, data-type-policy=OVERRIDE, compu {phys=raw}
          signal ControlCPDSession_Channel: start 40, 8 bit, little-endian, data-type-policy=OVERRIDE, compu {phys=raw}
          signal ControlCPDSession_NoiseSuppression: start 48, 8 bit, little-endian, data-type-policy=OVERRIDE, compu {phys=raw}
          signal ControlCPDSession_SessionPriority: start 56, 8 bit, little-endian, data-type-policy=OVERRIDE, base-type=uint8, compu {phys=raw}, range phys 0..252
          signal ControlCPDSession_Sign: start 64, 32 bit, little-endian, data-type-policy=OVERRIDE, base-type=uint32, compu {phys=raw}, range phys 0..4294967294
          signal ControlCPDSession_Data00: start 96, 8 bit, little-endian, data-type-policy=OVERRIDE, base-type=uint8, compu {phys=raw}, range phys 0..255
          signal ControlCPDSession_Data01: start 104, 8 bit, little-endian, data-type-policy=OVERRIDE, base-type=uint8, compu {phys=raw}, range phys 0..255
          signal ControlCPDSession_Data02: start 112, 8 bit, little-endian, data-type-policy=OVERRIDE, base-type=uint8, compu {phys=raw}, range phys 0..255
          signal ControlCPDSession_Data03: start 120, 8 bit, little-endian, data-type-policy=OVERRIDE, base-type=uint8, compu {phys=raw}, range phys 0..255
          signal ControlCPDSession_Data04: start 128, 8 bit, little-endian, data-type-policy=OVERRIDE, base-type=uint8, compu {phys=raw}, range phys 0..255
          signal ControlCPDSession_Data05: start 136, 8 bit, little-endian, data-type-policy=OVERRIDE, base-type=uint8, compu {phys=raw}, range phys 0..255
          signal ControlCPDSession_Data06: start 144, 8 bit, little-endian, data-type-policy=OVERRIDE, base-type=uint8, compu {phys=raw}, range phys 0..255
          signal ControlCPDSession_Data07: start 152, 8 bit, little-endian, data-type-policy=OVERRIDE, base-type=uint8, compu {phys=raw}, range phys 0..255
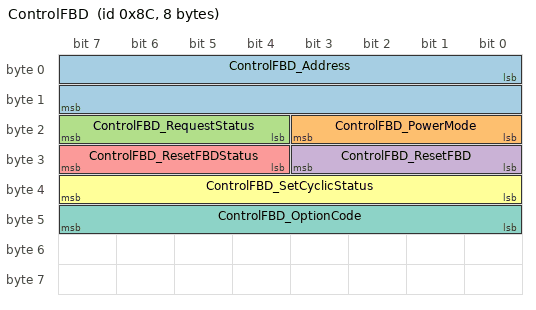
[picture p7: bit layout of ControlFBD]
      frame ControlFBD: id 0x8C, frame-length=8, can-addressing-mode=STANDARD, can-frame-rx-behavior=CAN-20, can-frame-tx-behavior=CAN-20
        pdu ControlFBD: length=8, unused-bit-pattern=0
          signal ControlFBD_Address: start 0, 16 bit, little-endian, data-type-policy=OVERRIDE, compu {phys=raw}
          signal ControlFBD_PowerMode: start 16, 4 bit, little-endian, data-type-policy=OVERRIDE, compu {phys=raw}
          signal ControlFBD_RequestStatus: start 20, 4 bit, little-endian, data-type-policy=OVERRIDE, base-type=uint8, compu {phys=raw}, range phys 0..12
          signal ControlFBD_ResetFBD: start 24, 4 bit, little-endian, data-type-policy=OVERRIDE, base-type=uint8, compu {phys=raw}, range phys 0..12
          signal ControlFBD_ResetFBDStatus: start 28, 4 bit, little-endian, data-type-policy=OVERRIDE, base-type=uint8, compu {phys=raw}, range phys 0..12
          signal ControlFBD_SetCyclicStatus: start 32, 8 bit, little-endian, data-type-policy=OVERRIDE, base-type=uint8, compu {phys=raw}, range phys 0..252
          signal ControlFBD_OptionCode: start 40, 8 bit, little-endian, data-type-policy=OVERRIDE, compu {phys=raw}
      frame ControlRangingSession: id 0x192, frame-length=20, can-addressing-mode=STANDARD, can-frame-rx-behavior=CAN-FD, can-frame-tx-behavior=CAN-FD
        pdu ControlRangingSession: length=20, unused-bit-pattern=0
          signal ControlRangingSession_Address: start 0, 16 bit, little-endian, data-type-policy=OVERRIDE, compu {phys=raw}
          signal ControlRangingSession_Function: start 16, 8 bit, little-endian, data-type-policy=OVERRIDE, compu {phys=raw}
          signal ControlRangingSession_SessionIDShort: start 24, 8 bit, little-endian, data-type-policy=OVERRIDE, base-type=uint8, compu {phys=raw}, range phys 0..252
          signal ControlRangingSession_STSIndex: start 32, 32 bit, little-endian, data-type-policy=OVERRIDE, base-type=uint32, compu {phys=raw}, range phys 0..4294967292
          signal ControlRangingSession_RANmultiplier: start 64, 8 bit, little-endian, data-type-policy=OVERRIDE, base-type=uint8, compu {phys=raw}, range phys 0..252
          signal ControlRangingSession_UWBTime0: start 72, 64 bit, little-endian, data-type-policy=OVERRIDE, base-type=uint64, compu {phys=raw}, range phys 0..18446744073709551612
      frame ControlRangingSessionSetup1: id 0x190, frame-length=64, can-addressing-mode=STANDARD, can-frame-rx-behavior=CAN-FD, can-frame-tx-behavior=CAN-FD
        pdu ControlRangingSessionSetup1: length=64, unused-bit-pattern=0
          signal ControlRangingSessionSetup1_Address: start 0, 16 bit, little-endian, data-type-policy=OVERRIDE, compu {phys=raw}
          signal ControlRangingSessionSetup1_SessionIDShort: start 16, 8 bit, little-endian, data-type-policy=OVERRIDE, base-type=uint8, compu {phys=raw}, range phys 0..252
          signal ControlRangingSessionSetup1_ConfigLength: start 24, 16 bit, little-endian, data-type-policy=OVERRIDE, base-type=uint16, compu {phys=raw}, range phys 0..65532
          signal ControlRangingSessionSetup1_Configuration: start 40, 8 bit, little-endian, data-type-policy=OVERRIDE, compu {phys=raw}
          signal ControlRangingSessionSetup1_AutoStart: start 48, 8 bit, little-endian, data-type-policy=OVERRIDE, compu {phys=raw}
          signal ControlRangingSessionSetup1_BitmaskUWBAnchor: start 56, 16 bit, little-endian, data-type-policy=OVERRIDE, compu {phys=raw}
          signal ControlRangingSessionSetup1_ProtocolVersion: start 72, 16 bit, little-endian, data-type-policy=OVERRIDE, base-type=uint16, compu {phys=raw}, range phys 0..65532
          signal ControlRangingSessionSetup1_Data00: start 88, 8 bit, little-endian, data-type-policy=OVERRIDE, base-type=uint8, compu {phys=raw}, range phys 0..255
          signal ControlRangingSessionSetup1_Data01: start 96, 8 bit, little-endian, data-type-policy=OVERRIDE, base-type=uint8, compu {phys=raw}, range phys 0..255
          signal ControlRangingSessionSetup1_Data02: start 104, 8 bit, little-endian, data-type-policy=OVERRIDE, base-type=uint8, compu {phys=raw}, range phys 0..255
          signal ControlRangingSessionSetup1_Data03: start 112, 8 bit, little-endian, data-type-policy=OVERRIDE, base-type=uint8, compu {phys=raw}, range phys 0..255
          signal ControlRangingSessionSetup1_Data04: start 120, 8 bit, little-endian, data-type-policy=OVERRIDE, base-type=uint8, compu {phys=raw}, range phys 0..255
          signal ControlRangingSessionSetup1_Data05: start 128, 8 bit, little-endian, data-type-policy=OVERRIDE, base-type=uint8, compu {phys=raw}, range phys 0..255
          signal ControlRangingSessionSetup1_Data06: start 136, 8 bit, little-endian, data-type-policy=OVERRIDE, base-type=uint8, compu {phys=raw}, range phys 0..255
          signal ControlRangingSessionSetup1_Data07: start 144, 8 bit, little-endian, data-type-policy=OVERRIDE, base-type=uint8, compu {phys=raw}, range phys 0..255
          signal ControlRangingSessionSetup1_Data08: start 152, 8 bit, little-endian, data-type-policy=OVERRIDE, base-type=uint8, compu {phys=raw}, range phys 0..255
          signal ControlRangingSessionSetup1_Data09: start 160, 8 bit, little-endian, data-type-policy=OVERRIDE, base-type=uint8, compu {phys=raw}, range phys 0..255
          signal ControlRangingSessionSetup1_Data10: start 168, 8 bit, little-endian, data-type-policy=OVERRIDE, base-type=uint8, compu {phys=raw}, range phys 0..255
          signal ControlRangingSessionSetup1_Data11: start 176, 8 bit, little-endian, data-type-policy=OVERRIDE, base-type=uint8, compu {phys=raw}, range phys 0..255
          signal ControlRangingSessionSetup1_Data12: start 184, 8 bit, little-endian, data-type-policy=OVERRIDE, base-type=uint8, compu {phys=raw}, range phys 0..255
          signal ControlRangingSessionSetup1_Data13: start 192, 8 bit, little-endian, data-type-policy=OVERRIDE, base-type=uint8, compu {phys=raw}, range phys 0..255
          signal ControlRangingSessionSetup1_Data14: start 200, 8 bit, little-endian, data-type-policy=OVERRIDE, base-type=uint8, compu {phys=raw}, range phys 0..255
          signal ControlRangingSessionSetup1_Data15: start 208, 8 bit, little-endian, data-type-policy=OVERRIDE, base-type=uint8, compu {phys=raw}, range phys 0..255
          signal ControlRangingSessionSetup1_Data16: start 216, 8 bit, little-endian, data-type-policy=OVERRIDE, base-type=uint8, compu {phys=raw}, range phys 0..255
          signal ControlRangingSessionSetup1_Data17: start 224, 8 bit, little-endian, data-type-policy=OVERRIDE, base-type=uint8, compu {phys=raw}, range phys 0..255
          signal ControlRangingSessionSetup1_Data18: start 232, 8 bit, little-endian, data-type-policy=OVERRIDE, base-type=uint8, compu {phys=raw}, range phys 0..255
          signal ControlRangingSessionSetup1_Data19: start 240, 8 bit, little-endian, data-type-policy=OVERRIDE, base-type=uint8, compu {phys=raw}, range phys 0..255
          signal ControlRangingSessionSetup1_Data20: start 248, 8 bit, little-endian, data-type-policy=OVERRIDE, base-type=uint8, compu {phys=raw}, range phys 0..255
          signal ControlRangingSessionSetup1_Data21: start 256, 8 bit, little-endian, data-type-policy=OVERRIDE, base-type=uint8, compu {phys=raw}, range phys 0..255
          signal ControlRangingSessionSetup1_Data22: start 264, 8 bit, little-endian, data-type-policy=OVERRIDE, base-type=uint8, compu {phys=raw}, range phys 0..255
          signal ControlRangingSessionSetup1_Data23: start 272, 8 bit, little-endian, data-type-policy=OVERRIDE, base-type=uint8, compu {phys=raw}, range phys 0..255
          signal ControlRangingSessionSetup1_Data24: start 280, 8 bit, little-endian, data-type-policy=OVERRIDE, base-type=uint8, compu {phys=raw}, range phys 0..255
          signal ControlRangingSessionSetup1_Data25: start 288, 8 bit, little-endian, data-type-policy=OVERRIDE, base-type=uint8, compu {phys=raw}, range phys 0..255
          signal ControlRangingSessionSetup1_Data26: start 296, 8 bit, little-endian, data-type-policy=OVERRIDE, base-type=uint8, compu {phys=raw}, range phys 0..255
          signal ControlRangingSessionSetup1_Data27: start 304, 8 bit, little-endian, data-type-policy=OVERRIDE, base-type=uint8, compu {phys=raw}, range phys 0..255
          signal ControlRangingSessionSetup1_Data28: start 312, 8 bit, little-endian, data-type-policy=OVERRIDE, base-type=uint8, compu {phys=raw}, range phys 0..255
          signal ControlRangingSessionSetup1_Data29: start 320, 8 bit, little-endian, data-type-policy=OVERRIDE, base-type=uint8, compu {phys=raw}, range phys 0..255
          signal ControlRangingSessionSetup1_Data30: start 328, 8 bit, little-endian, data-type-policy=OVERRIDE, base-type=uint8, compu {phys=raw}, range phys 0..255
          signal ControlRangingSessionSetup1_Data31: start 336, 8 bit, little-endian, data-type-policy=OVERRIDE, base-type=uint8, compu {phys=raw}, range phys 0..255
          signal ControlRangingSessionSetup1_Data32: start 344, 8 bit, little-endian, data-type-policy=OVERRIDE, base-type=uint8, compu {phys=raw}, range phys 0..255
          signal ControlRangingSessionSetup1_Data33: start 352, 8 bit, little-endian, data-type-policy=OVERRIDE, base-type=uint8, compu {phys=raw}, range phys 0..255
          signal ControlRangingSessionSetup1_Data34: start 360, 8 bit, little-endian, data-type-policy=OVERRIDE, base-type=uint8, compu {phys=raw}, range phys 0..255
          signal ControlRangingSessionSetup1_Data35: start 368, 8 bit, little-endian, data-type-policy=OVERRIDE, base-type=uint8, compu {phys=raw}, range phys 0..255
          signal ControlRangingSessionSetup1_Data36: start 376, 8 bit, little-endian, data-type-policy=OVERRIDE, base-type=uint8, compu {phys=raw}, range phys 0..255
          signal ControlRangingSessionSetup1_Data37: start 384, 8 bit, little-endian, data-type-policy=OVERRIDE, base-type=uint8, compu {phys=raw}, range phys 0..255
          signal ControlRangingSessionSetup1_Data38: start 392, 8 bit, little-endian, data-type-policy=OVERRIDE, base-type=uint8, compu {phys=raw}, range phys 0..255
          signal ControlRangingSessionSetup1_Data39: start 400, 8 bit, little-endian, data-type-policy=OVERRIDE, base-type=uint8, compu {phys=raw}, range phys 0..255
          signal ControlRangingSessionSetup1_Data40: start 408, 8 bit, little-endian, data-type-policy=OVERRIDE, base-type=uint8, compu {phys=raw}, range phys 0..255
          signal ControlRangingSessionSetup1_Data41: start 416, 8 bit, little-endian, data-type-policy=OVERRIDE, base-type=uint8, compu {phys=raw}, range phys 0..255
          signal ControlRangingSessionSetup1_Data42: start 424, 8 bit, little-endian, data-type-policy=OVERRIDE, base-type=uint8, compu {phys=raw}, range phys 0..255
          signal ControlRangingSessionSetup1_Data43: start 432, 8 bit, little-endian, data-type-policy=OVERRIDE, base-type=uint8, compu {phys=raw}, range phys 0..255
          signal ControlRangingSessionSetup1_Data44: start 440, 8 bit, little-endian, data-type-policy=OVERRIDE, base-type=uint8, compu {phys=raw}, range phys 0..255
          signal ControlRangingSessionSetup1_Data45: start 448, 8 bit, little-endian, data-type-policy=OVERRIDE, base-type=uint8, compu {phys=raw}, range phys 0..255
          signal ControlRangingSessionSetup1_Data46: start 456, 8 bit, little-endian, data-type-policy=OVERRIDE, base-type=uint8, compu {phys=raw}, range phys 0..255
          signal ControlRangingSessionSetup1_Data47: start 464, 8 bit, little-endian, data-type-policy=OVERRIDE, base-type=uint8, compu {phys=raw}, range phys 0..255
          signal ControlRangingSessionSetup1_Data48: start 472, 8 bit, little-endian, data-type-policy=OVERRIDE, base-type=uint8, compu {phys=raw}, range phys 0..255
          signal ControlRangingSessionSetup1_Data49: start 480, 8 bit, little-endian, data-type-policy=OVERRIDE, base-type=uint8, compu {phys=raw}, range phys 0..255
          signal ControlRangingSessionSetup1_Data50: start 488, 8 bit, little-endian, data-type-policy=OVERRIDE, base-type=uint8, compu {phys=raw}, range phys 0..255
          signal ControlRangingSessionSetup1_Data51: start 496, 8 bit, little-endian, data-type-policy=OVERRIDE, base-type=uint8, compu {phys=raw}, range phys 0..255
          signal ControlRangingSessionSetup1_Data52: start 504, 8 bit, little-endian, data-type-policy=OVERRIDE, base-type=uint8, compu {phys=raw}, range phys 0..255
      frame ControlRangingSessionSetup2: id 0x191, frame-length=64, can-addressing-mode=STANDARD, can-frame-rx-behavior=CAN-FD, can-frame-tx-behavior=CAN-FD
        pdu ControlRangingSessionSetup2: length=64, unused-bit-pattern=0
          signal ControlRangingSessionSetup2_Address: start 0, 16 bit, little-endian, data-type-policy=OVERRIDE, compu {phys=raw}
          signal ControlRangingSessionSetup2_SessionIDShort: start 16, 8 bit, little-endian, data-type-policy=OVERRIDE, base-type=uint8, compu {phys=raw}, range phys 0..252
          signal ControlRangingSessionSetup2_Data53: start 24, 8 bit, little-endian, data-type-policy=OVERRIDE, base-type=uint8, compu {phys=raw}, range phys 0..255
          signal ControlRangingSessionSetup2_Data54: start 32, 8 bit, little-endian, data-type-policy=OVERRIDE, base-type=uint8, compu {phys=raw}, range phys 0..255
          signal ControlRangingSessionSetup2_Data55: start 40, 8 bit, little-endian, data-type-policy=OVERRIDE, base-type=uint8, compu {phys=raw}, range phys 0..255
          signal ControlRangingSessionSetup2_Data56: start 48, 8 bit, little-endian, data-type-policy=OVERRIDE, base-type=uint8, compu {phys=raw}, range phys 0..255
          signal ControlRangingSessionSetup2_Data57: start 56, 8 bit, little-endian, data-type-policy=OVERRIDE, base-type=uint8, compu {phys=raw}, range phys 0..255
          signal ControlRangingSessionSetup2_Data58: start 64, 8 bit, little-endian, data-type-policy=OVERRIDE, base-type=uint8, compu {phys=raw}, range phys 0..255
          signal ControlRangingSessionSetup2_Data59: start 72, 8 bit, little-endian, data-type-policy=OVERRIDE, base-type=uint8, compu {phys=raw}, range phys 0..255
          signal ControlRangingSessionSetup2_Data60: start 80, 8 bit, little-endian, data-type-policy=OVERRIDE, base-type=uint8, compu {phys=raw}, range phys 0..255
          signal ControlRangingSessionSetup2_Data61: start 88, 8 bit, little-endian, data-type-policy=OVERRIDE, base-type=uint8, compu {phys=raw}, range phys 0..255
          signal ControlRangingSessionSetup2_Data62: start 96, 8 bit, little-endian, data-type-policy=OVERRIDE, base-type=uint8, compu {phys=raw}, range phys 0..255
          signal ControlRangingSessionSetup2_Data63: start 104, 8 bit, little-endian, data-type-policy=OVERRIDE, base-type=uint8, compu {phys=raw}, range phys 0..255
          signal ControlRangingSessionSetup2_Data64: start 112, 8 bit, little-endian, data-type-policy=OVERRIDE, base-type=uint8, compu {phys=raw}, range phys 0..255
          signal ControlRangingSessionSetup2_Data65: start 120, 8 bit, little-endian, data-type-policy=OVERRIDE, base-type=uint8, compu {phys=raw}, range phys 0..255
          signal ControlRangingSessionSetup2_Data66: start 128, 8 bit, little-endian, data-type-policy=OVERRIDE, base-type=uint8, compu {phys=raw}, range phys 0..255
          signal ControlRangingSessionSetup2_Data67: start 136, 8 bit, little-endian, data-type-policy=OVERRIDE, base-type=uint8, compu {phys=raw}, range phys 0..255
          signal ControlRangingSessionSetup2_Data68: start 144, 8 bit, little-endian, data-type-policy=OVERRIDE, base-type=uint8, compu {phys=raw}, range phys 0..255
          signal ControlRangingSessionSetup2_Data69: start 152, 8 bit, little-endian, data-type-policy=OVERRIDE, base-type=uint8, compu {phys=raw}, range phys 0..255
          signal ControlRangingSessionSetup2_Data70: start 160, 8 bit, little-endian, data-type-policy=OVERRIDE, base-type=uint8, compu {phys=raw}, range phys 0..255
          signal ControlRangingSessionSetup2_Data71: start 168, 8 bit, little-endian, data-type-policy=OVERRIDE, base-type=uint8, compu {phys=raw}, range phys 0..255
          signal ControlRangingSessionSetup2_Data72: start 176, 8 bit, little-endian, data-type-policy=OVERRIDE, base-type=uint8, compu {phys=raw}, range phys 0..255
          signal ControlRangingSessionSetup2_Data73: start 184, 8 bit, little-endian, data-type-policy=OVERRIDE, base-type=uint8, compu {phys=raw}, range phys 0..255
          signal ControlRangingSessionSetup2_Data74: start 192, 8 bit, little-endian, data-type-policy=OVERRIDE, base-type=uint8, compu {phys=raw}, range phys 0..255
          signal ControlRangingSessionSetup2_Data75: start 200, 8 bit, little-endian, data-type-policy=OVERRIDE, base-type=uint8, compu {phys=raw}, range phys 0..255
          signal ControlRangingSessionSetup2_Data76: start 208, 8 bit, little-endian, data-type-policy=OVERRIDE, base-type=uint8, compu {phys=raw}, range phys 0..255
          signal ControlRangingSessionSetup2_Data77: start 216, 8 bit, little-endian, data-type-policy=OVERRIDE, base-type=uint8, compu {phys=raw}, range phys 0..255
          signal ControlRangingSessionSetup2_Data78: start 224, 8 bit, little-endian, data-type-policy=OVERRIDE, base-type=uint8, compu {phys=raw}, range phys 0..255
          signal ControlRangingSessionSetup2_Data79: start 232, 8 bit, little-endian, data-type-policy=OVERRIDE, base-type=uint8, compu {phys=raw}, range phys 0..255
          signal ControlRangingSessionSetup2_Data80: start 240, 8 bit, little-endian, data-type-policy=OVERRIDE, base-type=uint8, compu {phys=raw}, range phys 0..255
          signal ControlRangingSessionSetup2_Data81: start 248, 8 bit, little-endian, data-type-policy=OVERRIDE, base-type=uint8, compu {phys=raw}, range phys 0..255
          signal ControlRangingSessionSetup2_Data82: start 256, 8 bit, little-endian, data-type-policy=OVERRIDE, base-type=uint8, compu {phys=raw}, range phys 0..255
          signal ControlRangingSessionSetup2_Data83: start 264, 8 bit, little-endian, data-type-policy=OVERRIDE, base-type=uint8, compu {phys=raw}, range phys 0..255
          signal ControlRangingSessionSetup2_Data84: start 272, 8 bit, little-endian, data-type-policy=OVERRIDE, base-type=uint8, compu {phys=raw}, range phys 0..255
          signal ControlRangingSessionSetup2_Data85: start 280, 8 bit, little-endian, data-type-policy=OVERRIDE, base-type=uint8, compu {phys=raw}, range phys 0..255
          signal ControlRangingSessionSetup2_Data86: start 288, 8 bit, little-endian, data-type-policy=OVERRIDE, base-type=uint8, compu {phys=raw}, range phys 0..255
          signal ControlRangingSessionSetup2_Data87: start 296, 8 bit, little-endian, data-type-policy=OVERRIDE, base-type=uint8, compu {phys=raw}, range phys 0..255
          signal ControlRangingSessionSetup2_Data88: start 304, 8 bit, little-endian, data-type-policy=OVERRIDE, base-type=uint8, compu {phys=raw}, range phys 0..255
          signal ControlRangingSessionSetup2_Data89: start 312, 8 bit, little-endian, data-type-policy=OVERRIDE, base-type=uint8, compu {phys=raw}, range phys 0..255
          signal ControlRangingSessionSetup2_Data90: start 320, 8 bit, little-endian, data-type-policy=OVERRIDE, base-type=uint8, compu {phys=raw}, range phys 0..255
          signal ControlRangingSessionSetup2_Data91: start 328, 8 bit, little-endian, data-type-policy=OVERRIDE, base-type=uint8, compu {phys=raw}, range phys 0..255
          signal ControlRangingSessionSetup2_Data92: start 336, 8 bit, little-endian, data-type-policy=OVERRIDE, base-type=uint8, compu {phys=raw}, range phys 0..255
          signal ControlRangingSessionSetup2_Data93: start 344, 8 bit, little-endian, data-type-policy=OVERRIDE, base-type=uint8, compu {phys=raw}, range phys 0..255
          signal ControlRangingSessionSetup2_Data94: start 352, 8 bit, little-endian, data-type-policy=OVERRIDE, base-type=uint8, compu {phys=raw}, range phys 0..255
          signal ControlRangingSessionSetup2_Data95: start 360, 8 bit, little-endian, data-type-policy=OVERRIDE, base-type=uint8, compu {phys=raw}, range phys 0..255
          signal ControlRangingSessionSetup2_Data96: start 368, 8 bit, little-endian, data-type-policy=OVERRIDE, base-type=uint8, compu {phys=raw}, range phys 0..255
          signal ControlRangingSessionSetup2_Data97: start 376, 8 bit, little-endian, data-type-policy=OVERRIDE, base-type=uint8, compu {phys=raw}, range phys 0..255
          signal ControlRangingSessionSetup2_Data98: start 384, 8 bit, little-endian, data-type-policy=OVERRIDE, base-type=uint8, compu {phys=raw}, range phys 0..255
          signal ControlRangingSessionSetup2_Data99: start 392, 8 bit, little-endian, data-type-policy=OVERRIDE, base-type=uint8, compu {phys=raw}, range phys 0..255
          signal ControlRangingSessionSetup2_Data100: start 400, 8 bit, little-endian, data-type-policy=OVERRIDE, base-type=uint8, compu {phys=raw}, range phys 0..255
          signal ControlRangingSessionSetup2_Data101: start 408, 8 bit, little-endian, data-type-policy=OVERRIDE, base-type=uint8, compu {phys=raw}, range phys 0..255
          signal ControlRangingSessionSetup2_Data102: start 416, 8 bit, little-endian, data-type-policy=OVERRIDE, base-type=uint8, compu {phys=raw}, range phys 0..255
          signal ControlRangingSessionSetup2_Data103: start 424, 8 bit, little-endian, data-type-policy=OVERRIDE, base-type=uint8, compu {phys=raw}, range phys 0..255
          signal ControlRangingSessionSetup2_Data104: start 432, 8 bit, little-endian, data-type-policy=OVERRIDE, base-type=uint8, compu {phys=raw}, range phys 0..255
          signal ControlRangingSessionSetup2_Data105: start 440, 8 bit, little-endian, data-type-policy=OVERRIDE, base-type=uint8, compu {phys=raw}, range phys 0..255
          signal ControlRangingSessionSetup2_Data106: start 448, 8 bit, little-endian, data-type-policy=OVERRIDE, base-type=uint8, compu {phys=raw}, range phys 0..255
          signal ControlRangingSessionSetup2_Data107: start 456, 8 bit, little-endian, data-type-policy=OVERRIDE, base-type=uint8, compu {phys=raw}, range phys 0..255
          signal ControlRangingSessionSetup2_Data108: start 464, 8 bit, little-endian, data-type-policy=OVERRIDE, base-type=uint8, compu {phys=raw}, range phys 0..255
          signal ControlRangingSessionSetup2_Data109: start 472, 8 bit, little-endian, data-type-policy=OVERRIDE, base-type=uint8, compu {phys=raw}, range phys 0..255
          signal ControlRangingSessionSetup2_Data110: start 480, 8 bit, little-endian, data-type-policy=OVERRIDE, base-type=uint8, compu {phys=raw}, range phys 0..255
          signal ControlRangingSessionSetup2_Data111: start 488, 8 bit, little-endian, data-type-policy=OVERRIDE, base-type=uint8, compu {phys=raw}, range phys 0..255
          signal ControlRangingSessionSetup2_Data112: start 496, 8 bit, little-endian, data-type-policy=OVERRIDE, base-type=uint8, compu {phys=raw}, range phys 0..255
          signal ControlRangingSessionSetup2_Data113: start 504, 8 bit, little-endian, data-type-policy=OVERRIDE, base-type=uint8, compu {phys=raw}, range phys 0..255
      frame ControlRangingSessionSetup3: id 0x194, frame-length=64, can-addressing-mode=STANDARD, can-frame-rx-behavior=CAN-FD, can-frame-tx-behavior=CAN-FD
        pdu ControlRangingSessionSetup3: length=64, unused-bit-pattern=0
          signal ControlRangingSessionSetup3_Address: start 0, 16 bit, little-endian, data-type-policy=OVERRIDE, compu {phys=raw}
          signal ControlRangingSessionSetup3_SessionIDShort: start 16, 8 bit, little-endian, data-type-policy=OVERRIDE, base-type=uint8, compu {phys=raw}, range phys 0..252
          signal ControlRangingSessionSetup3_Data114: start 24, 8 bit, little-endian, data-type-policy=OVERRIDE, base-type=uint8, compu {phys=raw}, range phys 0..255
          signal ControlRangingSessionSetup3_Data115: start 32, 8 bit, little-endian, data-type-policy=OVERRIDE, base-type=uint8, compu {phys=raw}, range phys 0..255
          signal ControlRangingSessionSetup3_Data116: start 40, 8 bit, little-endian, data-type-policy=OVERRIDE, base-type=uint8, compu {phys=raw}, range phys 0..255
          signal ControlRangingSessionSetup3_Data117: start 48, 8 bit, little-endian, data-type-policy=OVERRIDE, base-type=uint8, compu {phys=raw}, range phys 0..255
          signal ControlRangingSessionSetup3_Data118: start 56, 8 bit, little-endian, data-type-policy=OVERRIDE, base-type=uint8, compu {phys=raw}, range phys 0..255
          signal ControlRangingSessionSetup3_Data119: start 64, 8 bit, little-endian, data-type-policy=OVERRIDE, base-type=uint8, compu {phys=raw}, range phys 0..255
          signal ControlRangingSessionSetup3_Data120: start 72, 8 bit, little-endian, data-type-policy=OVERRIDE, base-type=uint8, compu {phys=raw}, range phys 0..255
          signal ControlRangingSessionSetup3_Data121: start 80, 8 bit, little-endian, data-type-policy=OVERRIDE, base-type=uint8, compu {phys=raw}, range phys 0..255
          signal ControlRangingSessionSetup3_Data122: start 88, 8 bit, little-endian, data-type-policy=OVERRIDE, base-type=uint8, compu {phys=raw}, range phys 0..255
          signal ControlRangingSessionSetup3_Data123: start 96, 8 bit, little-endian, data-type-policy=OVERRIDE, base-type=uint8, compu {phys=raw}, range phys 0..255
          signal ControlRangingSessionSetup3_Data124: start 104, 8 bit, little-endian, data-type-policy=OVERRIDE, base-type=uint8, compu {phys=raw}, range phys 0..255
          signal ControlRangingSessionSetup3_Data125: start 112, 8 bit, little-endian, data-type-policy=OVERRIDE, base-type=uint8, compu {phys=raw}, range phys 0..255
          signal ControlRangingSessionSetup3_Data126: start 120, 8 bit, little-endian, data-type-policy=OVERRIDE, base-type=uint8, compu {phys=raw}, range phys 0..255
          signal ControlRangingSessionSetup3_Data127: start 128, 8 bit, little-endian, data-type-policy=OVERRIDE, base-type=uint8, compu {phys=raw}, range phys 0..255
          signal ControlRangingSessionSetup3_Data128: start 136, 8 bit, little-endian, data-type-policy=OVERRIDE, base-type=uint8, compu {phys=raw}, range phys 0..255
          signal ControlRangingSessionSetup3_Data129: start 144, 8 bit, little-endian, data-type-policy=OVERRIDE, base-type=uint8, compu {phys=raw}, range phys 0..255
          signal ControlRangingSessionSetup3_Data130: start 152, 8 bit, little-endian, data-type-policy=OVERRIDE, base-type=uint8, compu {phys=raw}, range phys 0..255
          signal ControlRangingSessionSetup3_Data131: start 160, 8 bit, little-endian, data-type-policy=OVERRIDE, base-type=uint8, compu {phys=raw}, range phys 0..255
          signal ControlRangingSessionSetup3_Data132: start 168, 8 bit, little-endian, data-type-policy=OVERRIDE, base-type=uint8, compu {phys=raw}, range phys 0..255
          signal ControlRangingSessionSetup3_Data133: start 176, 8 bit, little-endian, data-type-policy=OVERRIDE, base-type=uint8, compu {phys=raw}, range phys 0..255
          signal ControlRangingSessionSetup3_Data134: start 184, 8 bit, little-endian, data-type-policy=OVERRIDE, base-type=uint8, compu {phys=raw}, range phys 0..255
          signal ControlRangingSessionSetup3_Data135: start 192, 8 bit, little-endian, data-type-policy=OVERRIDE, base-type=uint8, compu {phys=raw}, range phys 0..255
          signal ControlRangingSessionSetup3_Data136: start 200, 8 bit, little-endian, data-type-policy=OVERRIDE, base-type=uint8, compu {phys=raw}, range phys 0..255
          signal ControlRangingSessionSetup3_Data137: start 208, 8 bit, little-endian, data-type-policy=OVERRIDE, base-type=uint8, compu {phys=raw}, range phys 0..255
          signal ControlRangingSessionSetup3_Data138: start 216, 8 bit, little-endian, data-type-policy=OVERRIDE, base-type=uint8, compu {phys=raw}, range phys 0..255
          signal ControlRangingSessionSetup3_Data139: start 224, 8 bit, little-endian, data-type-policy=OVERRIDE, base-type=uint8, compu {phys=raw}, range phys 0..255
          signal ControlRangingSessionSetup3_Data140: start 232, 8 bit, little-endian, data-type-policy=OVERRIDE, base-type=uint8, compu {phys=raw}, range phys 0..255
          signal ControlRangingSessionSetup3_Data141: start 240, 8 bit, little-endian, data-type-policy=OVERRIDE, base-type=uint8, compu {phys=raw}, range phys 0..255
          signal ControlRangingSessionSetup3_Data142: start 248, 8 bit, little-endian, data-type-policy=OVERRIDE, base-type=uint8, compu {phys=raw}, range phys 0..255
          signal ControlRangingSessionSetup3_Data143: start 256, 8 bit, little-endian, data-type-policy=OVERRIDE, base-type=uint8, compu {phys=raw}, range phys 0..255
          signal ControlRangingSessionSetup3_Data144: start 264, 8 bit, little-endian, data-type-policy=OVERRIDE, base-type=uint8, compu {phys=raw}, range phys 0..255
          signal ControlRangingSessionSetup3_Data145: start 272, 8 bit, little-endian, data-type-policy=OVERRIDE, base-type=uint8, compu {phys=raw}, range phys 0..255
          signal ControlRangingSessionSetup3_Data146: start 280, 8 bit, little-endian, data-type-policy=OVERRIDE, base-type=uint8, compu {phys=raw}, range phys 0..255
          signal ControlRangingSessionSetup3_Data147: start 288, 8 bit, little-endian, data-type-policy=OVERRIDE, base-type=uint8, compu {phys=raw}, range phys 0..255
          signal ControlRangingSessionSetup3_Data148: start 296, 8 bit, little-endian, data-type-policy=OVERRIDE, base-type=uint8, compu {phys=raw}, range phys 0..255
          signal ControlRangingSessionSetup3_Data149: start 304, 8 bit, little-endian, data-type-policy=OVERRIDE, base-type=uint8, compu {phys=raw}, range phys 0..255
          signal ControlRangingSessionSetup3_Data150: start 312, 8 bit, little-endian, data-type-policy=OVERRIDE, base-type=uint8, compu {phys=raw}, range phys 0..255
          signal ControlRangingSessionSetup3_Data151: start 320, 8 bit, little-endian, data-type-policy=OVERRIDE, base-type=uint8, compu {phys=raw}, range phys 0..255
          signal ControlRangingSessionSetup3_Data152: start 328, 8 bit, little-endian, data-type-policy=OVERRIDE, base-type=uint8, compu {phys=raw}, range phys 0..255
          signal ControlRangingSessionSetup3_Data153: start 336, 8 bit, little-endian, data-type-policy=OVERRIDE, base-type=uint8, compu {phys=raw}, range phys 0..255
          signal ControlRangingSessionSetup3_Data154: start 344, 8 bit, little-endian, data-type-policy=OVERRIDE, base-type=uint8, compu {phys=raw}, range phys 0..255
          signal ControlRangingSessionSetup3_Data155: start 352, 8 bit, little-endian, data-type-policy=OVERRIDE, base-type=uint8, compu {phys=raw}, range phys 0..255
          signal ControlRangingSessionSetup3_Data156: start 360, 8 bit, little-endian, data-type-policy=OVERRIDE, base-type=uint8, compu {phys=raw}, range phys 0..255
          signal ControlRangingSessionSetup3_Data157: start 368, 8 bit, little-endian, data-type-policy=OVERRIDE, base-type=uint8, compu {phys=raw}, range phys 0..255
          signal ControlRangingSessionSetup3_Data158: start 376, 8 bit, little-endian, data-type-policy=OVERRIDE, base-type=uint8, compu {phys=raw}, range phys 0..255
          signal ControlRangingSessionSetup3_Data159: start 384, 8 bit, little-endian, data-type-policy=OVERRIDE, base-type=uint8, compu {phys=raw}, range phys 0..255
          signal ControlRangingSessionSetup3_Data160: start 392, 8 bit, little-endian, data-type-policy=OVERRIDE, base-type=uint8, compu {phys=raw}, range phys 0..255
          signal ControlRangingSessionSetup3_Data161: start 400, 8 bit, little-endian, data-type-policy=OVERRIDE, base-type=uint8, compu {phys=raw}, range phys 0..255
          signal ControlRangingSessionSetup3_Data162: start 408, 8 bit, little-endian, data-type-policy=OVERRIDE, base-type=uint8, compu {phys=raw}, range phys 0..255
          signal ControlRangingSessionSetup3_Data163: start 416, 8 bit, little-endian, data-type-policy=OVERRIDE, base-type=uint8, compu {phys=raw}, range phys 0..255
          signal ControlRangingSessionSetup3_Data164: start 424, 8 bit, little-endian, data-type-policy=OVERRIDE, base-type=uint8, compu {phys=raw}, range phys 0..255
          signal ControlRangingSessionSetup3_Data165: start 432, 8 bit, little-endian, data-type-policy=OVERRIDE, base-type=uint8, compu {phys=raw}, range phys 0..255
          signal ControlRangingSessionSetup3_Data166: start 440, 8 bit, little-endian, data-type-policy=OVERRIDE, base-type=uint8, compu {phys=raw}, range phys 0..255
          signal ControlRangingSessionSetup3_Data167: start 448, 8 bit, little-endian, data-type-policy=OVERRIDE, base-type=uint8, compu {phys=raw}, range phys 0..255
          signal ControlRangingSessionSetup3_Data168: start 456, 8 bit, little-endian, data-type-policy=OVERRIDE, base-type=uint8, compu {phys=raw}, range phys 0..255
          signal ControlRangingSessionSetup3_Data169: start 464, 8 bit, little-endian, data-type-policy=OVERRIDE, base-type=uint8, compu {phys=raw}, range phys 0..255
          signal ControlRangingSessionSetup3_Data170: start 472, 8 bit, little-endian, data-type-policy=OVERRIDE, base-type=uint8, compu {phys=raw}, range phys 0..255
          signal ControlRangingSessionSetup3_Data171: start 480, 8 bit, little-endian, data-type-policy=OVERRIDE, base-type=uint8, compu {phys=raw}, range phys 0..255
          signal ControlRangingSessionSetup3_Data172: start 488, 8 bit, little-endian, data-type-policy=OVERRIDE, base-type=uint8, compu {phys=raw}, range phys 0..255
          signal ControlRangingSessionSetup3_Data173: start 496, 8 bit, little-endian, data-type-policy=OVERRIDE, base-type=uint8, compu {phys=raw}, range phys 0..255
          signal ControlRangingSessionSetup3_Data174: start 504, 8 bit, little-endian, data-type-policy=OVERRIDE, base-type=uint8, compu {phys=raw}, range phys 0..255
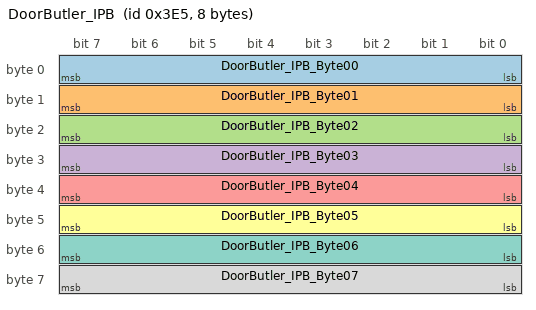
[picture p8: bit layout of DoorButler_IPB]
      frame DoorButler_IPB: id 0x3E5, frame-length=8, can-addressing-mode=STANDARD, can-frame-rx-behavior=CAN-20, can-frame-tx-behavior=CAN-20
        pdu DoorButler_IPB: length=8, unused-bit-pattern=0
          signal DoorButler_IPB_Byte00: start 0, 8 bit, little-endian, data-type-policy=OVERRIDE, base-type=uint8, compu {phys=raw}, range phys 0..252
          signal DoorButler_IPB_Byte01: start 8, 8 bit, little-endian, data-type-policy=OVERRIDE, base-type=uint8, compu {phys=raw}, range phys 0..252
          signal DoorButler_IPB_Byte02: start 16, 8 bit, little-endian, data-type-policy=OVERRIDE, base-type=uint8, compu {phys=raw}, range phys 0..252
          signal DoorButler_IPB_Byte03: start 24, 8 bit, little-endian, data-type-policy=OVERRIDE, base-type=uint8, compu {phys=raw}, range phys 0..252
          signal DoorButler_IPB_Byte04: start 32, 8 bit, little-endian, data-type-policy=OVERRIDE, base-type=uint8, compu {phys=raw}, range phys 0..252
          signal DoorButler_IPB_Byte05: start 40, 8 bit, little-endian, data-type-policy=OVERRIDE, base-type=uint8, compu {phys=raw}, range phys 0..252
          signal DoorButler_IPB_Byte06: start 48, 8 bit, little-endian, data-type-policy=OVERRIDE, base-type=uint8, compu {phys=raw}, range phys 0..252
          signal DoorButler_IPB_Byte07: start 56, 8 bit, little-endian, data-type-policy=OVERRIDE, base-type=uint8, compu {phys=raw}, range phys 0..252
      frame EndOfLineControlFBD: id 0x44C, frame-length=64, can-addressing-mode=STANDARD, can-frame-rx-behavior=CAN-FD, can-frame-tx-behavior=CAN-FD
        pdu EndOfLineControlFBD: length=64, unused-bit-pattern=0
          signal EndOfLineControlFBD_Byte00: start 0, 8 bit, little-endian, data-type-policy=OVERRIDE, base-type=uint8, compu {phys=raw}, range phys 0..252
          signal EndOfLineControlFBD_Byte01: start 8, 8 bit, little-endian, data-type-policy=OVERRIDE, base-type=uint8, compu {phys=raw}, range phys 0..252
          signal EndOfLineControlFBD_Byte02: start 16, 8 bit, little-endian, data-type-policy=OVERRIDE, base-type=uint8, compu {phys=raw}, range phys 0..252
          signal EndOfLineControlFBD_Byte03: start 24, 8 bit, little-endian, data-type-policy=OVERRIDE, base-type=uint8, compu {phys=raw}, range phys 0..252
          signal EndOfLineControlFBD_Byte04: start 32, 8 bit, little-endian, data-type-policy=OVERRIDE, base-type=uint8, compu {phys=raw}, range phys 0..252
          signal EndOfLineControlFBD_Byte05: start 40, 8 bit, little-endian, data-type-policy=OVERRIDE, base-type=uint8, compu {phys=raw}, range phys 0..252
          signal EndOfLineControlFBD_Byte06: start 48, 8 bit, little-endian, data-type-policy=OVERRIDE, base-type=uint8, compu {phys=raw}, range phys 0..252
          signal EndOfLineControlFBD_Byte07: start 56, 8 bit, little-endian, data-type-policy=OVERRIDE, base-type=uint8, compu {phys=raw}, range phys 0..252
          signal EndOfLineControlFBD_Byte08: start 64, 8 bit, little-endian, data-type-policy=OVERRIDE, base-type=uint8, compu {phys=raw}, range phys 0..252
          signal EndOfLineControlFBD_Byte09: start 72, 8 bit, little-endian, data-type-policy=OVERRIDE, base-type=uint8, compu {phys=raw}, range phys 0..252
          signal EndOfLineControlFBD_Byte10: start 80, 8 bit, little-endian, data-type-policy=OVERRIDE, base-type=uint8, compu {phys=raw}, range phys 0..252
          signal EndOfLineControlFBD_Byte11: start 88, 8 bit, little-endian, data-type-policy=OVERRIDE, base-type=uint8, compu {phys=raw}, range phys 0..252
          signal EndOfLineControlFBD_Byte12: start 96, 8 bit, little-endian, data-type-policy=OVERRIDE, base-type=uint8, compu {phys=raw}, range phys 0..252
          signal EndOfLineControlFBD_Byte13: start 104, 8 bit, little-endian, data-type-policy=OVERRIDE, base-type=uint8, compu {phys=raw}, range phys 0..252
          signal EndOfLineControlFBD_Byte14: start 112, 8 bit, little-endian, data-type-policy=OVERRIDE, base-type=uint8, compu {phys=raw}, range phys 0..252
          signal EndOfLineControlFBD_Byte15: start 120, 8 bit, little-endian, data-type-policy=OVERRIDE, base-type=uint8, compu {phys=raw}, range phys 0..252
          signal EndOfLineControlFBD_Byte16: start 128, 8 bit, little-endian, data-type-policy=OVERRIDE, base-type=uint8, compu {phys=raw}, range phys 0..252
          signal EndOfLineControlFBD_Byte17: start 136, 8 bit, little-endian, data-type-policy=OVERRIDE, base-type=uint8, compu {phys=raw}, range phys 0..252
          signal EndOfLineControlFBD_Byte18: start 144, 8 bit, little-endian, data-type-policy=OVERRIDE, base-type=uint8, compu {phys=raw}, range phys 0..252
          signal EndOfLineControlFBD_Byte19: start 152, 8 bit, little-endian, data-type-policy=OVERRIDE, base-type=uint8, compu {phys=raw}, range phys 0..252
          signal EndOfLineControlFBD_Byte20: start 160, 8 bit, little-endian, data-type-policy=OVERRIDE, base-type=uint8, compu {phys=raw}, range phys 0..252
          signal EndOfLineControlFBD_Byte21: start 168, 8 bit, little-endian, data-type-policy=OVERRIDE, base-type=uint8, compu {phys=raw}, range phys 0..252
          signal EndOfLineControlFBD_Byte22: start 176, 8 bit, little-endian, data-type-policy=OVERRIDE, base-type=uint8, compu {phys=raw}, range phys 0..252
          signal EndOfLineControlFBD_Byte23: start 184, 8 bit, little-endian, data-type-policy=OVERRIDE, base-type=uint8, compu {phys=raw}, range phys 0..252
          signal EndOfLineControlFBD_Byte24: start 192, 8 bit, little-endian, data-type-policy=OVERRIDE, base-type=uint8, compu {phys=raw}, range phys 0..252
          signal EndOfLineControlFBD_Byte25: start 200, 8 bit, little-endian, data-type-policy=OVERRIDE, base-type=uint8, compu {phys=raw}, range phys 0..252
          signal EndOfLineControlFBD_Byte26: start 208, 8 bit, little-endian, data-type-policy=OVERRIDE, base-type=uint8, compu {phys=raw}, range phys 0..252
          signal EndOfLineControlFBD_Byte27: start 216, 8 bit, little-endian, data-type-policy=OVERRIDE, base-type=uint8, compu {phys=raw}, range phys 0..252
          signal EndOfLineControlFBD_Byte28: start 224, 8 bit, little-endian, data-type-policy=OVERRIDE, base-type=uint8, compu {phys=raw}, range phys 0..252
          signal EndOfLineControlFBD_Byte29: start 232, 8 bit, little-endian, data-type-policy=OVERRIDE, base-type=uint8, compu {phys=raw}, range phys 0..252
          signal EndOfLineControlFBD_Byte30: start 240, 8 bit, little-endian, data-type-policy=OVERRIDE, base-type=uint8, compu {phys=raw}, range phys 0..252
          signal EndOfLineControlFBD_Byte31: start 248, 8 bit, little-endian, data-type-policy=OVERRIDE, base-type=uint8, compu {phys=raw}, range phys 0..252
          signal EndOfLineControlFBD_Byte32: start 256, 8 bit, little-endian, data-type-policy=OVERRIDE, base-type=uint8, compu {phys=raw}, range phys 0..252
          signal EndOfLineControlFBD_Byte33: start 264, 8 bit, little-endian, data-type-policy=OVERRIDE, base-type=uint8, compu {phys=raw}, range phys 0..252
          signal EndOfLineControlFBD_Byte34: start 272, 8 bit, little-endian, data-type-policy=OVERRIDE, base-type=uint8, compu {phys=raw}, range phys 0..252
          signal EndOfLineControlFBD_Byte35: start 280, 8 bit, little-endian, data-type-policy=OVERRIDE, base-type=uint8, compu {phys=raw}, range phys 0..252
          signal EndOfLineControlFBD_Byte36: start 288, 8 bit, little-endian, data-type-policy=OVERRIDE, base-type=uint8, compu {phys=raw}, range phys 0..252
          signal EndOfLineControlFBD_Byte37: start 296, 8 bit, little-endian, data-type-policy=OVERRIDE, base-type=uint8, compu {phys=raw}, range phys 0..252
          signal EndOfLineControlFBD_Byte38: start 304, 8 bit, little-endian, data-type-policy=OVERRIDE, base-type=uint8, compu {phys=raw}, range phys 0..252
          signal EndOfLineControlFBD_Byte39: start 312, 8 bit, little-endian, data-type-policy=OVERRIDE, base-type=uint8, compu {phys=raw}, range phys 0..252
          signal EndOfLineControlFBD_Byte40: start 320, 8 bit, little-endian, data-type-policy=OVERRIDE, base-type=uint8, compu {phys=raw}, range phys 0..252
          signal EndOfLineControlFBD_Byte41: start 328, 8 bit, little-endian, data-type-policy=OVERRIDE, base-type=uint8, compu {phys=raw}, range phys 0..252
          signal EndOfLineControlFBD_Byte42: start 336, 8 bit, little-endian, data-type-policy=OVERRIDE, base-type=uint8, compu {phys=raw}, range phys 0..252
          signal EndOfLineControlFBD_Byte43: start 344, 8 bit, little-endian, data-type-policy=OVERRIDE, base-type=uint8, compu {phys=raw}, range phys 0..252
          signal EndOfLineControlFBD_Byte44: start 352, 8 bit, little-endian, data-type-policy=OVERRIDE, base-type=uint8, compu {phys=raw}, range phys 0..252
          signal EndOfLineControlFBD_Byte45: start 360, 8 bit, little-endian, data-type-policy=OVERRIDE, base-type=uint8, compu {phys=raw}, range phys 0..252
          signal EndOfLineControlFBD_Byte46: start 368, 8 bit, little-endian, data-type-policy=OVERRIDE, base-type=uint8, compu {phys=raw}, range phys 0..252
          signal EndOfLineControlFBD_Byte47: start 376, 8 bit, little-endian, data-type-policy=OVERRIDE, base-type=uint8, compu {phys=raw}, range phys 0..252
          signal EndOfLineControlFBD_Byte48: start 384, 8 bit, little-endian, data-type-policy=OVERRIDE, base-type=uint8, compu {phys=raw}, range phys 0..252
          signal EndOfLineControlFBD_Byte49: start 392, 8 bit, little-endian, data-type-policy=OVERRIDE, base-type=uint8, compu {phys=raw}, range phys 0..252
          signal EndOfLineControlFBD_Byte50: start 400, 8 bit, little-endian, data-type-policy=OVERRIDE, base-type=uint8, compu {phys=raw}, range phys 0..252
          signal EndOfLineControlFBD_Byte51: start 408, 8 bit, little-endian, data-type-policy=OVERRIDE, base-type=uint8, compu {phys=raw}, range phys 0..252
          signal EndOfLineControlFBD_Byte52: start 416, 8 bit, little-endian, data-type-policy=OVERRIDE, base-type=uint8, compu {phys=raw}, range phys 0..252
          signal EndOfLineControlFBD_Byte53: start 424, 8 bit, little-endian, data-type-policy=OVERRIDE, base-type=uint8, compu {phys=raw}, range phys 0..252
          signal EndOfLineControlFBD_Byte54: start 432, 8 bit, little-endian, data-type-policy=OVERRIDE, base-type=uint8, compu {phys=raw}, range phys 0..252
          signal EndOfLineControlFBD_Byte55: start 440, 8 bit, little-endian, data-type-policy=OVERRIDE, base-type=uint8, compu {phys=raw}, range phys 0..252
          signal EndOfLineControlFBD_Byte56: start 448, 8 bit, little-endian, data-type-policy=OVERRIDE, base-type=uint8, compu {phys=raw}, range phys 0..252
          signal EndOfLineControlFBD_Byte57: start 456, 8 bit, little-endian, data-type-policy=OVERRIDE, base-type=uint8, compu {phys=raw}, range phys 0..252
          signal EndOfLineControlFBD_Byte58: start 464, 8 bit, little-endian, data-type-policy=OVERRIDE, base-type=uint8, compu {phys=raw}, range phys 0..252
          signal EndOfLineControlFBD_Byte59: start 472, 8 bit, little-endian, data-type-policy=OVERRIDE, base-type=uint8, compu {phys=raw}, range phys 0..252
          signal EndOfLineControlFBD_Byte60: start 480, 8 bit, little-endian, data-type-policy=OVERRIDE, base-type=uint8, compu {phys=raw}, range phys 0..252
          signal EndOfLineControlFBD_Byte61: start 488, 8 bit, little-endian, data-type-policy=OVERRIDE, base-type=uint8, compu {phys=raw}, range phys 0..252
          signal EndOfLineControlFBD_Byte62: start 496, 8 bit, little-endian, data-type-policy=OVERRIDE, base-type=uint8, compu {phys=raw}, range phys 0..252
          signal EndOfLineControlFBD_Byte63: start 504, 8 bit, little-endian, data-type-policy=OVERRIDE, base-type=uint8, compu {phys=raw}, range phys 0..252
      frame EndOfLineStatusFBD: id 0x44D, frame-length=64, can-addressing-mode=STANDARD, can-frame-rx-behavior=CAN-FD, can-frame-tx-behavior=CAN-FD
        pdu EndOfLineStatusFBD: length=64, unused-bit-pattern=0
          signal EndOfLineStatusFBD_Byte00: start 0, 8 bit, little-endian, data-type-policy=OVERRIDE, base-type=uint8, compu {phys=raw}, range phys 0..252
          signal EndOfLineStatusFBD_Byte01: start 8, 8 bit, little-endian, data-type-policy=OVERRIDE, base-type=uint8, compu {phys=raw}, range phys 0..252
          signal EndOfLineStatusFBD_Byte02: start 16, 8 bit, little-endian, data-type-policy=OVERRIDE, base-type=uint8, compu {phys=raw}, range phys 0..252
          signal EndOfLineStatusFBD_Byte03: start 24, 8 bit, little-endian, data-type-policy=OVERRIDE, base-type=uint8, compu {phys=raw}, range phys 0..252
          signal EndOfLineStatusFBD_Byte04: start 32, 8 bit, little-endian, data-type-policy=OVERRIDE, base-type=uint8, compu {phys=raw}, range phys 0..252
          signal EndOfLineStatusFBD_Byte05: start 40, 8 bit, little-endian, data-type-policy=OVERRIDE, base-type=uint8, compu {phys=raw}, range phys 0..252
          signal EndOfLineStatusFBD_Byte06: start 48, 8 bit, little-endian, data-type-policy=OVERRIDE, base-type=uint8, compu {phys=raw}, range phys 0..252
          signal EndOfLineStatusFBD_Byte07: start 56, 8 bit, little-endian, data-type-policy=OVERRIDE, base-type=uint8, compu {phys=raw}, range phys 0..252
          signal EndOfLineStatusFBD_Byte08: start 64, 8 bit, little-endian, data-type-policy=OVERRIDE, base-type=uint8, compu {phys=raw}, range phys 0..252
          signal EndOfLineStatusFBD_Byte09: start 72, 8 bit, little-endian, data-type-policy=OVERRIDE, base-type=uint8, compu {phys=raw}, range phys 0..252
          signal EndOfLineStatusFBD_Byte10: start 80, 8 bit, little-endian, data-type-policy=OVERRIDE, base-type=uint8, compu {phys=raw}, range phys 0..252
          signal EndOfLineStatusFBD_Byte11: start 88, 8 bit, little-endian, data-type-policy=OVERRIDE, base-type=uint8, compu {phys=raw}, range phys 0..252
          signal EndOfLineStatusFBD_Byte12: start 96, 8 bit, little-endian, data-type-policy=OVERRIDE, base-type=uint8, compu {phys=raw}, range phys 0..252
          signal EndOfLineStatusFBD_Byte13: start 104, 8 bit, little-endian, data-type-policy=OVERRIDE, base-type=uint8, compu {phys=raw}, range phys 0..252
          signal EndOfLineStatusFBD_Byte14: start 112, 8 bit, little-endian, data-type-policy=OVERRIDE, base-type=uint8, compu {phys=raw}, range phys 0..252
          signal EndOfLineStatusFBD_Byte15: start 120, 8 bit, little-endian, data-type-policy=OVERRIDE, base-type=uint8, compu {phys=raw}, range phys 0..252
          signal EndOfLineStatusFBD_Byte16: start 128, 8 bit, little-endian, data-type-policy=OVERRIDE, base-type=uint8, compu {phys=raw}, range phys 0..252
          signal EndOfLineStatusFBD_Byte17: start 136, 8 bit, little-endian, data-type-policy=OVERRIDE, base-type=uint8, compu {phys=raw}, range phys 0..252
          signal EndOfLineStatusFBD_Byte18: start 144, 8 bit, little-endian, data-type-policy=OVERRIDE, base-type=uint8, compu {phys=raw}, range phys 0..252
          signal EndOfLineStatusFBD_Byte19: start 152, 8 bit, little-endian, data-type-policy=OVERRIDE, base-type=uint8, compu {phys=raw}, range phys 0..252
          signal EndOfLineStatusFBD_Byte20: start 160, 8 bit, little-endian, data-type-policy=OVERRIDE, base-type=uint8, compu {phys=raw}, range phys 0..252
          signal EndOfLineStatusFBD_Byte21: start 168, 8 bit, little-endian, data-type-policy=OVERRIDE, base-type=uint8, compu {phys=raw}, range phys 0..252
          signal EndOfLineStatusFBD_Byte22: start 176, 8 bit, little-endian, data-type-policy=OVERRIDE, base-type=uint8, compu {phys=raw}, range phys 0..252
          signal EndOfLineStatusFBD_Byte23: start 184, 8 bit, little-endian, data-type-policy=OVERRIDE, base-type=uint8, compu {phys=raw}, range phys 0..252
          signal EndOfLineStatusFBD_Byte24: start 192, 8 bit, little-endian, data-type-policy=OVERRIDE, base-type=uint8, compu {phys=raw}, range phys 0..252
          signal EndOfLineStatusFBD_Byte25: start 200, 8 bit, little-endian, data-type-policy=OVERRIDE, base-type=uint8, compu {phys=raw}, range phys 0..252
          signal EndOfLineStatusFBD_Byte26: start 208, 8 bit, little-endian, data-type-policy=OVERRIDE, base-type=uint8, compu {phys=raw}, range phys 0..252
          signal EndOfLineStatusFBD_Byte27: start 216, 8 bit, little-endian, data-type-policy=OVERRIDE, base-type=uint8, compu {phys=raw}, range phys 0..252
          signal EndOfLineStatusFBD_Byte28: start 224, 8 bit, little-endian, data-type-policy=OVERRIDE, base-type=uint8, compu {phys=raw}, range phys 0..252
          signal EndOfLineStatusFBD_Byte29: start 232, 8 bit, little-endian, data-type-policy=OVERRIDE, base-type=uint8, compu {phys=raw}, range phys 0..252
          signal EndOfLineStatusFBD_Byte30: start 240, 8 bit, little-endian, data-type-policy=OVERRIDE, base-type=uint8, compu {phys=raw}, range phys 0..252
          signal EndOfLineStatusFBD_Byte31: start 248, 8 bit, little-endian, data-type-policy=OVERRIDE, base-type=uint8, compu {phys=raw}, range phys 0..252
          signal EndOfLineStatusFBD_Byte32: start 256, 8 bit, little-endian, data-type-policy=OVERRIDE, base-type=uint8, compu {phys=raw}, range phys 0..252
          signal EndOfLineStatusFBD_Byte33: start 264, 8 bit, little-endian, data-type-policy=OVERRIDE, base-type=uint8, compu {phys=raw}, range phys 0..252
          signal EndOfLineStatusFBD_Byte34: start 272, 8 bit, little-endian, data-type-policy=OVERRIDE, base-type=uint8, compu {phys=raw}, range phys 0..252
          signal EndOfLineStatusFBD_Byte35: start 280, 8 bit, little-endian, data-type-policy=OVERRIDE, base-type=uint8, compu {phys=raw}, range phys 0..252
          signal EndOfLineStatusFBD_Byte36: start 288, 8 bit, little-endian, data-type-policy=OVERRIDE, base-type=uint8, compu {phys=raw}, range phys 0..252
          signal EndOfLineStatusFBD_Byte37: start 296, 8 bit, little-endian, data-type-policy=OVERRIDE, base-type=uint8, compu {phys=raw}, range phys 0..252
          signal EndOfLineStatusFBD_Byte38: start 304, 8 bit, little-endian, data-type-policy=OVERRIDE, base-type=uint8, compu {phys=raw}, range phys 0..252
          signal EndOfLineStatusFBD_Byte39: start 312, 8 bit, little-endian, data-type-policy=OVERRIDE, base-type=uint8, compu {phys=raw}, range phys 0..252
          signal EndOfLineStatusFBD_Byte40: start 320, 8 bit, little-endian, data-type-policy=OVERRIDE, base-type=uint8, compu {phys=raw}, range phys 0..252
          signal EndOfLineStatusFBD_Byte41: start 328, 8 bit, little-endian, data-type-policy=OVERRIDE, base-type=uint8, compu {phys=raw}, range phys 0..252
          signal EndOfLineStatusFBD_Byte42: start 336, 8 bit, little-endian, data-type-policy=OVERRIDE, base-type=uint8, compu {phys=raw}, range phys 0..252
          signal EndOfLineStatusFBD_Byte43: start 344, 8 bit, little-endian, data-type-policy=OVERRIDE, base-type=uint8, compu {phys=raw}, range phys 0..252
          signal EndOfLineStatusFBD_Byte44: start 352, 8 bit, little-endian, data-type-policy=OVERRIDE, base-type=uint8, compu {phys=raw}, range phys 0..252
          signal EndOfLineStatusFBD_Byte45: start 360, 8 bit, little-endian, data-type-policy=OVERRIDE, base-type=uint8, compu {phys=raw}, range phys 0..252
          signal EndOfLineStatusFBD_Byte46: start 368, 8 bit, little-endian, data-type-policy=OVERRIDE, base-type=uint8, compu {phys=raw}, range phys 0..252
          signal EndOfLineStatusFBD_Byte47: start 376, 8 bit, little-endian, data-type-policy=OVERRIDE, base-type=uint8, compu {phys=raw}, range phys 0..252
          signal EndOfLineStatusFBD_Byte48: start 384, 8 bit, little-endian, data-type-policy=OVERRIDE, base-type=uint8, compu {phys=raw}, range phys 0..252
          signal EndOfLineStatusFBD_Byte49: start 392, 8 bit, little-endian, data-type-policy=OVERRIDE, base-type=uint8, compu {phys=raw}, range phys 0..252
          signal EndOfLineStatusFBD_Byte50: start 400, 8 bit, little-endian, data-type-policy=OVERRIDE, base-type=uint8, compu {phys=raw}, range phys 0..252
          signal EndOfLineStatusFBD_Byte51: start 408, 8 bit, little-endian, data-type-policy=OVERRIDE, base-type=uint8, compu {phys=raw}, range phys 0..252
          signal EndOfLineStatusFBD_Byte52: start 416, 8 bit, little-endian, data-type-policy=OVERRIDE, base-type=uint8, compu {phys=raw}, range phys 0..252
          signal EndOfLineStatusFBD_Byte53: start 424, 8 bit, little-endian, data-type-policy=OVERRIDE, base-type=uint8, compu {phys=raw}, range phys 0..252
          signal EndOfLineStatusFBD_Byte54: start 432, 8 bit, little-endian, data-type-policy=OVERRIDE, base-type=uint8, compu {phys=raw}, range phys 0..252
          signal EndOfLineStatusFBD_Byte55: start 440, 8 bit, little-endian, data-type-policy=OVERRIDE, base-type=uint8, compu {phys=raw}, range phys 0..252
          signal EndOfLineStatusFBD_Byte56: start 448, 8 bit, little-endian, data-type-policy=OVERRIDE, base-type=uint8, compu {phys=raw}, range phys 0..252
          signal EndOfLineStatusFBD_Byte57: start 456, 8 bit, little-endian, data-type-policy=OVERRIDE, base-type=uint8, compu {phys=raw}, range phys 0..252
          signal EndOfLineStatusFBD_Byte58: start 464, 8 bit, little-endian, data-type-policy=OVERRIDE, base-type=uint8, compu {phys=raw}, range phys 0..252
          signal EndOfLineStatusFBD_Byte59: start 472, 8 bit, little-endian, data-type-policy=OVERRIDE, base-type=uint8, compu {phys=raw}, range phys 0..252
          signal EndOfLineStatusFBD_Byte60: start 480, 8 bit, little-endian, data-type-policy=OVERRIDE, base-type=uint8, compu {phys=raw}, range phys 0..252
          signal EndOfLineStatusFBD_Byte61: start 488, 8 bit, little-endian, data-type-policy=OVERRIDE, base-type=uint8, compu {phys=raw}, range phys 0..252
          signal EndOfLineStatusFBD_Byte62: start 496, 8 bit, little-endian, data-type-policy=OVERRIDE, base-type=uint8, compu {phys=raw}, range phys 0..252
          signal EndOfLineStatusFBD_Byte63: start 504, 8 bit, little-endian, data-type-policy=OVERRIDE, base-type=uint8, compu {phys=raw}, range phys 0..252
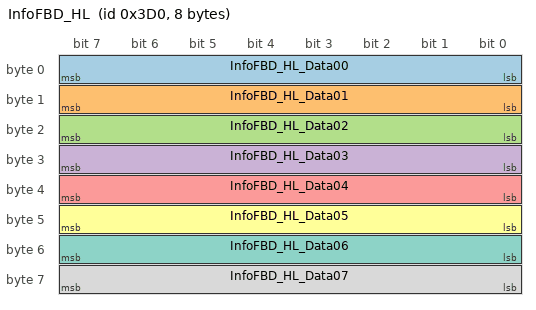
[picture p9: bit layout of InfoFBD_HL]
      frame InfoFBD_HL: id 0x3D0, frame-length=8, can-addressing-mode=STANDARD, can-frame-rx-behavior=CAN-20, can-frame-tx-behavior=CAN-20
        pdu InfoFBD_HL: length=8, unused-bit-pattern=0
          signal InfoFBD_HL_Data00: start 0, 8 bit, little-endian, data-type-policy=OVERRIDE, base-type=uint8, compu {phys=raw}, range phys 0..252
          signal InfoFBD_HL_Data01: start 8, 8 bit, little-endian, data-type-policy=OVERRIDE, base-type=uint8, compu {phys=raw}, range phys 0..252
          signal InfoFBD_HL_Data02: start 16, 8 bit, little-endian, data-type-policy=OVERRIDE, base-type=uint8, compu {phys=raw}, range phys 0..252
          signal InfoFBD_HL_Data03: start 24, 8 bit, little-endian, data-type-policy=OVERRIDE, base-type=uint8, compu {phys=raw}, range phys 0..252
          signal InfoFBD_HL_Data04: start 32, 8 bit, little-endian, data-type-policy=OVERRIDE, base-type=uint8, compu {phys=raw}, range phys 0..252
          signal InfoFBD_HL_Data05: start 40, 8 bit, little-endian, data-type-policy=OVERRIDE, base-type=uint8, compu {phys=raw}, range phys 0..252
          signal InfoFBD_HL_Data06: start 48, 8 bit, little-endian, data-type-policy=OVERRIDE, base-type=uint8, compu {phys=raw}, range phys 0..252
          signal InfoFBD_HL_Data07: start 56, 8 bit, little-endian, data-type-policy=OVERRIDE, base-type=uint8, compu {phys=raw}, range phys 0..252
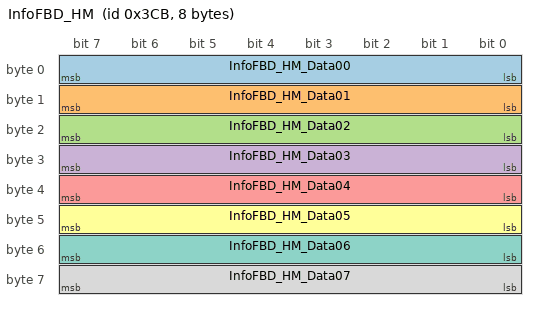
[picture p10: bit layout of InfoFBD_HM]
      frame InfoFBD_HM: id 0x3CB, frame-length=8, can-addressing-mode=STANDARD, can-frame-rx-behavior=CAN-20, can-frame-tx-behavior=CAN-20
        pdu InfoFBD_HM: length=8, unused-bit-pattern=0
          signal InfoFBD_HM_Data00: start 0, 8 bit, little-endian, data-type-policy=OVERRIDE, base-type=uint8, compu {phys=raw}, range phys 0..252
          signal InfoFBD_HM_Data01: start 8, 8 bit, little-endian, data-type-policy=OVERRIDE, base-type=uint8, compu {phys=raw}, range phys 0..252
          signal InfoFBD_HM_Data02: start 16, 8 bit, little-endian, data-type-policy=OVERRIDE, base-type=uint8, compu {phys=raw}, range phys 0..252
          signal InfoFBD_HM_Data03: start 24, 8 bit, little-endian, data-type-policy=OVERRIDE, base-type=uint8, compu {phys=raw}, range phys 0..252
          signal InfoFBD_HM_Data04: start 32, 8 bit, little-endian, data-type-policy=OVERRIDE, base-type=uint8, compu {phys=raw}, range phys 0..252
          signal InfoFBD_HM_Data05: start 40, 8 bit, little-endian, data-type-policy=OVERRIDE, base-type=uint8, compu {phys=raw}, range phys 0..252
          signal InfoFBD_HM_Data06: start 48, 8 bit, little-endian, data-type-policy=OVERRIDE, base-type=uint8, compu {phys=raw}, range phys 0..252
          signal InfoFBD_HM_Data07: start 56, 8 bit, little-endian, data-type-policy=OVERRIDE, base-type=uint8, compu {phys=raw}, range phys 0..252
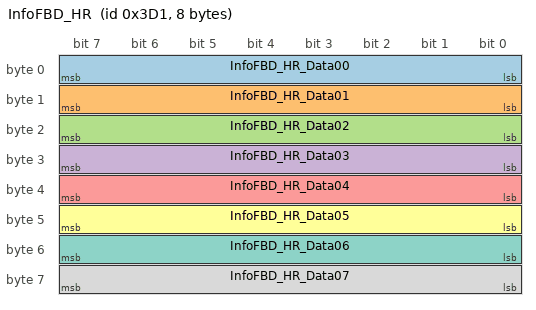
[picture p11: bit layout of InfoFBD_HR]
      frame InfoFBD_HR: id 0x3D1, frame-length=8, can-addressing-mode=STANDARD, can-frame-rx-behavior=CAN-20, can-frame-tx-behavior=CAN-20
        pdu InfoFBD_HR: length=8, unused-bit-pattern=0
          signal InfoFBD_HR_Data00: start 0, 8 bit, little-endian, data-type-policy=OVERRIDE, base-type=uint8, compu {phys=raw}, range phys 0..252
          signal InfoFBD_HR_Data01: start 8, 8 bit, little-endian, data-type-policy=OVERRIDE, base-type=uint8, compu {phys=raw}, range phys 0..252
          signal InfoFBD_HR_Data02: start 16, 8 bit, little-endian, data-type-policy=OVERRIDE, base-type=uint8, compu {phys=raw}, range phys 0..252
          signal InfoFBD_HR_Data03: start 24, 8 bit, little-endian, data-type-policy=OVERRIDE, base-type=uint8, compu {phys=raw}, range phys 0..252
          signal InfoFBD_HR_Data04: start 32, 8 bit, little-endian, data-type-policy=OVERRIDE, base-type=uint8, compu {phys=raw}, range phys 0..252
          signal InfoFBD_HR_Data05: start 40, 8 bit, little-endian, data-type-policy=OVERRIDE, base-type=uint8, compu {phys=raw}, range phys 0..252
          signal InfoFBD_HR_Data06: start 48, 8 bit, little-endian, data-type-policy=OVERRIDE, base-type=uint8, compu {phys=raw}, range phys 0..252
          signal InfoFBD_HR_Data07: start 56, 8 bit, little-endian, data-type-policy=OVERRIDE, base-type=uint8, compu {phys=raw}, range phys 0..252
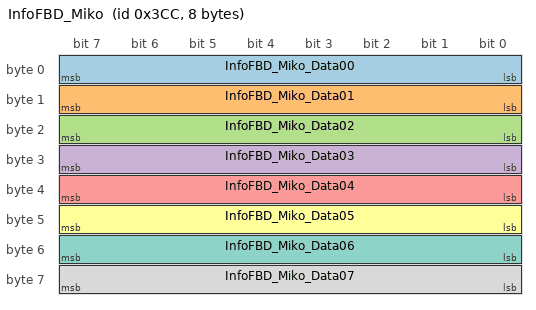
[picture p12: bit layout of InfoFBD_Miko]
      frame InfoFBD_Miko: id 0x3CC, frame-length=8, can-addressing-mode=STANDARD, can-frame-rx-behavior=CAN-20, can-frame-tx-behavior=CAN-20
        pdu InfoFBD_Miko: length=8, unused-bit-pattern=0
          signal InfoFBD_Miko_Data00: start 0, 8 bit, little-endian, data-type-policy=OVERRIDE, base-type=uint8, compu {phys=raw}, range phys 0..252
          signal InfoFBD_Miko_Data01: start 8, 8 bit, little-endian, data-type-policy=OVERRIDE, base-type=uint8, compu {phys=raw}, range phys 0..252
          signal InfoFBD_Miko_Data02: start 16, 8 bit, little-endian, data-type-policy=OVERRIDE, base-type=uint8, compu {phys=raw}, range phys 0..252
          signal InfoFBD_Miko_Data03: start 24, 8 bit, little-endian, data-type-policy=OVERRIDE, base-type=uint8, compu {phys=raw}, range phys 0..252
          signal InfoFBD_Miko_Data04: start 32, 8 bit, little-endian, data-type-policy=OVERRIDE, base-type=uint8, compu {phys=raw}, range phys 0..252
          signal InfoFBD_Miko_Data05: start 40, 8 bit, little-endian, data-type-policy=OVERRIDE, base-type=uint8, compu {phys=raw}, range phys 0..252
          signal InfoFBD_Miko_Data06: start 48, 8 bit, little-endian, data-type-policy=OVERRIDE, base-type=uint8, compu {phys=raw}, range phys 0..252
          signal InfoFBD_Miko_Data07: start 56, 8 bit, little-endian, data-type-policy=OVERRIDE, base-type=uint8, compu {phys=raw}, range phys 0..252
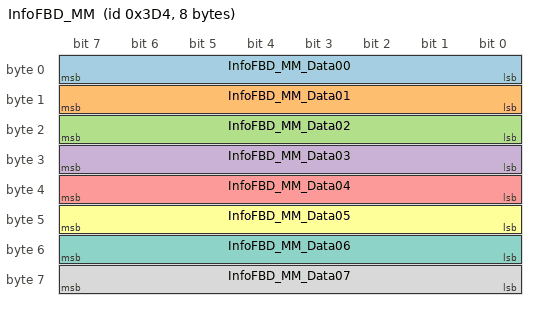
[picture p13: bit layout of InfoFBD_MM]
      frame InfoFBD_MM: id 0x3D4, frame-length=8, can-addressing-mode=STANDARD, can-frame-rx-behavior=CAN-20, can-frame-tx-behavior=CAN-20
        pdu InfoFBD_MM: length=8, unused-bit-pattern=0
          signal InfoFBD_MM_Data00: start 0, 8 bit, little-endian, data-type-policy=OVERRIDE, base-type=uint8, compu {phys=raw}, range phys 0..252
          signal InfoFBD_MM_Data01: start 8, 8 bit, little-endian, data-type-policy=OVERRIDE, base-type=uint8, compu {phys=raw}, range phys 0..252
          signal InfoFBD_MM_Data02: start 16, 8 bit, little-endian, data-type-policy=OVERRIDE, base-type=uint8, compu {phys=raw}, range phys 0..252
          signal InfoFBD_MM_Data03: start 24, 8 bit, little-endian, data-type-policy=OVERRIDE, base-type=uint8, compu {phys=raw}, range phys 0..252
          signal InfoFBD_MM_Data04: start 32, 8 bit, little-endian, data-type-policy=OVERRIDE, base-type=uint8, compu {phys=raw}, range phys 0..252
          signal InfoFBD_MM_Data05: start 40, 8 bit, little-endian, data-type-policy=OVERRIDE, base-type=uint8, compu {phys=raw}, range phys 0..252
          signal InfoFBD_MM_Data06: start 48, 8 bit, little-endian, data-type-policy=OVERRIDE, base-type=uint8, compu {phys=raw}, range phys 0..252
          signal InfoFBD_MM_Data07: start 56, 8 bit, little-endian, data-type-policy=OVERRIDE, base-type=uint8, compu {phys=raw}, range phys 0..252
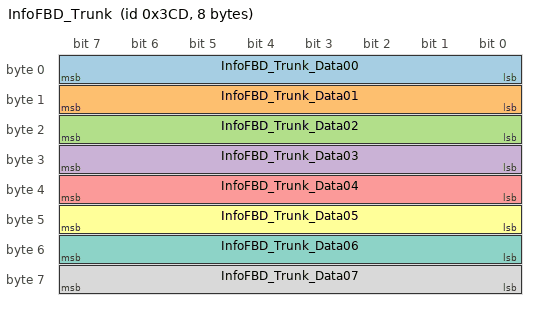
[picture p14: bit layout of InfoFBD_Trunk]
      frame InfoFBD_Trunk: id 0x3CD, frame-length=8, can-addressing-mode=STANDARD, can-frame-rx-behavior=CAN-20, can-frame-tx-behavior=CAN-20
        pdu InfoFBD_Trunk: length=8, unused-bit-pattern=0
          signal InfoFBD_Trunk_Data00: start 0, 8 bit, little-endian, data-type-policy=OVERRIDE, base-type=uint8, compu {phys=raw}, range phys 0..252
          signal InfoFBD_Trunk_Data01: start 8, 8 bit, little-endian, data-type-policy=OVERRIDE, base-type=uint8, compu {phys=raw}, range phys 0..252
          signal InfoFBD_Trunk_Data02: start 16, 8 bit, little-endian, data-type-policy=OVERRIDE, base-type=uint8, compu {phys=raw}, range phys 0..252
          signal InfoFBD_Trunk_Data03: start 24, 8 bit, little-endian, data-type-policy=OVERRIDE, base-type=uint8, compu {phys=raw}, range phys 0..252
          signal InfoFBD_Trunk_Data04: start 32, 8 bit, little-endian, data-type-policy=OVERRIDE, base-type=uint8, compu {phys=raw}, range phys 0..252
          signal InfoFBD_Trunk_Data05: start 40, 8 bit, little-endian, data-type-policy=OVERRIDE, base-type=uint8, compu {phys=raw}, range phys 0..252
          signal InfoFBD_Trunk_Data06: start 48, 8 bit, little-endian, data-type-policy=OVERRIDE, base-type=uint8, compu {phys=raw}, range phys 0..252
          signal InfoFBD_Trunk_Data07: start 56, 8 bit, little-endian, data-type-policy=OVERRIDE, base-type=uint8, compu {phys=raw}, range phys 0..252
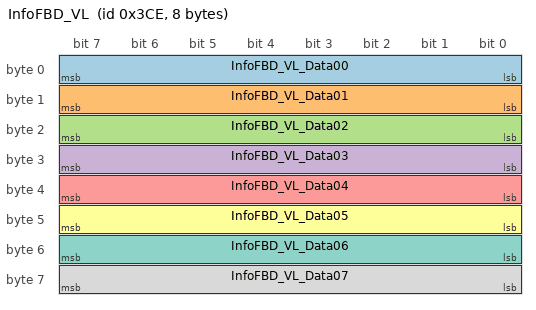
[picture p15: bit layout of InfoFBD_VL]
      frame InfoFBD_VL: id 0x3CE, frame-length=8, can-addressing-mode=STANDARD, can-frame-rx-behavior=CAN-20, can-frame-tx-behavior=CAN-20
        pdu InfoFBD_VL: length=8, unused-bit-pattern=0
          signal InfoFBD_VL_Data00: start 0, 8 bit, little-endian, data-type-policy=OVERRIDE, base-type=uint8, compu {phys=raw}, range phys 0..252
          signal InfoFBD_VL_Data01: start 8, 8 bit, little-endian, data-type-policy=OVERRIDE, base-type=uint8, compu {phys=raw}, range phys 0..252
          signal InfoFBD_VL_Data02: start 16, 8 bit, little-endian, data-type-policy=OVERRIDE, base-type=uint8, compu {phys=raw}, range phys 0..252
          signal InfoFBD_VL_Data03: start 24, 8 bit, little-endian, data-type-policy=OVERRIDE, base-type=uint8, compu {phys=raw}, range phys 0..252
          signal InfoFBD_VL_Data04: start 32, 8 bit, little-endian, data-type-policy=OVERRIDE, base-type=uint8, compu {phys=raw}, range phys 0..252
          signal InfoFBD_VL_Data05: start 40, 8 bit, little-endian, data-type-policy=OVERRIDE, base-type=uint8, compu {phys=raw}, range phys 0..252
          signal InfoFBD_VL_Data06: start 48, 8 bit, little-endian, data-type-policy=OVERRIDE, base-type=uint8, compu {phys=raw}, range phys 0..252
          signal InfoFBD_VL_Data07: start 56, 8 bit, little-endian, data-type-policy=OVERRIDE, base-type=uint8, compu {phys=raw}, range phys 0..252
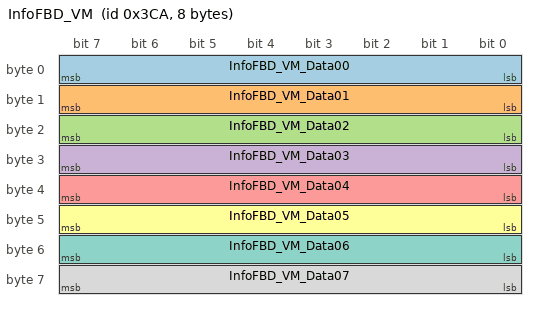
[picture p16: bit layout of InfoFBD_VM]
      frame InfoFBD_VM: id 0x3CA, frame-length=8, can-addressing-mode=STANDARD, can-frame-rx-behavior=CAN-20, can-frame-tx-behavior=CAN-20
        pdu InfoFBD_VM: length=8, unused-bit-pattern=0
          signal InfoFBD_VM_Data00: start 0, 8 bit, little-endian, data-type-policy=OVERRIDE, base-type=uint8, compu {phys=raw}, range phys 0..252
          signal InfoFBD_VM_Data01: start 8, 8 bit, little-endian, data-type-policy=OVERRIDE, base-type=uint8, compu {phys=raw}, range phys 0..252
          signal InfoFBD_VM_Data02: start 16, 8 bit, little-endian, data-type-policy=OVERRIDE, base-type=uint8, compu {phys=raw}, range phys 0..252
          signal InfoFBD_VM_Data03: start 24, 8 bit, little-endian, data-type-policy=OVERRIDE, base-type=uint8, compu {phys=raw}, range phys 0..252
          signal InfoFBD_VM_Data04: start 32, 8 bit, little-endian, data-type-policy=OVERRIDE, base-type=uint8, compu {phys=raw}, range phys 0..252
          signal InfoFBD_VM_Data05: start 40, 8 bit, little-endian, data-type-policy=OVERRIDE, base-type=uint8, compu {phys=raw}, range phys 0..252
          signal InfoFBD_VM_Data06: start 48, 8 bit, little-endian, data-type-policy=OVERRIDE, base-type=uint8, compu {phys=raw}, range phys 0..252
          signal InfoFBD_VM_Data07: start 56, 8 bit, little-endian, data-type-policy=OVERRIDE, base-type=uint8, compu {phys=raw}, range phys 0..252
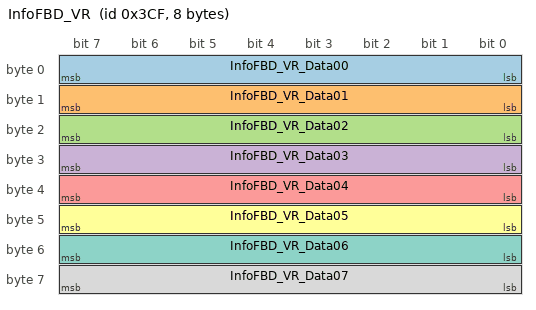
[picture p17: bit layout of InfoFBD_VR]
      frame InfoFBD_VR: id 0x3CF, frame-length=8, can-addressing-mode=STANDARD, can-frame-rx-behavior=CAN-20, can-frame-tx-behavior=CAN-20
        pdu InfoFBD_VR: length=8, unused-bit-pattern=0
          signal InfoFBD_VR_Data00: start 0, 8 bit, little-endian, data-type-policy=OVERRIDE, base-type=uint8, compu {phys=raw}, range phys 0..252
          signal InfoFBD_VR_Data01: start 8, 8 bit, little-endian, data-type-policy=OVERRIDE, base-type=uint8, compu {phys=raw}, range phys 0..252
          signal InfoFBD_VR_Data02: start 16, 8 bit, little-endian, data-type-policy=OVERRIDE, base-type=uint8, compu {phys=raw}, range phys 0..252
          signal InfoFBD_VR_Data03: start 24, 8 bit, little-endian, data-type-policy=OVERRIDE, base-type=uint8, compu {phys=raw}, range phys 0..252
          signal InfoFBD_VR_Data04: start 32, 8 bit, little-endian, data-type-policy=OVERRIDE, base-type=uint8, compu {phys=raw}, range phys 0..252
          signal InfoFBD_VR_Data05: start 40, 8 bit, little-endian, data-type-policy=OVERRIDE, base-type=uint8, compu {phys=raw}, range phys 0..252
          signal InfoFBD_VR_Data06: start 48, 8 bit, little-endian, data-type-policy=OVERRIDE, base-type=uint8, compu {phys=raw}, range phys 0..252
          signal InfoFBD_VR_Data07: start 56, 8 bit, little-endian, data-type-policy=OVERRIDE, base-type=uint8, compu {phys=raw}, range phys 0..252
      frame LocalizationInitFBD_HL: id 0x22C, frame-length=48, can-addressing-mode=STANDARD, can-frame-rx-behavior=CAN-FD, can-frame-tx-behavior=CAN-FD
        pdu LocalizationInitFBD_HL: length=48, unused-bit-pattern=0
          signal LocalizationInitFBD_HL_IRKListIndex: start 0, 8 bit, little-endian, data-type-policy=OVERRIDE, base-type=uint8, compu {phys=raw}, range phys 0..252
          signal LocalizationInitFBD_HL_ZoneEntry: start 8, 8 bit, little-endian, data-type-policy=OVERRIDE, base-type=uint8, compu {phys=raw}, range phys 0..252
          signal LocalizationInitFBD_HL_RangingBlockIndex_0: start 16, 16 bit, little-endian, data-type-policy=OVERRIDE, base-type=uint16, compu {phys=raw}, range phys 0..65532
          signal LocalizationInitFBD_HL_TimeOfFlight_0: start 32, 16 bit, little-endian, data-type-policy=OVERRIDE, base-type=uint16, compu {phys=raw*15.65; unit ps}, range phys 0..1000000
          signal LocalizationInitFBD_HL_RSSI_0: start 48, 8 bit, little-endian, data-type-policy=OVERRIDE, base-type=uint8, compu {phys=raw-90; unit °}, range phys -90..90
          signal LocalizationInitFBD_HL_RangingBlockIndex_1: start 56, 16 bit, little-endian, data-type-policy=OVERRIDE, base-type=uint16, compu {phys=raw}, range phys 0..65532
          signal LocalizationInitFBD_HL_TimeOfFlight_1: start 72, 16 bit, little-endian, data-type-policy=OVERRIDE, base-type=uint16, compu {phys=raw*15.65; unit ps}, range phys 0..1000000
          signal LocalizationInitFBD_HL_RSSI_1: start 88, 8 bit, little-endian, data-type-policy=OVERRIDE, base-type=uint8, compu {phys=raw-90; unit °}, range phys -90..90
          signal LocalizationInitFBD_HL_RangingBlockIndex_2: start 96, 16 bit, little-endian, data-type-policy=OVERRIDE, base-type=uint16, compu {phys=raw}, range phys 0..65532
          signal LocalizationInitFBD_HL_TimeOfFlight_2: start 112, 16 bit, little-endian, data-type-policy=OVERRIDE, base-type=uint16, compu {phys=raw*15.65; unit ps}, range phys 0..1000000
          signal LocalizationInitFBD_HL_RSSI_2: start 128, 8 bit, little-endian, data-type-policy=OVERRIDE, base-type=uint8, compu {phys=raw-90; unit °}, range phys -90..90
          signal LocalizationInitFBD_HL_RangingBlockIndex_3: start 136, 16 bit, little-endian, data-type-policy=OVERRIDE, base-type=uint16, compu {phys=raw}, range phys 0..65532
          signal LocalizationInitFBD_HL_TimeOfFlight_3: start 152, 16 bit, little-endian, data-type-policy=OVERRIDE, base-type=uint16, compu {phys=raw*15.65; unit ps}, range phys 0..1000000
          signal LocalizationInitFBD_HL_RSSI_3: start 168, 8 bit, little-endian, data-type-policy=OVERRIDE, base-type=uint8, compu {phys=raw-90; unit °}, range phys -90..90
          signal LocalizationInitFBD_HL_RangingBlockIndex_4: start 176, 16 bit, little-endian, data-type-policy=OVERRIDE, base-type=uint16, compu {phys=raw}, range phys 0..65532
          signal LocalizationInitFBD_HL_TimeOfFlight_4: start 192, 16 bit, little-endian, data-type-policy=OVERRIDE, base-type=uint16, compu {phys=raw*15.65; unit ps}, range phys 0..1000000
          signal LocalizationInitFBD_HL_RSSI_4: start 208, 8 bit, little-endian, data-type-policy=OVERRIDE, base-type=uint8, compu {phys=raw-90; unit °}, range phys -90..90
          signal LocalizationInitFBD_HL_Sign_00: start 216, 8 bit, little-endian, data-type-policy=OVERRIDE, base-type=uint8, compu {phys=raw}, range phys 0..255
          signal LocalizationInitFBD_HL_Sign_01: start 224, 8 bit, little-endian, data-type-policy=OVERRIDE, base-type=uint8, compu {phys=raw}, range phys 0..255
          signal LocalizationInitFBD_HL_Sign_02: start 232, 8 bit, little-endian, data-type-policy=OVERRIDE, base-type=uint8, compu {phys=raw}, range phys 0..255
          signal LocalizationInitFBD_HL_Sign_03: start 240, 8 bit, little-endian, data-type-policy=OVERRIDE, base-type=uint8, compu {phys=raw}, range phys 0..255
          signal LocalizationInitFBD_HL_Sign_04: start 248, 8 bit, little-endian, data-type-policy=OVERRIDE, base-type=uint8, compu {phys=raw}, range phys 0..255
          signal LocalizationInitFBD_HL_Sign_05: start 256, 8 bit, little-endian, data-type-policy=OVERRIDE, base-type=uint8, compu {phys=raw}, range phys 0..255
          signal LocalizationInitFBD_HL_Sign_06: start 264, 8 bit, little-endian, data-type-policy=OVERRIDE, base-type=uint8, compu {phys=raw}, range phys 0..255
          signal LocalizationInitFBD_HL_Sign_07: start 272, 8 bit, little-endian, data-type-policy=OVERRIDE, base-type=uint8, compu {phys=raw}, range phys 0..255
          signal LocalizationInitFBD_HL_Sign_08: start 280, 8 bit, little-endian, data-type-policy=OVERRIDE, base-type=uint8, compu {phys=raw}, range phys 0..255
          signal LocalizationInitFBD_HL_Sign_09: start 288, 8 bit, little-endian, data-type-policy=OVERRIDE, base-type=uint8, compu {phys=raw}, range phys 0..255
          signal LocalizationInitFBD_HL_Sign_10: start 296, 8 bit, little-endian, data-type-policy=OVERRIDE, base-type=uint8, compu {phys=raw}, range phys 0..255
          signal LocalizationInitFBD_HL_Sign_11: start 304, 8 bit, little-endian, data-type-policy=OVERRIDE, base-type=uint8, compu {phys=raw}, range phys 0..255
          signal LocalizationInitFBD_HL_Sign_12: start 312, 8 bit, little-endian, data-type-policy=OVERRIDE, base-type=uint8, compu {phys=raw}, range phys 0..255
          signal LocalizationInitFBD_HL_Sign_13: start 320, 8 bit, little-endian, data-type-policy=OVERRIDE, base-type=uint8, compu {phys=raw}, range phys 0..255
          signal LocalizationInitFBD_HL_Sign_14: start 328, 8 bit, little-endian, data-type-policy=OVERRIDE, base-type=uint8, compu {phys=raw}, range phys 0..255
          signal LocalizationInitFBD_HL_Sign_15: start 336, 8 bit, little-endian, data-type-policy=OVERRIDE, base-type=uint8, compu {phys=raw}, range phys 0..255
          signal LocalizationInitFBD_HL_RangingRoundIndex_0: start 344, 8 bit, little-endian, data-type-policy=OVERRIDE, base-type=uint8, compu {phys=raw}, range phys 0..255
          signal LocalizationInitFBD_HL_RangingRoundIndex_1: start 352, 8 bit, little-endian, data-type-policy=OVERRIDE, base-type=uint8, compu {phys=raw}, range phys 0..255
          signal LocalizationInitFBD_HL_RangingRoundIndex_2: start 360, 8 bit, little-endian, data-type-policy=OVERRIDE, base-type=uint8, compu {phys=raw}, range phys 0..255
          signal LocalizationInitFBD_HL_RangingRoundIndex_3: start 368, 8 bit, little-endian, data-type-policy=OVERRIDE, base-type=uint8, compu {phys=raw}, range phys 0..255
          signal LocalizationInitFBD_HL_RangingRoundIndex_4: start 376, 8 bit, little-endian, data-type-policy=OVERRIDE, base-type=uint8, compu {phys=raw}, range phys 0..255
      frame LocalizationInitFBD_HM: id 0x227, frame-length=48, can-addressing-mode=STANDARD, can-frame-rx-behavior=CAN-FD, can-frame-tx-behavior=CAN-FD
        pdu LocalizationInitFBD_HM: length=48, unused-bit-pattern=0
          signal LocalizationInitFBD_HM_IRKListIndex: start 0, 8 bit, little-endian, data-type-policy=OVERRIDE, base-type=uint8, compu {phys=raw}, range phys 0..252
          signal LocalizationInitFBD_HM_ZoneEntry: start 8, 8 bit, little-endian, data-type-policy=OVERRIDE, base-type=uint8, compu {phys=raw}, range phys 0..252
          signal LocalizationInitFBD_HM_RangingBlockIndex_0: start 16, 16 bit, little-endian, data-type-policy=OVERRIDE, base-type=uint16, compu {phys=raw}, range phys 0..65532
          signal LocalizationInitFBD_HM_TimeOfFlight_0: start 32, 16 bit, little-endian, data-type-policy=OVERRIDE, base-type=uint16, compu {phys=raw*15.65; unit ps}, range phys 0..1000000
          signal LocalizationInitFBD_HM_RSSI_0: start 48, 8 bit, little-endian, data-type-policy=OVERRIDE, base-type=uint8, compu {phys=raw-90; unit °}, range phys -90..90
          signal LocalizationInitFBD_HM_RangingBlockIndex_1: start 56, 16 bit, little-endian, data-type-policy=OVERRIDE, base-type=uint16, compu {phys=raw}, range phys 0..65532
          signal LocalizationInitFBD_HM_TimeOfFlight_1: start 72, 16 bit, little-endian, data-type-policy=OVERRIDE, base-type=uint16, compu {phys=raw*15.65; unit ps}, range phys 0..1000000
          signal LocalizationInitFBD_HM_RSSI_1: start 88, 8 bit, little-endian, data-type-policy=OVERRIDE, base-type=uint8, compu {phys=raw-90; unit °}, range phys -90..90
          signal LocalizationInitFBD_HM_RangingBlockIndex_2: start 96, 16 bit, little-endian, data-type-policy=OVERRIDE, base-type=uint16, compu {phys=raw}, range phys 0..65532
          signal LocalizationInitFBD_HM_TimeOfFlight_2: start 112, 16 bit, little-endian, data-type-policy=OVERRIDE, base-type=uint16, compu {phys=raw*15.65; unit ps}, range phys 0..1000000
          signal LocalizationInitFBD_HM_RSSI_2: start 128, 8 bit, little-endian, data-type-policy=OVERRIDE, base-type=uint8, compu {phys=raw-90; unit °}, range phys -90..90
          signal LocalizationInitFBD_HM_RangingBlockIndex_3: start 136, 16 bit, little-endian, data-type-policy=OVERRIDE, base-type=uint16, compu {phys=raw}, range phys 0..65532
          signal LocalizationInitFBD_HM_TimeOfFlight_3: start 152, 16 bit, little-endian, data-type-policy=OVERRIDE, base-type=uint16, compu {phys=raw*15.65; unit ps}, range phys 0..1000000
          signal LocalizationInitFBD_HM_RSSI_3: start 168, 8 bit, little-endian, data-type-policy=OVERRIDE, base-type=uint8, compu {phys=raw-90; unit °}, range phys -90..90
          signal LocalizationInitFBD_HM_RangingBlockIndex_4: start 176, 16 bit, little-endian, data-type-policy=OVERRIDE, base-type=uint16, compu {phys=raw}, range phys 0..65532
          signal LocalizationInitFBD_HM_TimeOfFlight_4: start 192, 16 bit, little-endian, data-type-policy=OVERRIDE, base-type=uint16, compu {phys=raw*15.65; unit ps}, range phys 0..1000000
          signal LocalizationInitFBD_HM_RSSI_4: start 208, 8 bit, little-endian, data-type-policy=OVERRIDE, base-type=uint8, compu {phys=raw-90; unit °}, range phys -90..90
          signal LocalizationInitFBD_HM_Sign_00: start 216, 8 bit, little-endian, data-type-policy=OVERRIDE, base-type=uint8, compu {phys=raw}, range phys 0..255
          signal LocalizationInitFBD_HM_Sign_01: start 224, 8 bit, little-endian, data-type-policy=OVERRIDE, base-type=uint8, compu {phys=raw}, range phys 0..255
          signal LocalizationInitFBD_HM_Sign_02: start 232, 8 bit, little-endian, data-type-policy=OVERRIDE, base-type=uint8, compu {phys=raw}, range phys 0..255
          signal LocalizationInitFBD_HM_Sign_03: start 240, 8 bit, little-endian, data-type-policy=OVERRIDE, base-type=uint8, compu {phys=raw}, range phys 0..255
          signal LocalizationInitFBD_HM_Sign_04: start 248, 8 bit, little-endian, data-type-policy=OVERRIDE, base-type=uint8, compu {phys=raw}, range phys 0..255
          signal LocalizationInitFBD_HM_Sign_05: start 256, 8 bit, little-endian, data-type-policy=OVERRIDE, base-type=uint8, compu {phys=raw}, range phys 0..255
          signal LocalizationInitFBD_HM_Sign_06: start 264, 8 bit, little-endian, data-type-policy=OVERRIDE, base-type=uint8, compu {phys=raw}, range phys 0..255
          signal LocalizationInitFBD_HM_Sign_07: start 272, 8 bit, little-endian, data-type-policy=OVERRIDE, base-type=uint8, compu {phys=raw}, range phys 0..255
          signal LocalizationInitFBD_HM_Sign_08: start 280, 8 bit, little-endian, data-type-policy=OVERRIDE, base-type=uint8, compu {phys=raw}, range phys 0..255
          signal LocalizationInitFBD_HM_Sign_09: start 288, 8 bit, little-endian, data-type-policy=OVERRIDE, base-type=uint8, compu {phys=raw}, range phys 0..255
          signal LocalizationInitFBD_HM_Sign_10: start 296, 8 bit, little-endian, data-type-policy=OVERRIDE, base-type=uint8, compu {phys=raw}, range phys 0..255
          signal LocalizationInitFBD_HM_Sign_11: start 304, 8 bit, little-endian, data-type-policy=OVERRIDE, base-type=uint8, compu {phys=raw}, range phys 0..255
          signal LocalizationInitFBD_HM_Sign_12: start 312, 8 bit, little-endian, data-type-policy=OVERRIDE, base-type=uint8, compu {phys=raw}, range phys 0..255
          signal LocalizationInitFBD_HM_Sign_13: start 320, 8 bit, little-endian, data-type-policy=OVERRIDE, base-type=uint8, compu {phys=raw}, range phys 0..255
          signal LocalizationInitFBD_HM_Sign_14: start 328, 8 bit, little-endian, data-type-policy=OVERRIDE, base-type=uint8, compu {phys=raw}, range phys 0..255
          signal LocalizationInitFBD_HM_Sign_15: start 336, 8 bit, little-endian, data-type-policy=OVERRIDE, base-type=uint8, compu {phys=raw}, range phys 0..255
          signal LocalizationInitFBD_HM_RangingRoundIndex_0: start 344, 8 bit, little-endian, data-type-policy=OVERRIDE, base-type=uint8, compu {phys=raw}, range phys 0..255
          signal LocalizationInitFBD_HM_RangingRoundIndex_1: start 352, 8 bit, little-endian, data-type-policy=OVERRIDE, base-type=uint8, compu {phys=raw}, range phys 0..255
          signal LocalizationInitFBD_HM_RangingRoundIndex_2: start 360, 8 bit, little-endian, data-type-policy=OVERRIDE, base-type=uint8, compu {phys=raw}, range phys 0..255
          signal LocalizationInitFBD_HM_RangingRoundIndex_3: start 368, 8 bit, little-endian, data-type-policy=OVERRIDE, base-type=uint8, compu {phys=raw}, range phys 0..255
          signal LocalizationInitFBD_HM_RangingRoundIndex_4: start 376, 8 bit, little-endian, data-type-policy=OVERRIDE, base-type=uint8, compu {phys=raw}, range phys 0..255
      frame LocalizationInitFBD_HR: id 0x22D, frame-length=48, can-addressing-mode=STANDARD, can-frame-rx-behavior=CAN-FD, can-frame-tx-behavior=CAN-FD
        pdu LocalizationInitFBD_HR: length=48, unused-bit-pattern=0
          signal LocalizationInitFBD_HR_IRKListIndex: start 0, 8 bit, little-endian, data-type-policy=OVERRIDE, base-type=uint8, compu {phys=raw}, range phys 0..252
          signal LocalizationInitFBD_HR_ZoneEntry: start 8, 8 bit, little-endian, data-type-policy=OVERRIDE, base-type=uint8, compu {phys=raw}, range phys 0..252
          signal LocalizationInitFBD_HR_RangingBlockIndex_0: start 16, 16 bit, little-endian, data-type-policy=OVERRIDE, base-type=uint16, compu {phys=raw}, range phys 0..65532
          signal LocalizationInitFBD_HR_TimeOfFlight_0: start 32, 16 bit, little-endian, data-type-policy=OVERRIDE, base-type=uint16, compu {phys=raw*15.65; unit ps}, range phys 0..1000000
          signal LocalizationInitFBD_HR_RSSI_0: start 48, 8 bit, little-endian, data-type-policy=OVERRIDE, base-type=uint8, compu {phys=raw-90; unit °}, range phys -90..90
          signal LocalizationInitFBD_HR_RangingBlockIndex_1: start 56, 16 bit, little-endian, data-type-policy=OVERRIDE, base-type=uint16, compu {phys=raw}, range phys 0..65532
          signal LocalizationInitFBD_HR_TimeOfFlight_1: start 72, 16 bit, little-endian, data-type-policy=OVERRIDE, base-type=uint16, compu {phys=raw*15.65; unit ps}, range phys 0..1000000
          signal LocalizationInitFBD_HR_RSSI_1: start 88, 8 bit, little-endian, data-type-policy=OVERRIDE, base-type=uint8, compu {phys=raw-90; unit °}, range phys -90..90
          signal LocalizationInitFBD_HR_RangingBlockIndex_2: start 96, 16 bit, little-endian, data-type-policy=OVERRIDE, base-type=uint16, compu {phys=raw}, range phys 0..65532
          signal LocalizationInitFBD_HR_TimeOfFlight_2: start 112, 16 bit, little-endian, data-type-policy=OVERRIDE, base-type=uint16, compu {phys=raw*15.65; unit ps}, range phys 0..1000000
          signal LocalizationInitFBD_HR_RSSI_2: start 128, 8 bit, little-endian, data-type-policy=OVERRIDE, base-type=uint8, compu {phys=raw-90; unit °}, range phys -90..90
          signal LocalizationInitFBD_HR_RangingBlockIndex_3: start 136, 16 bit, little-endian, data-type-policy=OVERRIDE, base-type=uint16, compu {phys=raw}, range phys 0..65532
          signal LocalizationInitFBD_HR_TimeOfFlight_3: start 152, 16 bit, little-endian, data-type-policy=OVERRIDE, base-type=uint16, compu {phys=raw*15.65; unit ps}, range phys 0..1000000
          signal LocalizationInitFBD_HR_RSSI_3: start 168, 8 bit, little-endian, data-type-policy=OVERRIDE, base-type=uint8, compu {phys=raw-90; unit °}, range phys -90..90
          signal LocalizationInitFBD_HR_RangingBlockIndex_4: start 176, 16 bit, little-endian, data-type-policy=OVERRIDE, base-type=uint16, compu {phys=raw}, range phys 0..65532
          signal LocalizationInitFBD_HR_TimeOfFlight_4: start 192, 16 bit, little-endian, data-type-policy=OVERRIDE, base-type=uint16, compu {phys=raw*15.65; unit ps}, range phys 0..1000000
          signal LocalizationInitFBD_HR_RSSI_4: start 208, 8 bit, little-endian, data-type-policy=OVERRIDE, base-type=uint8, compu {phys=raw-90; unit °}, range phys -90..90
          signal LocalizationInitFBD_HR_Sign_00: start 216, 8 bit, little-endian, data-type-policy=OVERRIDE, base-type=uint8, compu {phys=raw}, range phys 0..255
          signal LocalizationInitFBD_HR_Sign_01: start 224, 8 bit, little-endian, data-type-policy=OVERRIDE, base-type=uint8, compu {phys=raw}, range phys 0..255
          signal LocalizationInitFBD_HR_Sign_02: start 232, 8 bit, little-endian, data-type-policy=OVERRIDE, base-type=uint8, compu {phys=raw}, range phys 0..255
          signal LocalizationInitFBD_HR_Sign_03: start 240, 8 bit, little-endian, data-type-policy=OVERRIDE, base-type=uint8, compu {phys=raw}, range phys 0..255
          signal LocalizationInitFBD_HR_Sign_04: start 248, 8 bit, little-endian, data-type-policy=OVERRIDE, base-type=uint8, compu {phys=raw}, range phys 0..255
          signal LocalizationInitFBD_HR_Sign_05: start 256, 8 bit, little-endian, data-type-policy=OVERRIDE, base-type=uint8, compu {phys=raw}, range phys 0..255
          signal LocalizationInitFBD_HR_Sign_06: start 264, 8 bit, little-endian, data-type-policy=OVERRIDE, base-type=uint8, compu {phys=raw}, range phys 0..255
          signal LocalizationInitFBD_HR_Sign_07: start 272, 8 bit, little-endian, data-type-policy=OVERRIDE, base-type=uint8, compu {phys=raw}, range phys 0..255
          signal LocalizationInitFBD_HR_Sign_08: start 280, 8 bit, little-endian, data-type-policy=OVERRIDE, base-type=uint8, compu {phys=raw}, range phys 0..255
          signal LocalizationInitFBD_HR_Sign_09: start 288, 8 bit, little-endian, data-type-policy=OVERRIDE, base-type=uint8, compu {phys=raw}, range phys 0..255
          signal LocalizationInitFBD_HR_Sign_10: start 296, 8 bit, little-endian, data-type-policy=OVERRIDE, base-type=uint8, compu {phys=raw}, range phys 0..255
          signal LocalizationInitFBD_HR_Sign_11: start 304, 8 bit, little-endian, data-type-policy=OVERRIDE, base-type=uint8, compu {phys=raw}, range phys 0..255
          signal LocalizationInitFBD_HR_Sign_12: start 312, 8 bit, little-endian, data-type-policy=OVERRIDE, base-type=uint8, compu {phys=raw}, range phys 0..255
          signal LocalizationInitFBD_HR_Sign_13: start 320, 8 bit, little-endian, data-type-policy=OVERRIDE, base-type=uint8, compu {phys=raw}, range phys 0..255
          signal LocalizationInitFBD_HR_Sign_14: start 328, 8 bit, little-endian, data-type-policy=OVERRIDE, base-type=uint8, compu {phys=raw}, range phys 0..255
          signal LocalizationInitFBD_HR_Sign_15: start 336, 8 bit, little-endian, data-type-policy=OVERRIDE, base-type=uint8, compu {phys=raw}, range phys 0..255
          signal LocalizationInitFBD_HR_RangingRoundIndex_0: start 344, 8 bit, little-endian, data-type-policy=OVERRIDE, base-type=uint8, compu {phys=raw}, range phys 0..255
          signal LocalizationInitFBD_HR_RangingRoundIndex_1: start 352, 8 bit, little-endian, data-type-policy=OVERRIDE, base-type=uint8, compu {phys=raw}, range phys 0..255
          signal LocalizationInitFBD_HR_RangingRoundIndex_2: start 360, 8 bit, little-endian, data-type-policy=OVERRIDE, base-type=uint8, compu {phys=raw}, range phys 0..255
          signal LocalizationInitFBD_HR_RangingRoundIndex_3: start 368, 8 bit, little-endian, data-type-policy=OVERRIDE, base-type=uint8, compu {phys=raw}, range phys 0..255
          signal LocalizationInitFBD_HR_RangingRoundIndex_4: start 376, 8 bit, little-endian, data-type-policy=OVERRIDE, base-type=uint8, compu {phys=raw}, range phys 0..255
      frame LocalizationInitFBD_Miko: id 0x228, frame-length=48, can-addressing-mode=STANDARD, can-frame-rx-behavior=CAN-FD, can-frame-tx-behavior=CAN-FD
        pdu LocalizationInitFBD_Miko: length=48, unused-bit-pattern=0
          signal LocalizationInitFBD_Miko_IRKListIndex: start 0, 8 bit, little-endian, data-type-policy=OVERRIDE, base-type=uint8, compu {phys=raw}, range phys 0..252
          signal LocalizationInitFBD_Miko_ZoneEntry: start 8, 8 bit, little-endian, data-type-policy=OVERRIDE, base-type=uint8, compu {phys=raw}, range phys 0..252
          signal LocalizationInitFBD_Miko_RangingBlockIndex_0: start 16, 16 bit, little-endian, data-type-policy=OVERRIDE, base-type=uint16, compu {phys=raw}, range phys 0..65532
          signal LocalizationInitFBD_Miko_TimeOfFlight_0: start 32, 16 bit, little-endian, data-type-policy=OVERRIDE, base-type=uint16, compu {phys=raw*15.65; unit ps}, range phys 0..1000000
          signal LocalizationInitFBD_Miko_RSSI_0: start 48, 8 bit, little-endian, data-type-policy=OVERRIDE, base-type=uint8, compu {phys=raw-90; unit °}, range phys -90..90
          signal LocalizationInitFBD_Miko_RangingBlockIndex_1: start 56, 16 bit, little-endian, data-type-policy=OVERRIDE, base-type=uint16, compu {phys=raw}, range phys 0..65532
          signal LocalizationInitFBD_Miko_TimeOfFlight_1: start 72, 16 bit, little-endian, data-type-policy=OVERRIDE, base-type=uint16, compu {phys=raw*15.65; unit ps}, range phys 0..1000000
          signal LocalizationInitFBD_Miko_RSSI_1: start 88, 8 bit, little-endian, data-type-policy=OVERRIDE, base-type=uint8, compu {phys=raw-90; unit °}, range phys -90..90
          signal LocalizationInitFBD_Miko_RangingBlockIndex_2: start 96, 16 bit, little-endian, data-type-policy=OVERRIDE, base-type=uint16, compu {phys=raw}, range phys 0..65532
          signal LocalizationInitFBD_Miko_TimeOfFlight_2: start 112, 16 bit, little-endian, data-type-policy=OVERRIDE, base-type=uint16, compu {phys=raw*15.65; unit ps}, range phys 0..1000000
          signal LocalizationInitFBD_Miko_RSSI_2: start 128, 8 bit, little-endian, data-type-policy=OVERRIDE, base-type=uint8, compu {phys=raw-90; unit °}, range phys -90..90
          signal LocalizationInitFBD_Miko_RangingBlockIndex_3: start 136, 16 bit, little-endian, data-type-policy=OVERRIDE, base-type=uint16, compu {phys=raw}, range phys 0..65532
          signal LocalizationInitFBD_Miko_TimeOfFlight_3: start 152, 16 bit, little-endian, data-type-policy=OVERRIDE, base-type=uint16, compu {phys=raw*15.65; unit ps}, range phys 0..1000000
          signal LocalizationInitFBD_Miko_RSSI_3: start 168, 8 bit, little-endian, data-type-policy=OVERRIDE, base-type=uint8, compu {phys=raw-90; unit °}, range phys -90..90
          signal LocalizationInitFBD_Miko_RangingBlockIndex_4: start 176, 16 bit, little-endian, data-type-policy=OVERRIDE, base-type=uint16, compu {phys=raw}, range phys 0..65532
          signal LocalizationInitFBD_Miko_TimeOfFlight_4: start 192, 16 bit, little-endian, data-type-policy=OVERRIDE, base-type=uint16, compu {phys=raw*15.65; unit ps}, range phys 0..1000000
          signal LocalizationInitFBD_Miko_RSSI_4: start 208, 8 bit, little-endian, data-type-policy=OVERRIDE, base-type=uint8, compu {phys=raw-90; unit °}, range phys -90..90
          signal LocalizationInitFBD_Miko_Sign_00: start 216, 8 bit, little-endian, data-type-policy=OVERRIDE, base-type=uint8, compu {phys=raw}, range phys 0..255
          signal LocalizationInitFBD_Miko_Sign_01: start 224, 8 bit, little-endian, data-type-policy=OVERRIDE, base-type=uint8, compu {phys=raw}, range phys 0..255
          signal LocalizationInitFBD_Miko_Sign_02: start 232, 8 bit, little-endian, data-type-policy=OVERRIDE, base-type=uint8, compu {phys=raw}, range phys 0..255
          signal LocalizationInitFBD_Miko_Sign_03: start 240, 8 bit, little-endian, data-type-policy=OVERRIDE, base-type=uint8, compu {phys=raw}, range phys 0..255
          signal LocalizationInitFBD_Miko_Sign_04: start 248, 8 bit, little-endian, data-type-policy=OVERRIDE, base-type=uint8, compu {phys=raw}, range phys 0..255
          signal LocalizationInitFBD_Miko_Sign_05: start 256, 8 bit, little-endian, data-type-policy=OVERRIDE, base-type=uint8, compu {phys=raw}, range phys 0..255
          signal LocalizationInitFBD_Miko_Sign_06: start 264, 8 bit, little-endian, data-type-policy=OVERRIDE, base-type=uint8, compu {phys=raw}, range phys 0..255
          signal LocalizationInitFBD_Miko_Sign_07: start 272, 8 bit, little-endian, data-type-policy=OVERRIDE, base-type=uint8, compu {phys=raw}, range phys 0..255
          signal LocalizationInitFBD_Miko_Sign_08: start 280, 8 bit, little-endian, data-type-policy=OVERRIDE, base-type=uint8, compu {phys=raw}, range phys 0..255
          signal LocalizationInitFBD_Miko_Sign_09: start 288, 8 bit, little-endian, data-type-policy=OVERRIDE, base-type=uint8, compu {phys=raw}, range phys 0..255
          signal LocalizationInitFBD_Miko_Sign_10: start 296, 8 bit, little-endian, data-type-policy=OVERRIDE, base-type=uint8, compu {phys=raw}, range phys 0..255
          signal LocalizationInitFBD_Miko_Sign_11: start 304, 8 bit, little-endian, data-type-policy=OVERRIDE, base-type=uint8, compu {phys=raw}, range phys 0..255
          signal LocalizationInitFBD_Miko_Sign_12: start 312, 8 bit, little-endian, data-type-policy=OVERRIDE, base-type=uint8, compu {phys=raw}, range phys 0..255
          signal LocalizationInitFBD_Miko_Sign_13: start 320, 8 bit, little-endian, data-type-policy=OVERRIDE, base-type=uint8, compu {phys=raw}, range phys 0..255
          signal LocalizationInitFBD_Miko_Sign_14: start 328, 8 bit, little-endian, data-type-policy=OVERRIDE, base-type=uint8, compu {phys=raw}, range phys 0..255
          signal LocalizationInitFBD_Miko_Sign_15: start 336, 8 bit, little-endian, data-type-policy=OVERRIDE, base-type=uint8, compu {phys=raw}, range phys 0..255
          signal LocalizationInitFBD_Miko_RangingRoundIndex_0: start 344, 8 bit, little-endian, data-type-policy=OVERRIDE, base-type=uint8, compu {phys=raw}, range phys 0..255
          signal LocalizationInitFBD_Miko_RangingRoundIndex_1: start 352, 8 bit, little-endian, data-type-policy=OVERRIDE, base-type=uint8, compu {phys=raw}, range phys 0..255
          signal LocalizationInitFBD_Miko_RangingRoundIndex_2: start 360, 8 bit, little-endian, data-type-policy=OVERRIDE, base-type=uint8, compu {phys=raw}, range phys 0..255
          signal LocalizationInitFBD_Miko_RangingRoundIndex_3: start 368, 8 bit, little-endian, data-type-policy=OVERRIDE, base-type=uint8, compu {phys=raw}, range phys 0..255
          signal LocalizationInitFBD_Miko_RangingRoundIndex_4: start 376, 8 bit, little-endian, data-type-policy=OVERRIDE, base-type=uint8, compu {phys=raw}, range phys 0..255
      frame LocalizationInitFBD_MM: id 0x230, frame-length=48, can-addressing-mode=STANDARD, can-frame-rx-behavior=CAN-FD, can-frame-tx-behavior=CAN-FD
        pdu LocalizationInitFBD_MM: length=48, unused-bit-pattern=0
          signal LocalizationInitFBD_MM_IRKListIndex: start 0, 8 bit, little-endian, data-type-policy=OVERRIDE, base-type=uint8, compu {phys=raw}, range phys 0..252
          signal LocalizationInitFBD_MM_ZoneEntry: start 8, 8 bit, little-endian, data-type-policy=OVERRIDE, base-type=uint8, compu {phys=raw}, range phys 0..252
          signal LocalizationInitFBD_MM_RangingBlockIndex_0: start 16, 16 bit, little-endian, data-type-policy=OVERRIDE, base-type=uint16, compu {phys=raw}, range phys 0..65532
          signal LocalizationInitFBD_MM_TimeOfFlight_0: start 32, 16 bit, little-endian, data-type-policy=OVERRIDE, base-type=uint16, compu {phys=raw*15.65; unit ps}, range phys 0..1000000
          signal LocalizationInitFBD_MM_RSSI_0: start 48, 8 bit, little-endian, data-type-policy=OVERRIDE, base-type=uint8, compu {phys=raw-90; unit °}, range phys -90..90
          signal LocalizationInitFBD_MM_RangingBlockIndex_1: start 56, 16 bit, little-endian, data-type-policy=OVERRIDE, base-type=uint16, compu {phys=raw}, range phys 0..65532
          signal LocalizationInitFBD_MM_TimeOfFlight_1: start 72, 16 bit, little-endian, data-type-policy=OVERRIDE, base-type=uint16, compu {phys=raw*15.65; unit ps}, range phys 0..1000000
          signal LocalizationInitFBD_MM_RSSI_1: start 88, 8 bit, little-endian, data-type-policy=OVERRIDE, base-type=uint8, compu {phys=raw-90; unit °}, range phys -90..90
          signal LocalizationInitFBD_MM_RangingBlockIndex_2: start 96, 16 bit, little-endian, data-type-policy=OVERRIDE, base-type=uint16, compu {phys=raw}, range phys 0..65532
          signal LocalizationInitFBD_MM_TimeOfFlight_2: start 112, 16 bit, little-endian, data-type-policy=OVERRIDE, base-type=uint16, compu {phys=raw*15.65; unit ps}, range phys 0..1000000
          signal LocalizationInitFBD_MM_RSSI_2: start 128, 8 bit, little-endian, data-type-policy=OVERRIDE, base-type=uint8, compu {phys=raw-90; unit °}, range phys -90..90
          signal LocalizationInitFBD_MM_RangingBlockIndex_3: start 136, 16 bit, little-endian, data-type-policy=OVERRIDE, base-type=uint16, compu {phys=raw}, range phys 0..65532
          signal LocalizationInitFBD_MM_TimeOfFlight_3: start 152, 16 bit, little-endian, data-type-policy=OVERRIDE, base-type=uint16, compu {phys=raw*15.65; unit ps}, range phys 0..1000000
          signal LocalizationInitFBD_MM_RSSI_3: start 168, 8 bit, little-endian, data-type-policy=OVERRIDE, base-type=uint8, compu {phys=raw-90; unit °}, range phys -90..90
          signal LocalizationInitFBD_MM_RangingBlockIndex_4: start 176, 16 bit, little-endian, data-type-policy=OVERRIDE, base-type=uint16, compu {phys=raw}, range phys 0..65532
          signal LocalizationInitFBD_MM_TimeOfFlight_4: start 192, 16 bit, little-endian, data-type-policy=OVERRIDE, base-type=uint16, compu {phys=raw*15.65; unit ps}, range phys 0..1000000
          signal LocalizationInitFBD_MM_RSSI_4: start 208, 8 bit, little-endian, data-type-policy=OVERRIDE, base-type=uint8, compu {phys=raw-90; unit °}, range phys -90..90
          signal LocalizationInitFBD_MM_Sign_00: start 216, 8 bit, little-endian, data-type-policy=OVERRIDE, base-type=uint8, compu {phys=raw}, range phys 0..255
          signal LocalizationInitFBD_MM_Sign_01: start 224, 8 bit, little-endian, data-type-policy=OVERRIDE, base-type=uint8, compu {phys=raw}, range phys 0..255
          signal LocalizationInitFBD_MM_Sign_02: start 232, 8 bit, little-endian, data-type-policy=OVERRIDE, base-type=uint8, compu {phys=raw}, range phys 0..255
          signal LocalizationInitFBD_MM_Sign_03: start 240, 8 bit, little-endian, data-type-policy=OVERRIDE, base-type=uint8, compu {phys=raw}, range phys 0..255
          signal LocalizationInitFBD_MM_Sign_04: start 248, 8 bit, little-endian, data-type-policy=OVERRIDE, base-type=uint8, compu {phys=raw}, range phys 0..255
          signal LocalizationInitFBD_MM_Sign_05: start 256, 8 bit, little-endian, data-type-policy=OVERRIDE, base-type=uint8, compu {phys=raw}, range phys 0..255
          signal LocalizationInitFBD_MM_Sign_06: start 264, 8 bit, little-endian, data-type-policy=OVERRIDE, base-type=uint8, compu {phys=raw}, range phys 0..255
          signal LocalizationInitFBD_MM_Sign_07: start 272, 8 bit, little-endian, data-type-policy=OVERRIDE, base-type=uint8, compu {phys=raw}, range phys 0..255
          signal LocalizationInitFBD_MM_Sign_08: start 280, 8 bit, little-endian, data-type-policy=OVERRIDE, base-type=uint8, compu {phys=raw}, range phys 0..255
          signal LocalizationInitFBD_MM_Sign_09: start 288, 8 bit, little-endian, data-type-policy=OVERRIDE, base-type=uint8, compu {phys=raw}, range phys 0..255
          signal LocalizationInitFBD_MM_Sign_10: start 296, 8 bit, little-endian, data-type-policy=OVERRIDE, base-type=uint8, compu {phys=raw}, range phys 0..255
          signal LocalizationInitFBD_MM_Sign_11: start 304, 8 bit, little-endian, data-type-policy=OVERRIDE, base-type=uint8, compu {phys=raw}, range phys 0..255
          signal LocalizationInitFBD_MM_Sign_12: start 312, 8 bit, little-endian, data-type-policy=OVERRIDE, base-type=uint8, compu {phys=raw}, range phys 0..255
          signal LocalizationInitFBD_MM_Sign_13: start 320, 8 bit, little-endian, data-type-policy=OVERRIDE, base-type=uint8, compu {phys=raw}, range phys 0..255
          signal LocalizationInitFBD_MM_Sign_14: start 328, 8 bit, little-endian, data-type-policy=OVERRIDE, base-type=uint8, compu {phys=raw}, range phys 0..255
          signal LocalizationInitFBD_MM_Sign_15: start 336, 8 bit, little-endian, data-type-policy=OVERRIDE, base-type=uint8, compu {phys=raw}, range phys 0..255
          signal LocalizationInitFBD_MM_RangingRoundIndex_0: start 344, 8 bit, little-endian, data-type-policy=OVERRIDE, base-type=uint8, compu {phys=raw}, range phys 0..255
          signal LocalizationInitFBD_MM_RangingRoundIndex_1: start 352, 8 bit, little-endian, data-type-policy=OVERRIDE, base-type=uint8, compu {phys=raw}, range phys 0..255
          signal LocalizationInitFBD_MM_RangingRoundIndex_2: start 360, 8 bit, little-endian, data-type-policy=OVERRIDE, base-type=uint8, compu {phys=raw}, range phys 0..255
          signal LocalizationInitFBD_MM_RangingRoundIndex_3: start 368, 8 bit, little-endian, data-type-policy=OVERRIDE, base-type=uint8, compu {phys=raw}, range phys 0..255
          signal LocalizationInitFBD_MM_RangingRoundIndex_4: start 376, 8 bit, little-endian, data-type-policy=OVERRIDE, base-type=uint8, compu {phys=raw}, range phys 0..255
